VERSION ""

NS_ :

BS_:

BU_: CH DIPF DIPR ETH FC HVI HVS PARTY SDCV VEH VIRT

BO_ 1480 EPBL_alertLog: 8 VEH
 SG_ EPBL_a175_nonterminalReason m175 : 56|5@1+ (1,0) [0|21] ""  gtw
 SG_ EPBL_a248_nonterminalReason m248 : 56|5@1+ (1,0) [0|21] ""  gtw
 SG_ EPBL_a176_nonterminalReason m176 : 56|5@1+ (1,0) [0|21] ""  gtw
 SG_ EPBL_a041_CPULoadNVMMTask m41 : 56|8@1+ (1,0) [0|255] ""  gtw
 SG_ EPBL_a177_nonterminalReason m177 : 56|5@1+ (1,0) [0|21] ""  gtw
 SG_ EPBL_a022_TaskInitError4 m22 : 56|8@1+ (1,0) [0|255] ""  gtw
 SG_ EPBL_a190_nonterminalReason m190 : 56|5@1+ (1,0) [0|21] ""  gtw
 SG_ EPBL_a179_nonterminalReason m179 : 56|5@1+ (1,0) [0|21] ""  gtw
 SG_ EPBL_a174_nonterminalReason m174 : 56|5@1+ (1,0) [0|21] ""  gtw
 SG_ EPBL_a191_nonterminalReason m191 : 56|5@1+ (1,0) [0|21] ""  gtw
 SG_ EPBL_a042_UsageNVMMTask m42 : 56|8@1+ (1,0) [0|255] ""  gtw
 SG_ EPBL_a247_nonterminalReason m247 : 56|5@1+ (1,0) [0|21] ""  gtw
 SG_ EPBL_a138_monitorState m138 : 51|3@1+ (1,0) [0|5] ""  gtw
 SG_ EPBL_a179_esmOpTrigger m179 : 48|5@1+ (1,0) [0|30] ""  gtw
 SG_ EPBL_a000_alertDataW2 m0 : 48|16@1+ (1,0) [0|65535] ""  X
 SG_ EPBL_a022_TaskInitError3 m22 : 48|8@1+ (1,0) [0|255] ""  gtw
 SG_ EPBL_a190_esmOpTrigger m190 : 48|5@1+ (1,0) [0|30] ""  gtw
 SG_ EPBL_a042_UsageUDSTask m42 : 48|8@1+ (1,0) [0|255] ""  gtw
 SG_ EPBL_a248_esmOpTrigger m248 : 48|5@1+ (1,0) [0|30] ""  gtw
 SG_ EPBL_a175_esmOpTrigger m175 : 48|5@1+ (1,0) [0|30] ""  gtw
 SG_ EPBL_a247_esmOpTrigger m247 : 48|5@1+ (1,0) [0|30] ""  gtw
 SG_ EPBL_a191_esmOpTrigger m191 : 48|5@1+ (1,0) [0|30] ""  gtw
 SG_ EPBL_a003_Data m3 : 48|16@1+ (1,0) [0|65535] ""  gtw
 SG_ EPBL_a216_byte3 m216 : 48|8@1+ (1,0) [0|255] ""  gtw
 SG_ EPBL_a176_esmOpTrigger m176 : 48|5@1+ (1,0) [0|30] ""  gtw
 SG_ EPBL_a041_CPULoad1000msTask m41 : 48|8@1+ (1,0) [0|255] ""  gtw
 SG_ EPBL_a138_localState m138 : 48|3@1+ (1,0) [0|5] ""  gtw
 SG_ EPBL_a177_esmOpTrigger m177 : 48|5@1+ (1,0) [0|30] ""  gtw
 SG_ EPBL_a174_esmOpTrigger m174 : 48|5@1+ (1,0) [0|30] ""  gtw
 SG_ EPBL_a183_invalidateReason m183 : 45|2@1+ (1,0) [0|3] ""  gtw
 SG_ EPBL_a063_faulted m63 : 43|1@1+ (1,0) [0|1] ""  gtw
 SG_ EPBL_a063_stuckActive m63 : 42|1@1+ (1,0) [0|1] ""  gtw
 SG_ EPBL_a063_indeterminate m63 : 41|1@1+ (1,0) [0|1] ""  gtw
 SG_ EPBL_a176_csmFaultReason m176 : 40|5@1+ (1,0) [0|21] ""  gtw
 SG_ EPBL_a045_CallTrace1 m45 : 40|24@1+ (1,0) [0|16777215] ""  gtw
 SG_ EPBL_a134_12vFilt m134 : 40|12@1+ (0.005443676098,0) [0|22.29185] "V"  gtw
 SG_ EPBL_a246_esmOpTrigger m246 : 40|5@1+ (1,0) [0|30] ""  gtw
 SG_ EPBL_a170_12vFilt m170 : 40|12@1+ (0.005443676098,0) [0|22.29185] "V"  gtw
 SG_ EPBL_a063_disconnected m63 : 40|1@1+ (1,0) [0|1] ""  gtw
 SG_ EPBL_a042_Usage1000msTask m42 : 40|8@1+ (1,0) [0|255] ""  gtw
 SG_ EPBL_a188_nextState m188 : 40|5@1+ (1,0) [0|19] ""  gtw
 SG_ EPBL_a128_12vFilt m128 : 40|12@1+ (0.005443676098,0) [0|22.29185] "V"  gtw
 SG_ EPBL_a191_csmFaultReason m191 : 40|5@1+ (1,0) [0|21] ""  gtw
 SG_ EPBL_a183_nextState m183 : 40|5@1+ (1,0) [0|19] ""  gtw
 SG_ EPBL_a247_csmFaultReason m247 : 40|5@1+ (1,0) [0|21] ""  gtw
 SG_ EPBL_a137_12vFilt m137 : 40|12@1+ (0.005443676098,0) [0|22.29185] "V"  gtw
 SG_ EPBL_a175_csmFaultReason m175 : 40|5@1+ (1,0) [0|21] ""  gtw
 SG_ EPBL_a189_nextState m189 : 40|5@1+ (1,0) [0|19] ""  gtw
 SG_ EPBL_a046_CallTrace1 m46 : 40|24@1+ (1,0) [0|16777215] ""  gtw
 SG_ EPBL_a216_byte2 m216 : 40|8@1+ (1,0) [0|255] ""  gtw
 SG_ EPBL_a184_nextState m184 : 40|5@1+ (1,0) [0|19] ""  gtw
 SG_ EPBL_a248_csmFaultReason m248 : 40|5@1+ (1,0) [0|21] ""  gtw
 SG_ EPBL_a059_current m59 : 40|12@1+ (0.05,0) [0|204.75] "A"  gtw
 SG_ EPBL_a043_CallTrace1 m43 : 40|24@1+ (1,0) [0|16777215] ""  gtw
 SG_ EPBL_a136_12vFilt m136 : 40|12@1+ (0.005443676098,0) [0|22.29185] "V"  gtw
 SG_ EPBL_a249_esmOpTrigger m249 : 40|5@1+ (1,0) [0|30] ""  gtw
 SG_ EPBL_a190_csmFaultReason m190 : 40|5@1+ (1,0) [0|21] ""  gtw
 SG_ EPBL_a179_csmFaultReason m179 : 40|5@1+ (1,0) [0|21] ""  gtw
 SG_ EPBL_a125_12vFilt m125 : 40|12@1+ (0.005443676098,0) [0|22.29185] "V"  gtw
 SG_ EPBL_a217_byte7 m217 : 40|8@1+ (1,0) [0|255] ""  gtw
 SG_ EPBL_a174_csmFaultReason m174 : 40|5@1+ (1,0) [0|21] ""  gtw
 SG_ EPBL_a180_nextState m180 : 40|5@1+ (1,0) [0|19] ""  gtw
 SG_ EPBL_a044_CallTrace1 m44 : 40|24@1+ (1,0) [0|16777215] ""  gtw
 SG_ EPBL_a177_csmFaultReason m177 : 40|5@1+ (1,0) [0|21] ""  gtw
 SG_ EPBL_a126_12vFilt m126 : 40|12@1+ (0.005443676098,0) [0|22.29185] "V"  gtw
 SG_ EPBL_a041_CPULoad100msTask m41 : 40|8@1+ (1,0) [0|255] ""  gtw
 SG_ EPBL_a186_nextState m186 : 40|5@1+ (1,0) [0|19] ""  gtw
 SG_ EPBL_a022_TaskInitError2 m22 : 40|8@1+ (1,0) [0|255] ""  gtw
 SG_ EPBL_a171_12vFilt m171 : 40|12@1+ (0.005443676098,0) [0|22.29185] "V"  gtw
 SG_ EPBL_a135_12vFilt m135 : 40|12@1+ (0.005443676098,0) [0|22.29185] "V"  gtw
 SG_ EPBL_a187_nextState m187 : 40|5@1+ (1,0) [0|19] ""  gtw
 SG_ EPBL_a127_12vFilt m127 : 40|12@1+ (0.005443676098,0) [0|22.29185] "V"  gtw
 SG_ EPBL_a247_monitorFaultStatus m247 : 37|2@1+ (1,0) [0|3] ""  gtw
 SG_ EPBL_a191_monitorFaultStatus m191 : 37|2@1+ (1,0) [0|3] ""  gtw
 SG_ EPBL_a175_monitorFaultStatus m175 : 37|2@1+ (1,0) [0|3] ""  gtw
 SG_ EPBL_a176_monitorFaultStatus m176 : 37|2@1+ (1,0) [0|3] ""  gtw
 SG_ EPBL_a179_monitorFaultStatus m179 : 37|2@1+ (1,0) [0|3] ""  gtw
 SG_ EPBL_a246_faultStatus m246 : 37|2@1+ (1,0) [0|3] ""  gtw
 SG_ EPBL_a177_monitorFaultStatus m177 : 37|2@1+ (1,0) [0|3] ""  gtw
 SG_ EPBL_a248_monitorFaultStatus m248 : 37|2@1+ (1,0) [0|3] ""  gtw
 SG_ EPBL_a249_faultStatus m249 : 37|2@1+ (1,0) [0|3] ""  gtw
 SG_ EPBL_a190_monitorFaultStatus m190 : 37|2@1+ (1,0) [0|3] ""  gtw
 SG_ EPBL_a174_monitorFaultStatus m174 : 37|2@1+ (1,0) [0|3] ""  gtw
 SG_ EPBL_a183_previousState m183 : 32|5@1+ (1,0) [0|19] ""  gtw
 SG_ EPBL_a186_previousState m186 : 32|5@1+ (1,0) [0|19] ""  gtw
 SG_ EPBL_a063_ADCVoltage m63 : 32|8@1+ (0.025,0) [0|6.375] "V"  gtw
 SG_ EPBL_a179_monitorUnitStatus m179 : 32|5@1+ (1,0) [0|21] ""  gtw
 SG_ EPBL_a042_Usage100msTask m42 : 32|8@1+ (1,0) [0|255] ""  gtw
 SG_ EPBL_a191_monitorUnitStatus m191 : 32|5@1+ (1,0) [0|21] ""  gtw
 SG_ EPBL_a182_temperature m182 : 32|8@1- (0.5,-40) [-40|80] "deg C"  gtw
 SG_ EPBL_a247_monitorUnitStatus m247 : 32|5@1+ (1,0) [0|21] ""  gtw
 SG_ EPBL_a180_previousState m180 : 32|5@1+ (1,0) [0|19] ""  gtw
 SG_ EPBL_a173_csmState m173 : 32|4@1+ (1,0) [0|14] ""  gtw
 SG_ EPBL_a187_previousState m187 : 32|5@1+ (1,0) [0|19] ""  gtw
 SG_ EPBL_a246_esmStateRequest m246 : 32|5@1+ (1,0) [0|19] ""  gtw
 SG_ EPBL_a175_monitorUnitStatus m175 : 32|5@1+ (1,0) [0|21] ""  gtw
 SG_ EPBL_a022_TaskInitError1 m22 : 32|8@1+ (1,0) [0|255] ""  gtw
 SG_ EPBL_a190_monitorUnitStatus m190 : 32|5@1+ (1,0) [0|21] ""  gtw
 SG_ EPBL_a184_previousState m184 : 32|5@1+ (1,0) [0|19] ""  gtw
 SG_ EPBL_a174_monitorUnitStatus m174 : 32|5@1+ (1,0) [0|21] ""  gtw
 SG_ EPBL_a249_esmStateRequest m249 : 32|5@1+ (1,0) [0|19] ""  gtw
 SG_ EPBL_a188_previousState m188 : 32|5@1+ (1,0) [0|19] ""  gtw
 SG_ EPBL_a177_monitorUnitStatus m177 : 32|5@1+ (1,0) [0|21] ""  gtw
 SG_ EPBL_a041_CPULoad10msTask m41 : 32|8@1+ (1,0) [0|255] ""  gtw
 SG_ EPBL_a000_alertDataW1 m0 : 32|16@1+ (1,0) [0|65535] ""  X
 SG_ EPBL_a217_byte6 m217 : 32|8@1+ (1,0) [0|255] ""  gtw
 SG_ EPBL_a248_monitorUnitStatus m248 : 32|5@1+ (1,0) [0|21] ""  gtw
 SG_ EPBL_a176_monitorUnitStatus m176 : 32|5@1+ (1,0) [0|21] ""  gtw
 SG_ EPBL_a003_LineNumber m3 : 32|16@1+ (1,0) [0|65535] ""  gtw
 SG_ EPBL_a189_previousState m189 : 32|5@1+ (1,0) [0|19] ""  gtw
 SG_ EPBL_a216_byte1 m216 : 32|8@1+ (1,0) [0|255] ""  gtw
 SG_ EPBL_a179_faultStatus m179 : 29|2@1+ (1,0) [0|3] ""  gtw
 SG_ EPBL_a191_faultStatus m191 : 29|2@1+ (1,0) [0|3] ""  gtw
 SG_ EPBL_a247_faultStatus m247 : 29|2@1+ (1,0) [0|3] ""  gtw
 SG_ EPBL_a175_faultStatus m175 : 29|2@1+ (1,0) [0|3] ""  gtw
 SG_ EPBL_a190_faultStatus m190 : 29|2@1+ (1,0) [0|3] ""  gtw
 SG_ EPBL_a174_faultStatus m174 : 29|2@1+ (1,0) [0|3] ""  gtw
 SG_ EPBL_a177_faultStatus m177 : 29|2@1+ (1,0) [0|3] ""  gtw
 SG_ EPBL_a248_faultStatus m248 : 29|2@1+ (1,0) [0|3] ""  gtw
 SG_ EPBL_a176_faultStatus m176 : 29|2@1+ (1,0) [0|3] ""  gtw
 SG_ EPBL_a136_nvFilt m136 : 28|12@1+ (0.005443676098,0) [0|22.29185] "V"  gtw
 SG_ EPBL_a128_nvFilt m128 : 28|12@1+ (0.005443676098,0) [0|22.29185] "V"  gtw
 SG_ EPBL_a125_nvFilt m125 : 28|12@1+ (0.005443676098,0) [0|22.29185] "V"  gtw
 SG_ EPBL_a126_nvFilt m126 : 28|12@1+ (0.005443676098,0) [0|22.29185] "V"  gtw
 SG_ EPBL_a135_nvFilt m135 : 28|12@1+ (0.005443676098,0) [0|22.29185] "V"  gtw
 SG_ EPBL_a171_nvFilt m171 : 28|12@1+ (0.005443676098,0) [0|22.29185] "V"  gtw
 SG_ EPBL_a127_nvFilt m127 : 28|12@1+ (0.005443676098,0) [0|22.29185] "V"  gtw
 SG_ EPBL_a059_resistanceEstimate m59 : 28|12@1+ (0.00244,0) [0|9.9918] "Ohms"  gtw
 SG_ EPBL_a134_nvFilt m134 : 28|12@1+ (0.005443676098,0) [0|22.29185] "V"  gtw
 SG_ EPBL_a170_nvFilt m170 : 28|12@1+ (0.005443676098,0) [0|22.29185] "V"  gtw
 SG_ EPBL_a137_nvFilt m137 : 28|12@1+ (0.005443676098,0) [0|22.29185] "V"  gtw
 SG_ EPBL_a021_Task1000msMissed m21 : 27|1@1+ (1,0) [0|1] ""  gtw
 SG_ EPBL_a116_VEH_logging1Hz m116 : 27|1@1+ (1,0) [0|1] ""  gtw
 SG_ EPBL_a242_highCurrent m242 : 26|2@1+ (1,0) [0|3] ""  gtw
 SG_ EPBL_a116_VEH_switchStatus m116 : 26|1@1+ (1,0) [0|1] ""  gtw
 SG_ EPBL_a021_Task1000msStarved m21 : 26|1@1+ (1,0) [0|1] ""  gtw
 SG_ EPBL_a243_brakeDiscWipingActive m243 : 26|1@1+ (1,0) [0|1] ""  gtw
 SG_ EPBL_a241_highCurrent m241 : 26|2@1+ (1,0) [0|3] ""  gtw
 SG_ EPBL_a117_VEH_intrusionSensorSta m117 : 25|1@1+ (1,0) [0|1] ""  gtw
 SG_ EPBL_a021_Task1000msLate m21 : 25|1@1+ (1,0) [0|1] ""  gtw
 SG_ EPBL_a243_vehiclePowerState m243 : 25|1@1+ (1,0) [0|1] ""  gtw
 SG_ EPBL_a116_VEH_restraintStatus m116 : 25|1@1+ (1,0) [0|1] ""  gtw
 SG_ EPBL_a217_byte5 m217 : 24|8@1+ (1,0) [0|255] ""  gtw
 SG_ EPBL_a243_wiperSpeed m243 : 24|1@1+ (1,0) [0|1] ""  gtw
 SG_ EPBL_a189_esmOpTrigger m189 : 24|5@1+ (1,0) [0|30] ""  gtw
 SG_ EPBL_a177_esmStateRequest m177 : 24|5@1+ (1,0) [0|19] ""  gtw
 SG_ EPBL_a242_vehiclePowerState m242 : 24|2@1+ (1,0) [0|3] ""  gtw
 SG_ EPBL_a042_Usage10msTask m42 : 24|8@1+ (1,0) [0|255] ""  gtw
 SG_ EPBL_a184_esmOpTrigger m184 : 24|5@1+ (1,0) [0|30] ""  gtw
 SG_ EPBL_a179_esmStateRequest m179 : 24|5@1+ (1,0) [0|19] ""  gtw
 SG_ EPBL_a187_esmOpTrigger m187 : 24|5@1+ (1,0) [0|30] ""  gtw
 SG_ EPBL_a022_TaskInitError0 m22 : 24|8@1+ (1,0) [0|255] ""  gtw
 SG_ EPBL_a063_switchType m63 : 24|8@1+ (1,0) [0|255] ""  gtw
 SG_ EPBL_a174_esmStateRequest m174 : 24|5@1+ (1,0) [0|19] ""  gtw
 SG_ EPBL_a241_vehiclePowerState m241 : 24|2@1+ (1,0) [0|3] ""  gtw
 SG_ EPBL_a113_VEH_powertrainControl m113 : 24|1@1+ (1,0) [0|1] ""  gtw
 SG_ EPBL_a246_nextState m246 : 24|5@1+ (1,0) [0|19] ""  gtw
 SG_ EPBL_a173_esmStateRequest m173 : 24|5@1+ (1,0) [0|19] ""  gtw
 SG_ EPBL_a120_VEH_speed m120 : 24|1@1+ (1,0) [0|1] ""  gtw
 SG_ EPBL_a118_VEH_systemStatus m118 : 24|1@1+ (1,0) [0|1] ""  gtw
 SG_ EPBL_a117_VEH_switchStatus m117 : 24|1@1+ (1,0) [0|1] ""  gtw
 SG_ EPBL_a116_VEH_seatHeatStatus m116 : 24|1@1+ (1,0) [0|1] ""  gtw
 SG_ EPBL_a190_esmStateRequest m190 : 24|5@1+ (1,0) [0|19] ""  gtw
 SG_ EPBL_a188_esmOpTrigger m188 : 24|5@1+ (1,0) [0|30] ""  gtw
 SG_ EPBL_a182_grade m182 : 24|7@1- (1,0) [-64|63] "%"  gtw
 SG_ EPBL_a175_esmStateRequest m175 : 24|5@1+ (1,0) [0|19] ""  gtw
 SG_ EPBL_a186_esmOpTrigger m186 : 24|5@1+ (1,0) [0|30] ""  gtw
 SG_ EPBL_a248_esmStateRequest m248 : 24|5@1+ (1,0) [0|19] ""  gtw
 SG_ EPBL_a247_esmStateRequest m247 : 24|5@1+ (1,0) [0|19] ""  gtw
 SG_ EPBL_a021_Task100msMissed m21 : 24|1@1+ (1,0) [0|1] ""  gtw
 SG_ EPBL_a191_esmStateRequest m191 : 24|5@1+ (1,0) [0|19] ""  gtw
 SG_ EPBL_a249_nextState m249 : 24|5@1+ (1,0) [0|19] ""  gtw
 SG_ EPBL_a216_byte0 m216 : 24|8@1+ (1,0) [0|255] ""  gtw
 SG_ EPBL_a300_subUsageId m300 : 24|5@1+ (1,0) [0|19] ""  gtw
 SG_ EPBL_a041_CPULoad1msTask m41 : 24|8@1+ (1,0) [0|255] ""  gtw
 SG_ EPBL_a141_toState m141 : 24|5@1+ (1,0) [0|19] ""  gtw
 SG_ EPBL_a176_esmStateRequest m176 : 24|5@1+ (1,0) [0|19] ""  gtw
 SG_ EPBL_a180_esmOpTrigger m180 : 24|5@1+ (1,0) [0|30] ""  gtw
 SG_ EPBL_a183_esmOpTrigger m183 : 24|5@1+ (1,0) [0|30] ""  gtw
 SG_ EPBL_a116_VEH_doorStatus m116 : 23|1@1+ (1,0) [0|1] ""  gtw
 SG_ EPBL_a243_thermistorTMin m243 : 23|1@1+ (1,0) [0|1] ""  gtw
 SG_ EPBL_a118_VEH_12VBattStatus m118 : 23|1@1+ (1,0) [0|1] ""  gtw
 SG_ EPBL_a117_VEH_doorStatus m117 : 23|1@1+ (1,0) [0|1] ""  gtw
 SG_ EPBL_a021_Task100msStarved m21 : 23|1@1+ (1,0) [0|1] ""  gtw
 SG_ EPBL_a113_VEH_chassisControl m113 : 23|1@1+ (1,0) [0|1] ""  gtw
 SG_ EPBL_a120_PARTY_speed m120 : 23|1@1+ (1,0) [0|1] ""  gtw
 SG_ EPBL_a120_VEH_status m120 : 22|1@1+ (1,0) [0|1] ""  gtw
 SG_ EPBL_a117_VEH_seatStatus m117 : 22|1@1+ (1,0) [0|1] ""  gtw
 SG_ EPBL_a243_tempAmbient m243 : 22|1@1+ (1,0) [0|1] ""  gtw
 SG_ EPBL_a116_VEH_thsStatus m116 : 22|1@1+ (1,0) [0|1] ""  gtw
 SG_ EPBL_a113_VEH_ventCntlReq m113 : 22|1@1+ (1,0) [0|1] ""  gtw
 SG_ EPBL_a021_Task100msLate m21 : 22|1@1+ (1,0) [0|1] ""  gtw
 SG_ EPBL_a118_VEH_vehicleStatus m118 : 22|1@1+ (1,0) [0|1] ""  gtw
 SG_ EPBL_a021_Task10msMissed m21 : 21|1@1+ (1,0) [0|1] ""  gtw
 SG_ EPBL_a113_VEH_solarData m113 : 21|1@1+ (1,0) [0|1] ""  gtw
 SG_ EPBL_a015_NVMMWriteFailed m15 : 21|1@1+ (1,0) [0|1] ""  gtw
 SG_ EPBL_a116_VEH_seatStatus m116 : 21|1@1+ (1,0) [0|1] ""  gtw
 SG_ EPBL_a118_VEH_LVPowerState m118 : 21|1@1+ (1,0) [0|1] ""  gtw
 SG_ EPBL_a012_ExternalReset m12 : 21|1@1+ (1,0) [0|1] ""  gtw
 SG_ EPBL_a117_VEH_lightStatus m117 : 21|1@1+ (1,0) [0|1] ""  gtw
 SG_ EPBL_a243_vehicleSpeed m243 : 21|1@1+ (1,0) [0|1] ""  gtw
 SG_ EPBL_a120_PARTY_locStatus m120 : 21|1@1+ (1,0) [0|1] ""  gtw
 SG_ EPBL_a107_VEH_bmbMinMax m107 : 20|1@1+ (1,0) [0|1] ""  gtw
 SG_ EPBL_a021_Task10msStarved m21 : 20|1@1+ (1,0) [0|1] ""  gtw
 SG_ EPBL_a120_VEH_torque m120 : 20|1@1+ (1,0) [0|1] ""  gtw
 SG_ EPBL_a012_DebugReset m12 : 20|1@1+ (1,0) [0|1] ""  gtw
 SG_ EPBL_a015_NVMMMemOverflow m15 : 20|1@1+ (1,0) [0|1] ""  gtw
 SG_ EPBL_a118_VEH_okToUseHighPwr m118 : 20|1@1+ (1,0) [0|1] ""  gtw
 SG_ EPBL_a113_VEH_vehicleControl2 m113 : 20|1@1+ (1,0) [0|1] ""  gtw
 SG_ EPBL_a117_VEH_restraintStatus m117 : 20|1@1+ (1,0) [0|1] ""  gtw
 SG_ EPBL_a116_VEH_lightStatus m116 : 20|1@1+ (1,0) [0|1] ""  gtw
 SG_ EPBL_a243_DIStorqueActual m243 : 20|1@1+ (1,0) [0|1] ""  gtw
 SG_ EPBL_a242_hvState m242 : 20|3@1+ (1,0) [0|6] ""  gtw
 SG_ EPBL_a216_monitor_MIA m216 : 19|1@1+ (1,0) [0|1] ""  gtw
 SG_ EPBL_a104_PARTY_control m104 : 19|1@1+ (1,0) [0|1] ""  gtw
 SG_ EPBL_a117_VEH_LVPowerState m117 : 19|1@1+ (1,0) [0|1] ""  gtw
 SG_ EPBL_a120_PARTY_torque m120 : 19|1@1+ (1,0) [0|1] ""  gtw
 SG_ EPBL_a109_PARTY_collision m109 : 19|1@1+ (1,0) [0|1] ""  gtw
 SG_ EPBL_a118_VEH_status m118 : 19|1@1+ (1,0) [0|1] ""  gtw
 SG_ EPBL_a108_PARTY_torque m108 : 19|1@1+ (1,0) [0|1] ""  gtw
 SG_ EPBL_a113_VEH_vehicleControl m113 : 19|1@1+ (1,0) [0|1] ""  gtw
 SG_ EPBL_a243_DItorqueActual m243 : 19|1@1+ (1,0) [0|1] ""  gtw
 SG_ EPBL_a242_contCurrentState m242 : 19|1@1+ (1,0) [0|1] ""  gtw
 SG_ EPBL_a116_VEH_LVPowerState m116 : 19|1@1+ (1,0) [0|1] ""  gtw
 SG_ EPBL_a012_CheckstopReset m12 : 19|1@1+ (1,0) [0|1] ""  gtw
 SG_ EPBL_a114_PARTY_party3 m114 : 19|1@1+ (1,0) [0|1] ""  gtw
 SG_ EPBL_a178_monitorCaliperState m178 : 19|3@1+ (1,0) [0|5] ""  gtw
 SG_ EPBL_a021_Task10msLate m21 : 19|1@1+ (1,0) [0|1] ""  gtw
 SG_ EPBL_a241_epbSysStatus m241 : 19|4@1+ (1,0) [0|8] ""  gtw
 SG_ EPBL_a107_VEH_thermalStatus m107 : 19|1@1+ (1,0) [0|1] ""  gtw
 SG_ EPBL_a015_NVMMRecordUpgraded m15 : 19|1@1+ (1,0) [0|1] ""  gtw
 SG_ EPBL_a120_PARTY_systemStatus m120 : 18|1@1+ (1,0) [0|1] ""  gtw
 SG_ EPBL_a106_VEH_thermalStatus m106 : 18|1@1+ (1,0) [0|1] ""  gtw
 SG_ EPBL_a012_SoftwareReset m12 : 18|1@1+ (1,0) [0|1] ""  gtw
 SG_ EPBL_a109_PARTY_nearDeploy m109 : 18|1@1+ (1,0) [0|1] ""  gtw
 SG_ EPBL_a189_monitorCDPStatus m189 : 18|2@1+ (1,0) [0|2] ""  gtw
 SG_ EPBL_a186_monitorCDPStatus m186 : 18|2@1+ (1,0) [0|2] ""  gtw
 SG_ EPBL_a216_CRC_error m216 : 18|1@1+ (1,0) [0|1] ""  gtw
 SG_ EPBL_a102_VEH_sensorStatus m102 : 18|1@1+ (1,0) [0|1] ""  gtw
 SG_ EPBL_a108_VEH_torque m108 : 18|1@1+ (1,0) [0|1] ""  gtw
 SG_ EPBL_a183_monitorCDPStatus m183 : 18|2@1+ (1,0) [0|2] ""  gtw
 SG_ EPBL_a104_VEH_thermalStatus m104 : 18|1@1+ (1,0) [0|1] ""  gtw
 SG_ EPBL_a180_monitorCDPStatus m180 : 18|2@1+ (1,0) [0|2] ""  gtw
 SG_ EPBL_a107_VEH_status m107 : 18|1@1+ (1,0) [0|1] ""  gtw
 SG_ EPBL_a113_VEH_chargeRequest m113 : 18|1@1+ (1,0) [0|1] ""  gtw
 SG_ EPBL_a119_VEH_rightStalk m119 : 18|1@1+ (1,0) [0|1] ""  gtw
 SG_ EPBL_a021_Task1msMissed m21 : 18|1@1+ (1,0) [0|1] ""  gtw
 SG_ EPBL_a187_monitorCDPStatus m187 : 18|2@1+ (1,0) [0|2] ""  gtw
 SG_ EPBL_a110_VEH_time m110 : 18|1@1+ (1,0) [0|1] ""  gtw
 SG_ EPBL_a243_drivetrainType m243 : 18|1@1+ (1,0) [0|1] ""  gtw
 SG_ EPBL_a118_VEH_sensors m118 : 18|1@1+ (1,0) [0|1] ""  gtw
 SG_ EPBL_a184_monitorCDPStatus m184 : 18|2@1+ (1,0) [0|2] ""  gtw
 SG_ EPBL_a103_VEH_status m103 : 18|1@1+ (1,0) [0|1] ""  gtw
 SG_ EPBL_a015_NVMMVersionMismatch m15 : 18|1@1+ (1,0) [0|1] ""  gtw
 SG_ EPBL_a116_VEH_hvacRequest m116 : 18|1@1+ (1,0) [0|1] ""  gtw
 SG_ EPBL_a114_VEH_wheelSpeeds m114 : 18|1@1+ (1,0) [0|1] ""  gtw
 SG_ EPBL_a242_contDesiredState m242 : 18|1@1+ (1,0) [0|1] ""  gtw
 SG_ EPBL_a188_monitorCDPStatus m188 : 18|2@1+ (1,0) [0|2] ""  gtw
 SG_ EPBL_a241_diKeepAlive m241 : 18|1@1+ (1,0) [0|1] ""  gtw
 SG_ EPBL_a117_VEH_hvacBlowerFdb m117 : 18|1@1+ (1,0) [0|1] ""  gtw
 SG_ EPBL_a109_PARTY_inertial2 m109 : 17|1@1+ (1,0) [0|1] ""  gtw
 SG_ EPBL_a201_epbHWBrakeType m201 : 17|2@1+ (1,0) [0|2] ""  gtw
 SG_ EPBL_a111_VEH_status m111 : 17|1@1+ (1,0) [0|1] ""  gtw
 SG_ EPBL_a098_VEH_temperature m98 : 17|1@1+ (1,0) [0|1] ""  gtw
 SG_ EPBL_a108_VEH_thermalControl m108 : 17|1@1+ (1,0) [0|1] ""  gtw
 SG_ EPBL_a114_PARTY_wheelSpeeds m114 : 17|1@1+ (1,0) [0|1] ""  gtw
 SG_ EPBL_a118_VEH_lighting m118 : 17|1@1+ (1,0) [0|1] ""  gtw
 SG_ EPBL_a112_VEH_status m112 : 17|1@1+ (1,0) [0|1] ""  gtw
 SG_ EPBL_a113_VEH_hvacRequest m113 : 17|1@1+ (1,0) [0|1] ""  gtw
 SG_ EPBL_a107_VEH_vehNm m107 : 17|1@1+ (1,0) [0|1] ""  gtw
 SG_ EPBL_a010_UnderVoltageTimeout m10 : 17|1@1+ (1,0) [0|1] ""  gtw
 SG_ EPBL_a243_brakeMasterCylPressQF m243 : 17|1@1+ (1,0) [0|1] ""  gtw
 SG_ EPBL_a104_VEH_bodyControls m104 : 17|1@1+ (1,0) [0|1] ""  gtw
 SG_ EPBL_a097_VEH_state m97 : 17|1@1+ (1,0) [0|1] ""  gtw
 SG_ EPBL_a110_VEH_carConfig m110 : 17|1@1+ (1,0) [0|1] ""  gtw
 SG_ EPBL_a120_VEH_systemStatus m120 : 17|1@1+ (1,0) [0|1] ""  gtw
 SG_ EPBL_a117_VEH_vehNm m117 : 17|1@1+ (1,0) [0|1] ""  gtw
 SG_ EPBL_a012_FlashError m12 : 17|1@1+ (1,0) [0|1] ""  gtw
 SG_ EPBL_a241_currentState m241 : 17|1@1+ (1,0) [0|1] ""  gtw
 SG_ EPBL_a115_VEH_authentication m115 : 17|1@1+ (1,0) [0|1] ""  gtw
 SG_ EPBL_a002_PowerOnReset m2 : 17|1@1+ (1,0) [0|1] ""  gtw
 SG_ EPBL_a013_ClearQueueFull m13 : 17|1@1+ (1,0) [0|1] ""  gtw
 SG_ EPBL_a015_NVMMCRCMismatch m15 : 17|1@1+ (1,0) [0|1] ""  gtw
 SG_ EPBL_a021_Task1msStarved m21 : 17|1@1+ (1,0) [0|1] ""  gtw
 SG_ EPBL_a116_VEH_vehNm m116 : 17|1@1+ (1,0) [0|1] ""  gtw
 SG_ EPBL_a060_resetUnlocked m60 : 17|1@1+ (1,0) [0|1] ""  gtw
 SG_ EPBL_a102_VEH_feedbackStatus m102 : 17|1@1+ (1,0) [0|1] ""  gtw
 SG_ EPBL_a106_VEH_thermalControl m106 : 17|1@1+ (1,0) [0|1] ""  gtw
 SG_ EPBL_a100_PARTY m100 : 17|1@1+ (1,0) [0|1] ""  gtw
 SG_ EPBL_a242_hvcCurrentState m242 : 17|1@1+ (1,0) [0|1] ""  gtw
 SG_ EPBL_a119_VEH_leftStalk m119 : 17|1@1+ (1,0) [0|1] ""  gtw
 SG_ EPBL_a105_VEH_chNm m105 : 17|1@1+ (1,0) [0|1] ""  gtw
 SG_ EPBL_a216_spiFault m216 : 17|1@1+ (1,0) [0|1] ""  gtw
 SG_ EPBL_a103_VEH_vehNm m103 : 17|1@1+ (1,0) [0|1] ""  gtw
 SG_ EPBL_a101_VEH_state m101 : 16|1@1+ (1,0) [0|1] ""  gtw
 SG_ EPBL_a179_esmState m179 : 16|5@1+ (1,0) [0|19] ""  gtw
 SG_ EPBL_a110_VEH_carState m110 : 16|1@1+ (1,0) [0|1] ""  gtw
 SG_ EPBL_a012_ClockError m12 : 16|1@1+ (1,0) [0|1] ""  gtw
 SG_ EPBL_a105_VEH_states m105 : 16|1@1+ (1,0) [0|1] ""  gtw
 SG_ EPBL_a107_VEH_hvsNm m107 : 16|1@1+ (1,0) [0|1] ""  gtw
 SG_ EPBL_a126_pvFilt m126 : 16|12@1+ (0.005443676098,0) [0|22.29185] "V"  gtw
 SG_ EPBL_a003_AssertID m3 : 16|16@1+ (1,0) [0|65535] ""  gtw
 SG_ EPBL_a188_espCDPStatus m188 : 16|2@1+ (1,0) [0|2] ""  gtw
 SG_ EPBL_a190_esmState m190 : 16|5@1+ (1,0) [0|19] ""  gtw
 SG_ EPBL_a108_VEH_temperature m108 : 16|1@1+ (1,0) [0|1] ""  gtw
 SG_ EPBL_a046_CallTrace0 m46 : 16|24@1+ (1,0) [0|16777215] ""  gtw
 SG_ EPBL_a115_VEH_vehNm m115 : 16|1@1+ (1,0) [0|1] ""  gtw
 SG_ EPBL_a119_VEH_steerAngle m119 : 16|1@1+ (1,0) [0|1] ""  gtw
 SG_ EPBL_a116_PARTY_epbmStatus m116 : 16|1@1+ (1,0) [0|1] ""  gtw
 SG_ EPBL_a098_VEH_thermalControl m98 : 16|1@1+ (1,0) [0|1] ""  gtw
 SG_ EPBL_a114_PARTY_status m114 : 16|1@1+ (1,0) [0|1] ""  gtw
 SG_ EPBL_a173_esmState m173 : 16|5@1+ (1,0) [0|19] ""  gtw
 SG_ EPBL_a104_VEH_chNm m104 : 16|1@1+ (1,0) [0|1] ""  gtw
 SG_ EPBL_a249_previousState m249 : 16|5@1+ (1,0) [0|19] ""  gtw
 SG_ EPBL_a042_Usage1msTask m42 : 16|8@1+ (1,0) [0|255] ""  gtw
 SG_ EPBL_a186_espCDPStatus m186 : 16|2@1+ (1,0) [0|2] ""  gtw
 SG_ EPBL_a045_CallTrace0 m45 : 16|24@1+ (1,0) [0|16777215] ""  gtw
 SG_ EPBL_a030_logId m30 : 16|4@1+ (1,0) [0|15] ""  gtw
 SG_ EPBL_a100_VEH m100 : 16|1@1+ (1,0) [0|1] ""  gtw
 SG_ EPBL_a015_NVMMRecordNotFound m15 : 16|1@1+ (1,0) [0|1] ""  gtw
 SG_ EPBL_a217_byte4 m217 : 16|8@1+ (1,0) [0|255] ""  gtw
 SG_ EPBL_a248_esmState m248 : 16|5@1+ (1,0) [0|19] ""  gtw
 SG_ EPBL_a128_pvFilt m128 : 16|12@1+ (0.005443676098,0) [0|22.29185] "V"  gtw
 SG_ EPBL_a120_PARTY_chassisCntl m120 : 16|1@1+ (1,0) [0|1] ""  gtw
 SG_ EPBL_a134_pvFilt m134 : 16|12@1+ (0.005443676098,0) [0|22.29185] "V"  gtw
 SG_ EPBL_a183_espCDPStatus m183 : 16|2@1+ (1,0) [0|2] ""  gtw
 SG_ EPBL_a170_pvFilt m170 : 16|12@1+ (0.005443676098,0) [0|22.29185] "V"  gtw
 SG_ EPBL_a175_esmState m175 : 16|5@1+ (1,0) [0|19] ""  gtw
 SG_ EPBL_a103_VEH_hvsNm m103 : 16|1@1+ (1,0) [0|1] ""  gtw
 SG_ EPBL_a138_stateTime m138 : 16|32@1+ (1,0) [0|4294967295] ""  gtw
 SG_ EPBL_a241_desiredState m241 : 16|1@1+ (1,0) [0|1] ""  gtw
 SG_ EPBL_a112_VEH_internalStatus m112 : 16|1@1+ (1,0) [0|1] ""  gtw
 SG_ EPBL_a247_esmState m247 : 16|5@1+ (1,0) [0|19] ""  gtw
 SG_ EPBL_a113_VEH_ethNm m113 : 16|1@1+ (1,0) [0|1] ""  gtw
 SG_ EPBL_a127_pvFilt m127 : 16|12@1+ (0.005443676098,0) [0|22.29185] "V"  gtw
 SG_ EPBL_a191_esmState m191 : 16|5@1+ (1,0) [0|19] ""  gtw
 SG_ EPBL_a010_UnderVoltageDetected m10 : 16|1@1+ (1,0) [0|1] ""  gtw
 SG_ EPBL_a189_espCDPStatus m189 : 16|2@1+ (1,0) [0|2] ""  gtw
 SG_ EPBL_a021_Task1msLate m21 : 16|1@1+ (1,0) [0|1] ""  gtw
 SG_ EPBL_a242_hvcDesiredState m242 : 16|1@1+ (1,0) [0|1] ""  gtw
 SG_ EPBL_a123_filteredCurrentCal m123 : 16|12@1+ (0.01,0) [0|40.95] "A"  gtw
 SG_ EPBL_a102_VEH_faults m102 : 16|1@1+ (1,0) [0|1] ""  gtw
 SG_ EPBL_a111_VEH_internalStatus m111 : 16|1@1+ (1,0) [0|1] ""  gtw
 SG_ EPBL_a187_espCDPStatus m187 : 16|2@1+ (1,0) [0|2] ""  gtw
 SG_ EPBL_a099_VEH_oocStatus m99 : 16|1@1+ (1,0) [0|1] ""  gtw
 SG_ EPBL_a060_lockoutDisabled m60 : 16|1@1+ (1,0) [0|1] ""  gtw
 SG_ EPBL_a001_InternalWatchdog m1 : 16|1@1+ (1,0) [0|1] ""  gtw
 SG_ EPBL_a044_CallTrace0 m44 : 16|24@1+ (1,0) [0|16777215] ""  gtw
 SG_ EPBL_a064_busBitField m64 : 16|8@1+ (1,0) [0|255] ""  gtw
 SG_ EPBL_a180_espCDPStatus m180 : 16|2@1+ (1,0) [0|2] ""  gtw
 SG_ EPBL_a137_pvFilt m137 : 16|12@1+ (0.005443676098,0) [0|22.29185] "V"  gtw
 SG_ EPBL_a176_esmState m176 : 16|5@1+ (1,0) [0|19] ""  gtw
 SG_ EPBL_a043_CallTrace0 m43 : 16|24@1+ (1,0) [0|16777215] ""  gtw
 SG_ EPBL_a178_localCaliperState m178 : 16|3@1+ (1,0) [0|5] ""  gtw
 SG_ EPBL_a013_LogQueueFull m13 : 16|1@1+ (1,0) [0|1] ""  gtw
 SG_ EPBL_a022_TaskInitErrorCount m22 : 16|8@1+ (1,0) [0|255] ""  gtw
 SG_ EPBL_a063_switchChannel m63 : 16|8@1+ (1,0) [0|255] ""  gtw
 SG_ EPBL_a216_noData m216 : 16|1@1+ (1,0) [0|1] ""  gtw
 SG_ EPBL_a118_VEH_vehNm m118 : 16|1@1+ (1,0) [0|1] ""  gtw
 SG_ EPBL_a182_epbSysStatus m182 : 16|4@1+ (1,0) [0|8] ""  gtw
 SG_ EPBL_a000_alertDataW0 m0 : 16|16@1+ (1,0) [0|65535] ""  X
 SG_ EPBL_a251_currentVariance m251 : 16|12@1+ (0.01,0) [0|40.95] "A"  gtw
 SG_ EPBL_a041_CPULoadTotal m41 : 16|8@1+ (1,0) [0|255] ""  gtw
 SG_ EPBL_a122_filteredCurrentCal m122 : 16|12@1+ (0.01,0) [0|40.95] "A"  gtw
 SG_ EPBL_a125_pvFilt m125 : 16|12@1+ (0.005443676098,0) [0|22.29185] "V"  gtw
 SG_ EPBL_a124_calOutOfBoundsData m124 : 16|1@1+ (1,0) [0|1] ""  gtw
 SG_ EPBL_a106_VEH_dcdcStatus m106 : 16|1@1+ (1,0) [0|1] ""  gtw
 SG_ EPBL_a059_voltageDrop m59 : 16|12@1+ (0.005443676098,0) [0|22.29185] "V"  gtw
 SG_ EPBL_a243_brakeMasterCylPress m243 : 16|1@1+ (1,0) [0|1] ""  gtw
 SG_ EPBL_a201_gtwHWBrakeType m201 : 16|1@1+ (1,0) [0|1] ""  gtw
 SG_ EPBL_a184_espCDPStatus m184 : 16|2@1+ (1,0) [0|2] ""  gtw
 SG_ EPBL_a097_VEH_HVStatus m97 : 16|1@1+ (1,0) [0|1] ""  gtw
 SG_ EPBL_a117_PARTY_epbmStatus m117 : 16|1@1+ (1,0) [0|1] ""  gtw
 SG_ EPBL_a181_grade m181 : 16|7@1+ (1,0) [0|127] "%"  gtw
 SG_ EPBL_a121_caliperState m121 : 16|4@1+ (1,0) [0|14] ""  gtw
 SG_ EPBL_a177_esmState m177 : 16|5@1+ (1,0) [0|19] ""  gtw
 SG_ EPBL_a136_pvFilt m136 : 16|12@1+ (0.005443676098,0) [0|22.29185] "V"  gtw
 SG_ EPBL_a141_fromState m141 : 16|5@1+ (1,0) [0|19] ""  gtw
 SG_ EPBL_a109_PARTY_status m109 : 16|1@1+ (1,0) [0|1] ""  gtw
 SG_ EPBL_a185_summonFaultReason m185 : 16|5@1+ (1,0) [0|28] ""  gtw
 SG_ EPBL_a174_esmState m174 : 16|5@1+ (1,0) [0|19] ""  gtw
 SG_ EPBL_a135_pvFilt m135 : 16|12@1+ (0.005443676098,0) [0|22.29185] "V"  gtw
 SG_ EPBL_a171_pvFilt m171 : 16|12@1+ (0.005443676098,0) [0|22.29185] "V"  gtw
 SG_ EPBL_a300_harnessId m300 : 16|5@1+ (1,0) [0|19] ""  gtw
 SG_ EPBL_a246_previousState m246 : 16|5@1+ (1,0) [0|19] ""  gtw
 SG_ EPBL_a002_CPUUndervoltage m2 : 16|1@1+ (1,0) [0|1] ""  gtw
 SG_ EPBL_alertType : 15|1@1+ (1,0) [0|1] ""  gtw
 SG_ EPBL_alertID M : 0|9@1+ (1,0) [0|300] ""  gtw

BO_ 1320 GTW_time: 4 VEH
 SG_ GTW_timeSecs : 7|32@0+ (1,0) [0|4294967295] "s"  di

BO_ 854 DI_alertMatrix1: 8 VEH
 SG_ DI_a064_torqueIntervention : 63|1@1+ (1,0) [0|1] ""  gtw
 SG_ DI_a063_systemGracefulPowerOff : 62|1@1+ (1,0) [0|1] ""  gtw
 SG_ DI_a062_systemLimpMode : 61|1@1+ (1,0) [0|1] ""  gtw
 SG_ DI_a061_heatsinkSensor : 60|1@1+ (1,0) [0|1] ""  gtw
 SG_ DI_a060_heatsinkUT : 59|1@1+ (1,0) [0|1] ""  gtw
 SG_ DI_a059_heatsinkOT : 58|1@1+ (1,0) [0|1] ""  gtw
 SG_ DI_a058_ambientSensor : 57|1@1+ (1,0) [0|1] ""  gtw
 SG_ DI_a057_ambientUT : 56|1@1+ (1,0) [0|1] ""  gtw
 SG_ DI_a056_ambientOT : 55|1@1+ (1,0) [0|1] ""  gtw
 SG_ DI_a055_trqCrossCheck : 54|1@1+ (1,0) [0|1] ""  gtw
 SG_ DI_a054_driveInverterOT : 53|1@1+ (1,0) [0|1] ""  gtw
 SG_ DI_a051_batteryOvercurrent : 50|1@1+ (1,0) [0|1] ""  gtw
 SG_ DI_a050_noStatorSensor : 49|1@1+ (1,0) [0|1] ""  gtw
 SG_ DI_a047_statorSensor1 : 46|1@1+ (1,0) [0|1] ""  gtw
 SG_ DI_a046_statorOT : 45|1@1+ (1,0) [0|1] ""  gtw
 SG_ DI_a045_outletSensor : 44|1@1+ (1,0) [0|1] ""  gtw
 SG_ DI_a044_outletUT : 43|1@1+ (1,0) [0|1] ""  gtw
 SG_ DI_a043_outletOT : 42|1@1+ (1,0) [0|1] ""  gtw
 SG_ DI_a042_inletSensor : 41|1@1+ (1,0) [0|1] ""  gtw
 SG_ DI_a041_driverBrakeApplyCheck : 40|1@1+ (1,0) [0|1] ""  gtw
 SG_ DI_a040_disMIA : 39|1@1+ (1,0) [0|1] ""  gtw
 SG_ DI_a039_noRegen : 38|1@1+ (1,0) [0|1] ""  gtw
 SG_ DI_a038_busVsensor : 37|1@1+ (1,0) [0|1] ""  gtw
 SG_ DI_a037_busUV : 36|1@1+ (1,0) [0|1] ""  gtw
 SG_ DI_a036_busOV : 35|1@1+ (1,0) [0|1] ""  gtw
 SG_ DI_a035_phaseCurrentBalance : 34|1@1+ (1,0) [0|1] ""  gtw
 SG_ DI_a034_phaseBcurrentSensor : 33|1@1+ (1,0) [0|1] ""  gtw
 SG_ DI_a033_phaseAcurrentSensor : 32|1@1+ (1,0) [0|1] ""  gtw
 SG_ DI_a032_phaseBcurrentOffset : 31|1@1+ (1,0) [0|1] ""  gtw
 SG_ DI_a031_phaseAcurrentOffset : 30|1@1+ (1,0) [0|1] ""  gtw
 SG_ DI_a030_phaseCrms : 29|1@1+ (1,0) [0|1] ""  gtw
 SG_ DI_a029_phaseBrms : 28|1@1+ (1,0) [0|1] ""  gtw
 SG_ DI_a028_phaseArms : 27|1@1+ (1,0) [0|1] ""  gtw
 SG_ DI_a027_phaseCpeak : 26|1@1+ (1,0) [0|1] ""  gtw
 SG_ DI_a026_phaseBpeak : 25|1@1+ (1,0) [0|1] ""  gtw
 SG_ DI_a025_phaseApeak : 24|1@1+ (1,0) [0|1] ""  gtw
 SG_ DI_a024_selfTest : 23|1@1+ (1,0) [0|1] ""  gtw
 SG_ DI_a023_carNotParked : 22|1@1+ (1,0) [0|1] ""  gtw
 SG_ DI_a022_hw5vSupplyUV : 21|1@1+ (1,0) [0|1] ""  gtw
 SG_ DI_a021_hwBusOV : 20|1@1+ (1,0) [0|1] ""  gtw
 SG_ DI_a020_hwMotorEncoder : 19|1@1+ (1,0) [0|1] ""  gtw
 SG_ DI_a019_hwAccelPedalPower : 18|1@1+ (1,0) [0|1] ""  gtw
 SG_ DI_a018_hw12vSupplyUV : 17|1@1+ (1,0) [0|1] ""  gtw
 SG_ DI_a017_hwPedalMonitor : 16|1@1+ (1,0) [0|1] ""  gtw
 SG_ DI_a016_safeStateApplied : 15|1@1+ (1,0) [0|1] ""  gtw
 SG_ DI_a015_immobilizer : 14|1@1+ (1,0) [0|1] ""  gtw
 SG_ DI_a014_activeDamping : 13|1@1+ (1,0) [0|1] ""  gtw
 SG_ DI_a012_accel5VSupply : 11|1@1+ (1,0) [0|1] ""  gtw
 SG_ DI_a011_swPowerStageNotReady : 10|1@1+ (1,0) [0|1] ""  gtw
 SG_ DI_a009_hwEncoderB : 8|1@1+ (1,0) [0|1] ""  gtw
 SG_ DI_a008_hwEncoderA : 7|1@1+ (1,0) [0|1] ""  gtw
 SG_ DI_a007_hwHvilNotPresent : 6|1@1+ (1,0) [0|1] ""  gtw
 SG_ DI_a006_hwPhaseCpeak : 5|1@1+ (1,0) [0|1] ""  gtw
 SG_ DI_a005_hwPhaseBpeak : 4|1@1+ (1,0) [0|1] ""  gtw
 SG_ DI_a004_hwPhaseApeak : 3|1@1+ (1,0) [0|1] ""  gtw
 SG_ DI_a003_hwPhaseCgateDrive : 2|1@1+ (1,0) [0|1] ""  gtw
 SG_ DI_a002_hwPhaseBgateDrive : 1|1@1+ (1,0) [0|1] ""  gtw
 SG_ DI_a001_hwPhaseAgateDrive : 0|1@1+ (1,0) [0|1] ""  gtw

BO_ 882 BMS_log1: 8 VEH
 SG_ BMS_1kHzTask_cpuUsage m0 : 50|14@1+ (0.01,0) [0|163.83] "%"  gtw
 SG_ BMS_cpuUsage_hviTx m1 : 50|14@1+ (0.01,0) [0|163.83] "%"  gtw
 SG_ BMS_posCtrDropCorrectedFilt m5 : 48|16@1- (0.000152597199762,0) [-5|5] "V"  gtw
 SG_ BMS_negCtrDropCorrectedFilt m7 : 48|16@1- (0.000152597199762,0) [-5|5] "V"  gtw
 SG_ BMS_negCtrDropCorrected m6 : 48|16@1- (0.000152597199762,0) [-5|5] "V"  gtw
 SG_ BMS_posCtrDropCorrected m4 : 48|16@1- (0.000152597199762,0) [-5|5] "V"  gtw
 SG_ BMS_100HzTask_cpuUsage m0 : 36|14@1+ (0.01,0) [0|163.83] "%"  gtw
 SG_ BMS_cpuUsage_hvsTx m1 : 36|14@1+ (0.01,0) [0|163.83] "%"  gtw
 SG_ BMS_posCtrDeviationConfidence m4 : 32|16@1+ (1.5259254505e-05,0) [0|1] "-"  gtw
 SG_ BMS_negCtrDeviationConfidence m6 : 32|16@1+ (1.5259254505e-05,0) [0|1] "-"  gtw
 SG_ BMS_posCtrDeviationFiltConf m5 : 32|16@1+ (1.5259254505e-05,0) [0|1] "-"  gtw
 SG_ BMS_negCtrDeviationFiltConf m7 : 32|16@1+ (1.5259254505e-05,0) [0|1] "-"  gtw
 SG_ BMS_cpuUsage_canRx m2 : 24|14@1+ (0.01,0) [0|163.83] "%"  gtw
 SG_ BMS_10HzTask_cpuUsage m0 : 22|14@1+ (0.01,0) [0|163.83] "%"  gtw
 SG_ BMS_cpuUsage_vehTx m1 : 22|14@1+ (0.01,0) [0|163.83] "%"  gtw
 SG_ BMS_posCtrDeviationFilt m5 : 16|16@1- (0.000152597199762,0) [-5|5] "V"  gtw
 SG_ BMS_negCtrDeviationFilt m7 : 16|16@1- (0.000152597199762,0) [-5|5] "V"  gtw
 SG_ BMS_posCtrDeviation m4 : 16|16@1- (0.000152597199762,0) [-5|5] "V"  gtw
 SG_ BMS_negCtrDeviation m6 : 16|16@1- (0.000152597199762,0) [-5|5] "V"  gtw
 SG_ BMS_pcsIsolatorEnabled m3 : 15|1@1+ (1,0) [0|1] ""  gtw
 SG_ BMS_fcCtrCleaningActiveNow m3 : 14|1@1+ (1,0) [0|1] ""  gtw
 SG_ BMS_vshFailure m3 : 13|1@1+ (1,0) [0|1] ""  gtw
 SG_ BMS_vshTestAllowed m3 : 12|1@1+ (1,0) [0|1] ""  gtw
 SG_ BMS_vshTestNeeded m3 : 11|1@1+ (1,0) [0|1] ""  gtw
 SG_ BMS_ctrHealthStatsToggle m5 : 8|1@1+ (1,0) [0|1] ""  gtw
 SG_ BMS_balanceState m3 : 8|3@1+ (1,0) [0|6] ""  gtw
 SG_ BMS_appIdleTask_cpuUsage m2 : 8|14@1+ (0.01,0) [0|163.83] "%"  gtw
 SG_ BMS_1HzTask_cpuUsage m0 : 8|14@1+ (0.01,0) [0|163.83] "%"  gtw
 SG_ BMS_cpuLoad m1 : 8|14@1+ (0.01,0) [0|163.83] "%"  gtw
 SG_ BMS_log1MuxId M : 0|8@1+ (1,0) [0|7] ""  X

BO_ 1595 CC_udsResponse: 8 VEH
 SG_ CC_udsResponseData : 7|64@0+ (1,0) [0|18446744073709551615] ""  dbg

BO_ 1880 DI_dyno: 8 VEH
 SG_ DI_voltageForFlux m1 : 48|16@1+ (0.007629510949,0) [0|500.000000042715] "V"  dbg
 SG_ DI_IsMag m0 : 48|16@1- (0.1,0.0) [-3276.8|3276.7] "A"  dbg
 SG_ DI_torqueEstimate m2 : 48|13@1- (0.25,0.0) [-750|750] "Nm"  X
 SG_ DI_postPedalMaxTorque m32 : 44|12@1+ (0.25,0) [0|750] "Nm"  X
 SG_ DI_fluxFdbStdDeviation m33 : 42|16@1+ (0.0001,0) [0|6.5535] "Wb"  X
 SG_ DI_motorRPM m2 : 32|16@1- (1,0) [-17000|17000] "RPM"  gtw
 SG_ DI_postPedalMinTorque m32 : 32|12@1+ (0.25,-750) [-750|0] "Nm"  X
 SG_ DI_Isy m0 : 32|16@1+ (1.52590218966965e-05,0) [0|1.00000000000001] "A"  dbg
 SG_ DI_Vsy m1 : 32|16@1- (4e-05,0.0) [-1.31072|1.31068] "mindex"  dbg
 SG_ DI_iqFdbStdDeviation m33 : 30|12@1+ (0.5,0) [0|2047] "A"  X
 SG_ DI_stateDyno m2 : 29|3@1+ (1,0) [0|4] ""  X
 SG_ DI_pedalMaxTorque m32 : 20|12@1+ (0.25,0) [0|750] "Nm"  X
 SG_ DI_idFdbStdDeviation m33 : 18|12@1+ (0.5,0) [0|2047] "A"  X
 SG_ DI_Vsx m1 : 16|16@1- (4e-05,0.0) [-1.31072|1.31068] "mindex"  dbg
 SG_ DI_torqueMotor m2 : 16|13@1- (0.25,0.0) [-750|750] "Nm"  X
 SG_ DI_Isx m0 : 16|16@1+ (1.52590218966965e-05,0) [0|1.00000000000001] "A"  dbg
 SG_ DI_mechToElcFactor m64 : 8|4@1- (1,0) [-8|7] ""  X
 SG_ DI_pedalMinTorque m32 : 8|12@1+ (0.25,-750) [-750|0] "Nm"  X
 SG_ DI_slipEstimate m33 : 8|10@1- (0.02,0.0) [-10|10] "Hz"  X
 SG_ DI_dynoSelector M : 0|8@1+ (1,0) [0|64] ""  X

BO_ 1533 UMC_alertLog: 8 VEH
 SG_ UMC_a006_faultType m6 : 32|16@1+ (1,0) [0|1] ""  gtw
 SG_ UMC_a001_groundImpedance m1 : 32|32@1+ (1,0) [0|4294967295] "Ohm"  gtw
 SG_ UMC_a012_pilotLow m12 : 28|12@1- (0.01,0) [-20|20] "V"  gtw
 SG_ UMC_a012_pilotHigh m12 : 16|12@1- (0.01,0) [-20|20] "V"  gtw
 SG_ UMC_a016_pcbaTemp m16 : 16|16@1+ (1,0) [0|65535] "degC"  gtw
 SG_ UMC_a006_outputVoltage m6 : 16|16@1+ (1,0) [0|65535] "Vrms"  gtw
 SG_ UMC_a010_inputTerminalsTemp m10 : 16|16@1+ (1,0) [0|65535] "degC"  gtw
 SG_ UMC_a005_lineVoltage m5 : 16|16@1+ (1,0) [0|65535] "Vrms"  gtw
 SG_ UMC_a003_faultType m3 : 16|16@1+ (1,0) [0|1] ""  gtw
 SG_ UMC_a018_vehConnTemp m18 : 16|16@1+ (1,0) [0|65535] "degC"  gtw
 SG_ UMC_a017_wallPlugTemp m17 : 16|16@1+ (1,0) [0|65535] "degC"  gtw
 SG_ UMC_a004_lineVoltage m4 : 16|16@1+ (1,0) [0|65535] "Vrms"  gtw
 SG_ UMC_a007_pcbaTemp m7 : 16|16@1+ (1,0) [0|65535] "degC"  gtw
 SG_ UMC_a008_wallPlugTemp m8 : 16|16@1+ (1,0) [0|65535] "degC"  gtw
 SG_ UMC_a009_vehConnTemp m9 : 16|16@1+ (1,0) [0|65535] "degC"  gtw
 SG_ UMC_a019_inputTerminalsTemp m19 : 16|16@1+ (1,0) [0|65535] "degC"  gtw
 SG_ UMC_alertType : 15|1@1+ (1,0) [0|1] ""  gtw
 SG_ UMC_alertID M : 0|15@1+ (1,0) [0|23] ""  gtw

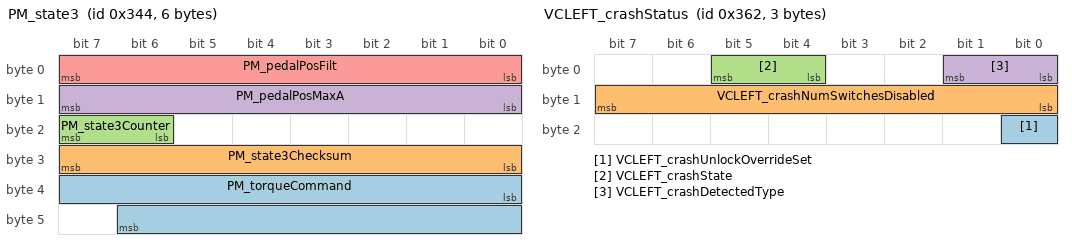
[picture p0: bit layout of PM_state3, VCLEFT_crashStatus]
BO_ 836 PM_state3: 6 VEH
 SG_ PM_torqueCommand : 32|15@1- (0.1,0.0) [-1100|1100] "Nm"  dbg
 SG_ PM_state3Checksum : 24|8@1+ (1,0) [0|255] ""  dbg
 SG_ PM_state3Counter : 22|2@1+ (1,0) [0|3] ""  dbg
 SG_ PM_pedalPosMaxA : 8|8@1+ (0.4,0) [0|100] "%"  gtw
 SG_ PM_pedalPosFilt : 0|8@1+ (0.4,0) [0|102] "%"  dbg

BO_ 753 VCFRONT_eFuseDebugStatus: 8 VEH
 SG_ VCFRONT_headlampRightTemperature m12 : 56|8@1- (1,-40) [-40|150] "degC"  gtw
 SG_ VCFRONT_pump2AndAirCompVoltage m14 : 51|12@1+ (0.1,0) [0|409.5] "V"  gtw
 SG_ VCFRONT_headlampLeftTemperature m12 : 48|8@1- (1,-40) [-40|150] "degC"  gtw
 SG_ VCFRONT_iBoosterCurrent m3 : 47|16@1+ (0.1,0) [0|6553.5] "A"  gtw
 SG_ VCFRONT_EPAS3PCurrent m4 : 47|16@1+ (0.1,0) [0|6553.5] "A"  gtw
 SG_ VCFRONT_rightControllerCurrent m0 : 47|16@1+ (0.1,0) [0|6553.5] "A"  X
 SG_ VCFRONT_leftControllerCurrent m1 : 47|16@1+ (0.1,0) [0|6553.5] "A"  X
 SG_ VCFRONT_EPAS3SCurrent m5 : 47|16@1+ (0.1,0) [0|6553.5] "A"  gtw
 SG_ VCFRONT_PCSCurrent m2 : 47|16@1- (0.1,0) [-3276.8|3276.7] "A"  bms
 SG_ VCFRONT_ESPMotorCurrent m6 : 47|16@1+ (0.1,0) [0|6553.5] "A"  gtw
 SG_ VCFRONT_vbatFusedHighCurrent m13 : 46|16@1+ (0.1,0) [0|6553.5] "A"  gtw
 SG_ VCFRONT_ESPValveCurrent m7 : 44|16@1+ (0.1,0) [0|6553.5] "A"  gtw
 SG_ VCFRONT_railB_5v m15 : 44|12@1+ (0.005443676098,0) [0|22.29185] "V"  gtw
 SG_ VCFRONT_autopilot2Current m9 : 43|16@1+ (0.1,0) [0|6553.5] "A"  gtw
 SG_ VCFRONT_autopilot1Current m8 : 43|16@1+ (0.1,0) [0|6553.5] "A"  gtw
 SG_ VCFRONT_headlampRightVoltage m12 : 40|8@1+ (0.1,0) [0|25.4] "V"  gtw
 SG_ VCFRONT_vbatProt m16 : 40|12@1+ (0.005443676098,0) [0|22.29185] "V"  gtw
 SG_ VCFRONT_pump2AndAirCompCurrent m14 : 35|16@1+ (0.1,0) [0|6553.5] "A"  gtw
 SG_ VCFRONT_pump2AndAirCompState m14 : 34|1@1+ (1,0) [0|1] ""  gtw
 SG_ VCFRONT_uiCurrent m11 : 32|16@1+ (0.1,0) [0|6553.5] "A"  gtw
 SG_ VCFRONT_railA_5v m15 : 32|12@1+ (0.005443676098,0) [0|22.29185] "V"  gtw
 SG_ VCFRONT_PCSVoltage m2 : 31|16@1+ (0.1,0) [0|6553.5] "V"  gtw
 SG_ VCFRONT_leftControllerVoltage m1 : 31|16@1+ (0.1,0) [0|6553.5] "V"  gtw
 SG_ VCFRONT_rightControllerVoltage m0 : 31|16@1+ (0.1,0) [0|6553.5] "V"  gtw
 SG_ VCFRONT_EPAS3PVoltage m4 : 31|16@1+ (0.1,0) [0|6553.5] "V"  gtw
 SG_ VCFRONT_ESPMotorVoltage m6 : 31|16@1+ (0.1,0) [0|6553.5] "V"  gtw
 SG_ VCFRONT_EPAS3SVoltage m5 : 31|16@1+ (0.1,0) [0|6553.5] "V"  gtw
 SG_ VCFRONT_iBoosterVoltage m3 : 31|16@1+ (0.1,0) [0|6553.5] "V"  gtw
 SG_ VCFRONT_headlampRightCurrent m12 : 30|10@1+ (0.1,0) [0|102.3] "A"  gtw
 SG_ VCFRONT_vbatFusedHighVoltage m13 : 30|16@1+ (0.1,0) [0|6553.5] "V"  gtw
 SG_ VCFRONT_headlampRightFault m12 : 29|1@1+ (1,0) [0|1] ""  X
 SG_ VCFRONT_headlampRightState m12 : 28|1@1+ (1,0) [0|1] ""  X
 SG_ VCFRONT_ESPValveVoltage m7 : 28|16@1+ (0.1,0) [0|6553.5] "V"  gtw
 SG_ VCFRONT_autopilot1Voltage m8 : 27|16@1+ (0.1,0) [0|6553.5] "V"  gtw
 SG_ VCFRONT_autopilot2Voltage m9 : 27|16@1+ (0.1,0) [0|6553.5] "V"  gtw
 SG_ VCFRONT_sleepBypassCurrent m10 : 26|16@1+ (0.1,0) [0|6553.5] "A"  gtw
 SG_ VCFRONT_uiFault m11 : 25|1@1+ (1,0) [0|1] ""  gtw
 SG_ VCFRONT_uiState m11 : 24|1@1+ (1,0) [0|1] ""  gtw
 SG_ VCFRONT_ChargePumpVoltage m16 : 24|16@1+ (0.005443676098,0) [0|356.75131] "V"  gtw
 SG_ VCFRONT_dischargedIBSAmpHours m17 : 24|16@1- (1,0) [-32768|32767] "Ah"  gtw
 SG_ VCFRONT_pump1AndFanVoltage m14 : 22|12@1+ (0.1,0) [0|409.5] "V"  gtw
 SG_ VCFRONT_railB_12v m15 : 20|12@1+ (0.005443676098,0) [0|22.29185] "V"  gtw
 SG_ VCFRONT_headlampLeftVoltage m12 : 20|8@1+ (0.1,0) [0|25.4] "V"  gtw
 SG_ VCFRONT_EPAS3STemp m5 : 15|11@1+ (0.125,-40) [-40|150] "degC"  gtw
 SG_ VCFRONT_ESPMotorTemp m6 : 15|11@1+ (0.125,-40) [-40|150] "degC"  gtw
 SG_ VCFRONT_rightControllerTemp m0 : 15|11@1+ (0.125,-40) [-40|150] "degC"  gtw
 SG_ VCFRONT_EPAS3PTemp m4 : 15|11@1+ (0.125,-40) [-40|150] "degC"  gtw
 SG_ VCFRONT_leftControllerTemp m1 : 15|11@1+ (0.125,-40) [-40|150] "degC"  gtw
 SG_ VCFRONT_PCSTemp m2 : 15|11@1+ (0.125,-40) [-40|150] "degC"  gtw
 SG_ VCFRONT_iBoosterTemp m3 : 15|11@1+ (0.125,-40) [-40|150] "degC"  gtw
 SG_ VCFRONT_vbatFusedHighTemp m13 : 14|11@1+ (0.125,-40) [-40|150] "degC"  X
 SG_ VCFRONT_ESPValveTemp m7 : 12|11@1+ (0.125,-40) [-40|150] "degC"  X
 SG_ VCFRONT_vcleftSelfTestResult m1 : 11|4@1+ (1,0) [0|11] ""  X
 SG_ VCFRONT_iBoosterSelfTestResult m3 : 11|4@1+ (1,0) [0|11] ""  X
 SG_ VCFRONT_pcsSelfTestResult m2 : 11|4@1+ (1,0) [0|11] ""  X
 SG_ VCFRONT_vcrightSelfTestResult m0 : 11|4@1+ (1,0) [0|11] ""  X
 SG_ VCFRONT_autopilot1Temp m8 : 11|11@1+ (0.125,-40) [-40|150] "degC"  X
 SG_ VCFRONT_EPAS3PSelfTestResult m4 : 11|4@1+ (1,0) [0|11] ""  X
 SG_ VCFRONT_ESPMotorSelfTestResult m6 : 11|4@1+ (1,0) [0|11] ""  X
 SG_ VCFRONT_EPAS3SSelfTestResult m5 : 11|4@1+ (1,0) [0|11] ""  X
 SG_ VCFRONT_autopilot2Temp m9 : 11|11@1+ (0.125,-40) [-40|150] "degC"  X
 SG_ VCFRONT_PCSFault m2 : 10|1@1+ (1,0) [0|1] ""  gtw
 SG_ VCFRONT_leftControllerFault m1 : 10|1@1+ (1,0) [0|1] ""  X
 SG_ VCFRONT_EPAS3PFault m4 : 10|1@1+ (1,0) [0|1] ""  X
 SG_ VCFRONT_rightControllerFault m0 : 10|1@1+ (1,0) [0|1] ""  X
 SG_ VCFRONT_ESPMotorFault m6 : 10|1@1+ (1,0) [0|1] ""  X
 SG_ VCFRONT_headlampLeftCurrent m12 : 10|10@1+ (0.1,0) [0|102.3] "A"  gtw
 SG_ VCFRONT_autopilot1Fault m8 : 10|1@1+ (1,0) [0|1] ""  gtw
 SG_ VCFRONT_EPAS3SFault m5 : 10|1@1+ (1,0) [0|1] ""  X
 SG_ VCFRONT_vbatFusedSelfTestResult m13 : 10|4@1+ (1,0) [0|11] ""  X
 SG_ VCFRONT_autopilot2Fault m9 : 10|1@1+ (1,0) [0|1] ""  gtw
 SG_ VCFRONT_iBoosterFault m3 : 10|1@1+ (1,0) [0|1] ""  X
 SG_ VCFRONT_ESPValveFault m7 : 10|1@1+ (1,0) [0|1] ""  X
 SG_ VCFRONT_sleepBypassVoltage m10 : 10|16@1+ (0.1,0) [0|6553.5] "V"  gtw
 SG_ VCFRONT_headlampLeftFault m12 : 9|1@1+ (1,0) [0|1] ""  X
 SG_ VCFRONT_vbatFusedHighFault m13 : 9|1@1+ (1,0) [0|1] ""  X
 SG_ VCFRONT_sleepBypassFault m10 : 9|1@1+ (1,0) [0|1] ""  X
 SG_ VCFRONT_sleepBypassState m10 : 8|1@1+ (1,0) [0|1] ""  gtw
 SG_ VCFRONT_railA_12v m15 : 8|12@1+ (0.005443676098,0) [0|22.29185] "V"  gtw
 SG_ VCFRONT_leftControllerState m1 : 8|2@1+ (1,0) [0|2] ""  gtw
 SG_ VCFRONT_chargedIBSAmpHours m17 : 8|16@1- (1,0) [-32768|32767] "Ah"  gtw
 SG_ VCFRONT_vbatFusedHighState m13 : 8|1@1+ (1,0) [0|1] ""  gtw
 SG_ VCFRONT_ESPValveState m7 : 8|2@1+ (1,0) [0|2] ""  gtw
 SG_ VCFRONT_autopilot2State m9 : 8|2@1+ (1,0) [0|2] ""  gtw
 SG_ VCFRONT_iBoosterState m3 : 8|2@1+ (1,0) [0|2] ""  gtw
 SG_ VCFRONT_autopilot1State m8 : 8|2@1+ (1,0) [0|2] ""  gtw
 SG_ VCFRONT_eFuseLockoutVoltage m16 : 8|12@1+ (0.005443676098,0) [0|22.29185] "V"  gtw
 SG_ VCFRONT_ESPMotorState m6 : 8|2@1+ (1,0) [0|2] ""  gtw
 SG_ VCFRONT_EPAS3SState m5 : 8|2@1+ (1,0) [0|2] ""  gtw
 SG_ VCFRONT_uiAudioCurrent m11 : 8|16@1+ (0.1,0) [0|6553.5] "A"  gtw
 SG_ VCFRONT_EPAS3PState m4 : 8|2@1+ (1,0) [0|2] ""  gtw
 SG_ VCFRONT_rightControllerState m0 : 8|2@1+ (1,0) [0|2] ""  gtw
 SG_ VCFRONT_headlampLeftState m12 : 8|1@1+ (1,0) [0|1] ""  X
 SG_ VCFRONT_PCSState m2 : 8|2@1+ (1,0) [0|2] ""  gtw
 SG_ VCFRONT_pump1AndFanCurrent m14 : 6|16@1+ (0.1,0) [0|6553.5] "A"  gtw
 SG_ VCFRONT_uiAudioFault m11 : 6|1@1+ (1,0) [0|1] ""  X
 SG_ VCFRONT_uiAudioState m11 : 5|1@1+ (1,0) [0|1] ""  gtw
 SG_ VCFRONT_pump1AndFanState m14 : 5|1@1+ (1,0) [0|1] ""  gtw
 SG_ VCFRONT_eFuseDebugStatusIndex M : 0|5@1+ (1,0) [0|18] ""  X

BO_ 866 VCLEFT_crashStatus: 3 VEH
 SG_ VCLEFT_crashUnlockOverrideSet : 16|1@1+ (1,0) [0|1] ""  gtw
 SG_ VCLEFT_crashNumSwitchesDisabled : 8|8@1+ (1,0) [0|255] ""  gtw
 SG_ VCLEFT_crashState : 4|2@1+ (1,0) [0|2] ""  gtw
 SG_ VCLEFT_crashDetectedType : 0|2@1+ (1,0) [0|2] ""  gtw

BO_ 800 BMS_alertMatrix: 8 VEH
 SG_ BMS_a060_SW_Leakage_Test_Failure m0 : 63|1@1+ (1,0) [0|1] ""  dbg
 SG_ BMS_a180_SW_ECU_reset_blocked m2 : 63|1@1+ (1,0) [0|1] ""  dbg
 SG_ BMS_a179_SW_Hvp_12V_Fault m2 : 62|1@1+ (1,0) [0|1] ""  dbg
 SG_ BMS_a059_SW_Pack_Voltage_Sensing m0 : 62|1@1+ (1,0) [0|1] ""  dbg
 SG_ BMS_a178_SW_Uncontrolled_Regen_P m2 : 61|1@1+ (1,0) [0|1] ""  dbg
 SG_ BMS_a176_SW_GracefulPowerOff m2 : 59|1@1+ (1,0) [0|1] ""  dbg
 SG_ BMS_a055_SW_HvChain_Model_Fault m0 : 58|1@1+ (1,0) [0|1] ""  dbg
 SG_ BMS_a054_SW_Ver_Supply_Fault m0 : 57|1@1+ (1,0) [0|1] ""  dbg
 SG_ BMS_a174_SW_Charge_Failure m2 : 57|1@1+ (1,0) [0|1] ""  dbg
 SG_ BMS_a053_SW_ThermalModel_Sanity m0 : 56|1@1+ (1,0) [0|1] ""  dbg
 SG_ BMS_a052_SW_PCS_MIA m0 : 55|1@1+ (1,0) [0|1] ""  dbg
 SG_ BMS_a171_SW_Stack_Voltage_Sense m2 : 54|1@1+ (1,0) [0|1] ""  dbg
 SG_ BMS_a051_SW_HVC_Vref_Bad m0 : 54|1@1+ (1,0) [0|1] ""  dbg
 SG_ BMS_a050_SW_Brick_Voltage_MIA m0 : 53|1@1+ (1,0) [0|1] ""  dbg
 SG_ BMS_a170_SW_Limp_Mode m2 : 53|1@1+ (1,0) [0|1] ""  dbg
 SG_ BMS_a169_SW_FC_Pack_Weld m2 : 52|1@1+ (1,0) [0|1] ""  dbg
 SG_ BMS_a048_SW_Log_Upload_Request m0 : 51|1@1+ (1,0) [0|1] ""  dbg
 SG_ BMS_a168_SW_FC_Full_Weld m2 : 51|1@1+ (1,0) [0|1] ""  dbg
 SG_ BMS_a107_SW_Stack_Voltage_MIA m1 : 50|1@1+ (1,0) [0|1] ""  dbg
 SG_ BMS_a167_SW_FC_Partial_Weld m2 : 50|1@1+ (1,0) [0|1] ""  dbg
 SG_ BMS_a047_SW_Task_Stack_Overflow m0 : 50|1@1+ (1,0) [0|1] ""  dbg
 SG_ BMS_a106_SW_All_Module_Tsense m1 : 49|1@1+ (1,0) [0|1] ""  dbg
 SG_ BMS_a046_SW_Task_Stack_Usage m0 : 49|1@1+ (1,0) [0|1] ""  dbg
 SG_ BMS_a166_SW_Pack_Full_Weld m2 : 49|1@1+ (1,0) [0|1] ""  dbg
 SG_ BMS_a105_SW_One_Module_Tsense m1 : 48|1@1+ (1,0) [0|1] ""  dbg
 SG_ BMS_a045_SW_Exception m0 : 48|1@1+ (1,0) [0|1] ""  dbg
 SG_ BMS_a165_SW_Pack_Partial_Weld m2 : 48|1@1+ (1,0) [0|1] ""  dbg
 SG_ BMS_a044_SW_Assertion m0 : 47|1@1+ (1,0) [0|1] ""  dbg
 SG_ BMS_a164_SW_Uncontrolled_Regen m2 : 47|1@1+ (1,0) [0|1] ""  dbg
 SG_ BMS_a163_SW_Contactor_Mismatch m2 : 46|1@1+ (1,0) [0|1] ""  dbg
 SG_ BMS_a043_SW_Watch_Dog_Reset m0 : 46|1@1+ (1,0) [0|1] ""  dbg
 SG_ BMS_a042_SW_MPU_Error m0 : 45|1@1+ (1,0) [0|1] ""  dbg
 SG_ BMS_a162_SW_No_Power_For_Support m2 : 45|1@1+ (1,0) [0|1] ""  dbg
 SG_ BMS_a041_SW_Power_On_Reset m0 : 44|1@1+ (1,0) [0|1] ""  dbg
 SG_ BMS_a161_SW_DI_Open_Request m2 : 44|1@1+ (1,0) [0|1] ""  dbg
 SG_ BMS_a159_SW_HVP_ECU_Error m2 : 42|1@1+ (1,0) [0|1] ""  dbg
 SG_ BMS_a039_SW_DC_Link_Over_Voltage m0 : 42|1@1+ (1,0) [0|1] ""  dbg
 SG_ BMS_a099_SW_BMB_Communication m1 : 42|1@1+ (1,0) [0|1] ""  dbg
 SG_ BMS_a158_SW_HVP_HVI_Comms m2 : 41|1@1+ (1,0) [0|1] ""  dbg
 SG_ BMS_a157_SW_HVP_HVS_Comms m2 : 40|1@1+ (1,0) [0|1] ""  dbg
 SG_ BMS_a037_SW_Flood_Port_Open m0 : 40|1@1+ (1,0) [0|1] ""  dbg
 SG_ BMS_a156_SW_BMB_Vref_bad m2 : 39|1@1+ (1,0) [0|1] ""  dbg
 SG_ BMS_a036_SW_HvpHvilFault m0 : 39|1@1+ (1,0) [0|1] ""  dbg
 SG_ BMS_a035_SW_Isolation m0 : 38|1@1+ (1,0) [0|1] ""  dbg
 SG_ BMS_a034_SW_Passive_Isolation m0 : 37|1@1+ (1,0) [0|1] ""  dbg
 SG_ BMS_a094_SW_Drive_Inverter_MIA m1 : 37|1@1+ (1,0) [0|1] ""  dbg
 SG_ BMS_a092_SW_ChargePort_Mia_On_Hv m1 : 35|1@1+ (1,0) [0|1] ""  dbg
 SG_ BMS_a151_SW_external_isolation m2 : 34|1@1+ (1,0) [0|1] ""  dbg
 SG_ BMS_a091_SW_ChargePort_MIA m1 : 34|1@1+ (1,0) [0|1] ""  dbg
 SG_ BMS_a090_SW_Gateway_MIA m1 : 33|1@1+ (1,0) [0|1] ""  dbg
 SG_ BMS_a089_SW_VcFront_MIA m1 : 32|1@1+ (1,0) [0|1] ""  dbg
 SG_ BMS_a149_SW_Missing_Config_Block m2 : 32|1@1+ (1,0) [0|1] ""  dbg
 SG_ BMS_a088_SW_VcFront_MIA_InDrive m1 : 31|1@1+ (1,0) [0|1] ""  dbg
 SG_ BMS_a087_SW_Feim_Test_Blocked m1 : 30|1@1+ (1,0) [0|1] ""  dbg
 SG_ BMS_a146_SW_Brick_Overdischarged m2 : 29|1@1+ (1,0) [0|1] ""  dbg
 SG_ BMS_a026_SW_HFCurrent_Anomaly m0 : 29|1@1+ (1,0) [0|1] ""  dbg
 SG_ BMS_a145_SW_SOC_Change m2 : 28|1@1+ (1,0) [0|1] ""  dbg
 SG_ BMS_a025_SW_PwrBalance_Anomaly m0 : 28|1@1+ (1,0) [0|1] ""  dbg
 SG_ BMS_a084_SW_Sleep_Wake_Aborted m1 : 27|1@1+ (1,0) [0|1] ""  dbg
 SG_ BMS_a024_SW_Islanded_Brick m0 : 27|1@1+ (1,0) [0|1] ""  dbg
 SG_ BMS_a144_Hvp_Config_Mismatch m2 : 27|1@1+ (1,0) [0|1] ""  dbg
 SG_ BMS_a083_SW_Ctr_Close_Failure m1 : 26|1@1+ (1,0) [0|1] ""  dbg
 SG_ BMS_a023_SW_Stack_OV m0 : 26|1@1+ (1,0) [0|1] ""  dbg
 SG_ BMS_a022_SW_Over_Current m0 : 25|1@1+ (1,0) [0|1] ""  dbg
 SG_ BMS_a082_SW_Ctr_Force_Open m1 : 25|1@1+ (1,0) [0|1] ""  dbg
 SG_ BMS_a141_SW_BMB_Status_Warning m2 : 24|1@1+ (1,0) [0|1] ""  dbg
 SG_ BMS_a081_SW_Ctr_Close_Blocked m1 : 24|1@1+ (1,0) [0|1] ""  dbg
 SG_ BMS_a021_SW_Dr_Limits_Regulation m0 : 24|1@1+ (1,0) [0|1] ""  dbg
 SG_ BMS_a019_SW_Module_OT m0 : 22|1@1+ (1,0) [0|1] ""  dbg
 SG_ BMS_a139_SW_DC_Link_V_Irrational m2 : 22|1@1+ (1,0) [0|1] ""  dbg
 SG_ BMS_a018_SW_Brick_UV m0 : 21|1@1+ (1,0) [0|1] ""  dbg
 SG_ BMS_a138_SW_Brick_OV_Warning m2 : 21|1@1+ (1,0) [0|1] ""  dbg
 SG_ BMS_a077_SW_Charger_Regulation m1 : 20|1@1+ (1,0) [0|1] ""  dbg
 SG_ BMS_a137_SW_Brick_UV_Warning m2 : 20|1@1+ (1,0) [0|1] ""  dbg
 SG_ BMS_a017_SW_Brick_OV m0 : 20|1@1+ (1,0) [0|1] ""  dbg
 SG_ BMS_a136_SW_Module_OT_Warning m2 : 19|1@1+ (1,0) [0|1] ""  dbg
 SG_ BMS_a076_SW_Dch_While_Charging m1 : 19|1@1+ (1,0) [0|1] ""  dbg
 SG_ BMS_a075_SW_Chg_Disable_Failure m1 : 18|1@1+ (1,0) [0|1] ""  dbg
 SG_ BMS_a134_SW_Delayed_Ctr_Off m2 : 17|1@1+ (1,0) [0|1] ""  dbg
 SG_ BMS_a132_HW_BMB_OTP_Uncorrctbl m2 : 15|1@1+ (1,0) [0|1] ""  dbg
 SG_ BMS_a071_SW_SM_TransCon_Not_Met m1 : 14|1@1+ (1,0) [0|1] ""  dbg
 SG_ BMS_a131_Bleed_FET_Failure m2 : 14|1@1+ (1,0) [0|1] ""  dbg
 SG_ BMS_a130_IO_CAN_Error m2 : 13|1@1+ (1,0) [0|1] ""  dbg
 SG_ BMS_a129_SW_VSH_Failure m2 : 12|1@1+ (1,0) [0|1] ""  dbg
 SG_ BMS_a069_SW_Low_Power m1 : 12|1@1+ (1,0) [0|1] ""  dbg
 SG_ BMS_a128_SW_shunt_MIA m2 : 11|1@1+ (1,0) [0|1] ""  dbg
 SG_ BMS_a127_SW_shunt_SNA m2 : 10|1@1+ (1,0) [0|1] ""  dbg
 SG_ BMS_a064_SW_SOC_Imbalance m1 : 7|1@1+ (1,0) [0|1] ""  dbg
 SG_ BMS_a123_SW_Internal_Isolation m2 : 6|1@1+ (1,0) [0|1] ""  dbg
 SG_ BMS_a063_SW_ChargePort_Fault m1 : 6|1@1+ (1,0) [0|1] ""  dbg
 SG_ BMS_a122_SW_BMS_Therm_Irrational m2 : 5|1@1+ (1,0) [0|1] ""  dbg
 SG_ BMS_a062_SW_BrickV_Imbalance m1 : 5|1@1+ (1,0) [0|1] ""  dbg
 SG_ BMS_a001_Pack_Config_Mismatch m0 : 4|1@1+ (1,0) [0|1] ""  dbg
 SG_ BMS_a121_SW_NVRAM_Config_Error m2 : 4|1@1+ (1,0) [0|1] ""  dbg
 SG_ BMS_a061_robinBrickOverVoltage m1 : 4|1@1+ (1,0) [0|1] ""  dbg
 SG_ BMS_matrixIndex M : 0|4@1+ (1,0) [0|15] ""  gtw

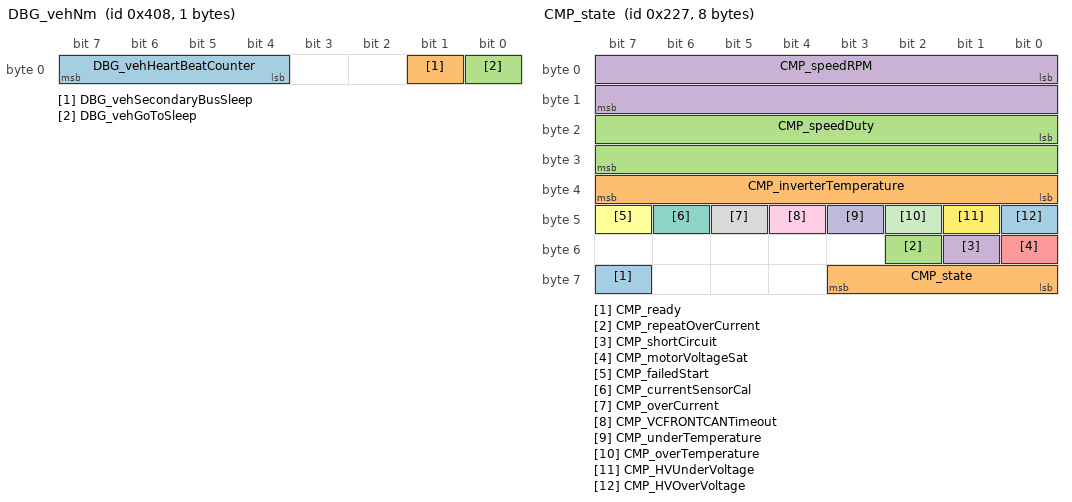
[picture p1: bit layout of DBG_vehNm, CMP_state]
BO_ 1032 DBG_vehNm: 1 VEH
 SG_ DBG_vehHeartBeatCounter : 4|4@1+ (1,0) [0|15] ""  X
 SG_ DBG_vehSecondaryBusSleep : 1|1@1+ (1,0) [0|1] ""  X
 SG_ DBG_vehGoToSleep : 0|1@1+ (1,0) [0|1] ""  X

BO_ 1577 PCS_udsResponse: 8 VEH
 SG_ PCS_udsResponseData : 7|64@0+ (1,0) [0|18446744073709551615] ""  gtw

BO_ 772 PM_alertMatrix1: 8 VEH
 SG_ PM_a064_torqueIntervention : 63|1@1+ (1,0) [0|1] ""  gtw
 SG_ PM_a063_debugAlert : 62|1@1+ (1,0) [0|1] ""  gtw
 SG_ PM_a061_DIPMVersionMismatch : 60|1@1+ (1,0) [0|1] ""  gtw
 SG_ PM_a059_ptcMIA : 58|1@1+ (1,0) [0|1] ""  gtw
 SG_ PM_a058_cmpMIA : 57|1@1+ (1,0) [0|1] ""  gtw
 SG_ PM_a057_canDataBusB : 56|1@1+ (1,0) [0|1] ""  gtw
 SG_ PM_a056_canHardwareBusB : 55|1@1+ (1,0) [0|1] ""  gtw
 SG_ PM_a055_resolver : 54|1@1+ (1,0) [0|1] ""  gtw
 SG_ PM_a054_uiMIA : 53|1@1+ (1,0) [0|1] ""  gtw
 SG_ PM_a053_vcfrontMIA : 52|1@1+ (1,0) [0|1] ""  gtw
 SG_ PM_a052_stbCtrlDrvrDecelCflct : 51|1@1+ (1,0) [0|1] ""  gtw
 SG_ PM_a051_unintDecelStbCtrl : 50|1@1+ (1,0) [0|1] ""  gtw
 SG_ PM_a050_excessiveStbCtrlTrq : 49|1@1+ (1,0) [0|1] ""  gtw
 SG_ PM_a049_stbCtrlInWrongDir : 48|1@1+ (1,0) [0|1] ""  gtw
 SG_ PM_a048_stabilityControlInhibit : 47|1@1+ (1,0) [0|1] ""  gtw
 SG_ PM_a047_inconsAutoparkState : 46|1@1+ (1,0) [0|1] ""  gtw
 SG_ PM_a046_inconsVehicleHoldState : 45|1@1+ (1,0) [0|1] ""  gtw
 SG_ PM_a045_motorMovementDetected : 44|1@1+ (1,0) [0|1] ""  gtw
 SG_ PM_a044_ebrIntervention : 43|1@1+ (1,0) [0|1] ""  gtw
 SG_ PM_a043_inconsistentConfig : 42|1@1+ (1,0) [0|1] ""  gtw
 SG_ PM_a042_gtwMIA : 41|1@1+ (1,0) [0|1] ""  gtw
 SG_ PM_a041_dasMIA : 40|1@1+ (1,0) [0|1] ""  gtw
 SG_ PM_a040_pmMIA : 39|1@1+ (1,0) [0|1] ""  gtw
 SG_ PM_a039_disMIA : 38|1@1+ (1,0) [0|1] ""  gtw
 SG_ PM_a038_inconsistentTorqueSign : 37|1@1+ (1,0) [0|1] ""  gtw
 SG_ PM_a034_trqCrossCheck : 33|1@1+ (1,0) [0|1] ""  gtw
 SG_ PM_a033_selfTest : 32|1@1+ (1,0) [0|1] ""  gtw
 SG_ PM_a032_registerConfigError : 31|1@1+ (1,0) [0|1] ""  gtw
 SG_ PM_a031_highStackUsage : 30|1@1+ (1,0) [0|1] ""  gtw
 SG_ PM_a030_inconsistentAebState : 29|1@1+ (1,0) [0|1] ""  gtw
 SG_ PM_a028_torqueCmdError : 27|1@1+ (1,0) [0|1] ""  gtw
 SG_ PM_a027_torqueOutOfMap : 26|1@1+ (1,0) [0|1] ""  gtw
 SG_ PM_a026_diHeartBeatMIA : 25|1@1+ (1,0) [0|1] ""  gtw
 SG_ PM_a024_brakeIrrational : 23|1@1+ (1,0) [0|1] ""  gtw
 SG_ PM_a023_crsCmdOffStateOn : 22|1@1+ (1,0) [0|1] ""  gtw
 SG_ PM_a019_statorTempIrrational : 18|1@1+ (1,0) [0|1] ""  gtw
 SG_ PM_a018_encoderIrrational : 17|1@1+ (1,0) [0|1] ""  gtw
 SG_ PM_a017_brakeMIA : 16|1@1+ (1,0) [0|1] ""  gtw
 SG_ PM_a016_cruiseMIA : 15|1@1+ (1,0) [0|1] ""  gtw
 SG_ PM_a015_shifterMIA : 14|1@1+ (1,0) [0|1] ""  gtw
 SG_ PM_a014_accelPedalError : 13|1@1+ (1,0) [0|1] ""  gtw
 SG_ PM_a013_canHardwareBusA : 12|1@1+ (1,0) [0|1] ""  gtw
 SG_ PM_a012_canDataBusA : 11|1@1+ (1,0) [0|1] ""  gtw
 SG_ PM_a011_phaseCurrentIrrational : 10|1@1+ (1,0) [0|1] ""  gtw
 SG_ PM_a010_diMIA : 9|1@1+ (1,0) [0|1] ""  gtw
 SG_ PM_a009_espMIA : 8|1@1+ (1,0) [0|1] ""  gtw
 SG_ PM_a008_memoryError : 7|1@1+ (1,0) [0|1] ""  gtw
 SG_ PM_a007_watchdogReset : 6|1@1+ (1,0) [0|1] ""  gtw
 SG_ PM_a006_inconsistentDIGear : 5|1@1+ (1,0) [0|1] ""  gtw
 SG_ PM_a005_torqueInNeutral : 4|1@1+ (1,0) [0|1] ""  gtw
 SG_ PM_a004_regenTorque : 3|1@1+ (1,0) [0|1] ""  gtw
 SG_ PM_a003_torqueReversal : 2|1@1+ (1,0) [0|1] ""  gtw
 SG_ PM_a002_accumulatedTorque : 1|1@1+ (1,0) [0|1] ""  gtw
 SG_ PM_a001_absoluteTorque : 0|1@1+ (1,0) [0|1] ""  gtw

BO_ 744 EPBR_status: 8 VEH
 SG_ EPBR_statusChecksum : 56|8@1+ (1,0) [0|255] ""  X
 SG_ EPBR_statusCounter : 52|4@1+ (1,0) [0|15] ""  X
 SG_ EPBR_blockDrive : 51|1@1+ (1,0) [0|1] ""  vcfront
 SG_ EPBR_bothDisconnected : 50|1@1+ (1,0) [0|1] ""  X
 SG_ EPBR_winchModeAvailable : 49|1@1+ (1,0) [0|1] ""  X
 SG_ EPBR_hornRequest : 48|1@1+ (1,0) [0|1] ""  vcfront
 SG_ EPBR_okToPark : 47|1@1+ (1,0) [0|1] ""  di
 SG_ EPBR_espPowerRequest : 46|1@1+ (1,0) [0|1] ""  vcfront
 SG_ EPBR_winchModeTimer : 32|12@1+ (1,0) [0|4095] ""  X
 SG_ EPBR_brakeDiscWipeRequest : 30|2@1+ (1,0) [0|3] ""  X
 SG_ EPBR_cdpRequest : 27|1@1+ (1,0) [0|1] ""  X
 SG_ EPBR_updateMode : 24|1@1+ (1,0) [0|1] ""  X
 SG_ EPBR_winchModeActive : 23|1@1+ (1,0) [0|1] ""  X
 SG_ EPBR_requestUserConfirmation : 21|1@1+ (1,0) [0|1] ""  X
 SG_ EPBR_uiParkAvailable : 20|1@1+ (1,0) [0|1] ""  X
 SG_ EPBR_brakeHWConfigMismatch : 19|1@1+ (1,0) [0|1] ""  X
 SG_ EPBR_brakeLight : 18|1@1+ (1,0) [0|1] ""  vcleft
 SG_ EPBR_summonEnabled : 17|1@1+ (1,0) [0|1] ""  X
 SG_ EPBR_telltale : 8|3@1+ (1,0) [0|7] ""  X
 SG_ EPBR_systemStatus : 0|4@1+ (1,0) [0|8] ""  di

BO_ 837 PTC_info: 8 VEH
 SG_ PTC_infoComponentId m10 : 48|16@1+ (1,0) [0|65535] ""  gtw
 SG_ PTC_infoSubUsageId m11 : 48|16@1+ (1,0) [0|65535] ""  gtw
 SG_ PTC_infoUsageId m11 : 32|16@1+ (1,0) [0|65535] ""  gtw
 SG_ PTC_infoHardwareId m10 : 32|16@1+ (1,0) [0|65535] ""  gtw
 SG_ PTC_infoAppCrc m13 : 32|32@1+ (1,0) [0|4294967295] ""  gtw
 SG_ PTC_infoBootCrc m20 : 32|32@1+ (1,0) [0|4294967295] ""  gtw
 SG_ PTC_infoBootSvnUrlHash m14 : 32|32@1+ (1,0) [0|4294967295] ""  X
 SG_ PTC_infoAssemblyId m11 : 24|8@1+ (1,0) [0|255] ""  gtw
 SG_ PTC_infoPcbaId m11 : 16|8@1+ (1,0) [0|255] ""  gtw
 SG_ PTC_infoBuildConfigId m10 : 16|16@1+ (1,0) [0|65535] ""  gtw
 SG_ PTC_infoPlatformType m13 : 8|8@1+ (1,0) [0|255] ""  gtw
 SG_ PTC_infoBootSvnRev m14 : 8|24@1+ (1,0) [0|16777215] ""  X
 SG_ PTC_infoBootUdsProtoVersion m20 : 8|8@1+ (1,0) [0|255] ""  gtw
 SG_ PTC_infoBootGitHash m18 : 8|56@1+ (1,0) [0|72057594037927935] ""  X
 SG_ PTC_infoBuildType m10 : 8|3@1+ (1,0) [0|4] ""  gtw
 SG_ PTC_infoAppGitHash m17 : 8|56@1+ (1,0) [0|72057594037927935] ""  X
 SG_ PTC_infoIndex M : 0|8@1+ (1,0) [0|255] ""  gtw

BO_ 949 DIS_alertMatrix2: 8 VEH
 SG_ DIS_a127_gracefulPowerOff : 62|1@1+ (1,0) [0|1] ""  gtw
 SG_ DIS_a126_limpMode : 61|1@1+ (1,0) [0|1] ""  gtw
 SG_ DIS_a123_lossMotorControl : 58|1@1+ (1,0) [0|1] ""  gtw
 SG_ DIS_a122_highStackUsage : 57|1@1+ (1,0) [0|1] ""  gtw
 SG_ DIS_a121_motorControlRegulation : 56|1@1+ (1,0) [0|1] ""  gtw
 SG_ DIS_a117_diMIA : 52|1@1+ (1,0) [0|1] ""  gtw
 SG_ DIS_a116_powerConvIrrational : 51|1@1+ (1,0) [0|1] ""  gtw
 SG_ DIS_a115_heatsinkTempImbalance : 50|1@1+ (1,0) [0|1] ""  gtw
 SG_ DIS_a114_noMotorSpeed : 49|1@1+ (1,0) [0|1] ""  gtw
 SG_ DIS_a113_noFuncHeatsinkSensor : 48|1@1+ (1,0) [0|1] ""  gtw
 SG_ DIS_a112_noPhaseCurrent : 47|1@1+ (1,0) [0|1] ""  gtw
 SG_ DIS_a110_brakeMIA : 45|1@1+ (1,0) [0|1] ""  gtw
 SG_ DIS_a108_stateTrans : 43|1@1+ (1,0) [0|1] ""  gtw
 SG_ DIS_a106_absMIA : 41|1@1+ (1,0) [0|1] ""  gtw
 SG_ DIS_a103_lowFlow : 38|1@1+ (1,0) [0|1] ""  gtw
 SG_ DIS_a100_assertion : 35|1@1+ (1,0) [0|1] ""  gtw
 SG_ DIS_a099_threadOverrun : 34|1@1+ (1,0) [0|1] ""  gtw
 SG_ DIS_a098_intTimeTooLong : 33|1@1+ (1,0) [0|1] ""  gtw
 SG_ DIS_a097_eepromError : 32|1@1+ (1,0) [0|1] ""  gtw
 SG_ DIS_a096_memoryError : 31|1@1+ (1,0) [0|1] ""  gtw
 SG_ DIS_a095_canOverrunBusA : 30|1@1+ (1,0) [0|1] ""  gtw
 SG_ DIS_a094_canDataBusA : 29|1@1+ (1,0) [0|1] ""  gtw
 SG_ DIS_a093_canHardwareBusA : 28|1@1+ (1,0) [0|1] ""  gtw
 SG_ DIS_a092_bmsMIA : 27|1@1+ (1,0) [0|1] ""  gtw
 SG_ DIS_a091_espMIA : 26|1@1+ (1,0) [0|1] ""  gtw
 SG_ DIS_a090_pmMIA : 25|1@1+ (1,0) [0|1] ""  gtw
 SG_ DIS_a088_uiMIA : 23|1@1+ (1,0) [0|1] ""  gtw
 SG_ DIS_a087_gtwMIA : 22|1@1+ (1,0) [0|1] ""  gtw
 SG_ DIS_a086_hvilNotPresent : 21|1@1+ (1,0) [0|1] ""  gtw
 SG_ DIS_a079_adcRefHigh : 14|1@1+ (1,0) [0|1] ""  gtw
 SG_ DIS_a078_adcRefLow : 13|1@1+ (1,0) [0|1] ""  gtw
 SG_ DIS_a077_12vSupplyUV : 12|1@1+ (1,0) [0|1] ""  gtw
 SG_ DIS_a076_12vSupplyOV : 11|1@1+ (1,0) [0|1] ""  gtw
 SG_ DIS_a075_motorSpeedMismatch : 10|1@1+ (1,0) [0|1] ""  gtw
 SG_ DIS_a074_motorEncoder : 9|1@1+ (1,0) [0|1] ""  gtw
 SG_ DIS_a073_motorSpeed : 8|1@1+ (1,0) [0|1] ""  gtw
 SG_ DIS_a072_gateDriveFaultCounter : 7|1@1+ (1,0) [0|1] ""  gtw
 SG_ DIS_a071_busDisconnected : 6|1@1+ (1,0) [0|1] ""  gtw
 SG_ DIS_a070_12vSupplySensor : 5|1@1+ (1,0) [0|1] ""  gtw
 SG_ DIS_a067_canOverrunBusB : 2|1@1+ (1,0) [0|1] ""  gtw
 SG_ DIS_a066_canDataBusB : 1|1@1+ (1,0) [0|1] ""  gtw
 SG_ DIS_a065_canHardwareBusB : 0|1@1+ (1,0) [0|1] ""  gtw

BO_ 551 CMP_state: 8 VEH
 SG_ CMP_ready : 63|1@1+ (1,0) [0|1] ""  gtw
 SG_ CMP_state : 56|4@1+ (1,0) [0|15] ""  gtw
 SG_ CMP_repeatOverCurrent : 50|1@1+ (1,0) [0|1] ""  gtw
 SG_ CMP_shortCircuit : 49|1@1+ (1,0) [0|1] ""  gtw
 SG_ CMP_motorVoltageSat : 48|1@1+ (1,0) [0|1] ""  gtw
 SG_ CMP_failedStart : 47|1@1+ (1,0) [0|1] ""  gtw
 SG_ CMP_currentSensorCal : 46|1@1+ (1,0) [0|1] ""  gtw
 SG_ CMP_overCurrent : 45|1@1+ (1,0) [0|1] ""  gtw
 SG_ CMP_VCFRONTCANTimeout : 44|1@1+ (1,0) [0|1] ""  gtw
 SG_ CMP_underTemperature : 43|1@1+ (1,0) [0|1] ""  gtw
 SG_ CMP_overTemperature : 42|1@1+ (1,0) [0|1] ""  gtw
 SG_ CMP_HVUnderVoltage : 41|1@1+ (1,0) [0|1] ""  gtw
 SG_ CMP_HVOverVoltage : 40|1@1+ (1,0) [0|1] ""  gtw
 SG_ CMP_inverterTemperature : 32|8@1+ (1,-40) [-40|200] "degC"  gtw
 SG_ CMP_speedDuty : 16|16@1+ (0.1,0) [0|100] "%"  X
 SG_ CMP_speedRPM : 0|16@1+ (1,0) [0|65534] "RPM"  gtw

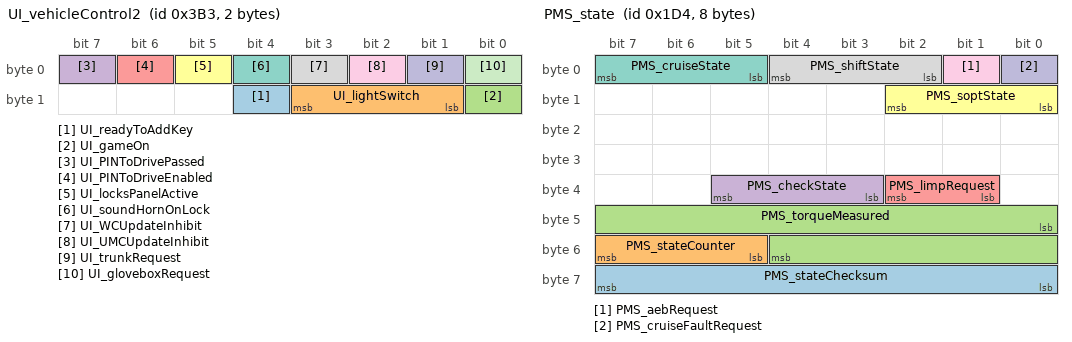
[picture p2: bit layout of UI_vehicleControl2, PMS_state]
BO_ 947 UI_vehicleControl2: 2 VEH
 SG_ UI_readyToAddKey : 12|1@1+ (1,0) [0|1] ""  vcsec
 SG_ UI_lightSwitch : 9|3@1+ (1,0) [0|4] ""  vcfront
 SG_ UI_gameOn : 8|1@1+ (1,0) [0|1] ""  vcfront
 SG_ UI_PINToDrivePassed : 7|1@1+ (1,0) [0|1] ""  vcfront
 SG_ UI_PINToDriveEnabled : 6|1@1+ (1,0) [0|1] ""  vcfront
 SG_ UI_locksPanelActive : 5|1@1+ (1,0) [0|1] ""  vcsec
 SG_ UI_soundHornOnLock : 4|1@1+ (1,0) [0|1] ""  vcfront
 SG_ UI_WCUpdateInhibit : 3|1@1+ (1,0) [0|1] ""  X
 SG_ UI_UMCUpdateInhibit : 2|1@1+ (1,0) [0|1] ""  X
 SG_ UI_trunkRequest : 1|1@1+ (1,0) [0|1] ""  vcright
 SG_ UI_gloveboxRequest : 0|1@1+ (1,0) [0|1] ""  vcright

BO_ 468 PMS_state: 8 VEH
 SG_ PMS_stateChecksum : 56|8@1+ (1,0) [0|255] ""  dbg
 SG_ PMS_stateCounter : 53|3@1+ (1,0) [0|7] ""  dbg
 SG_ PMS_torqueMeasured : 40|13@1- (0.25,0) [-1024|1023.75] "Nm"  dis
 SG_ PMS_checkState : 35|3@1+ (1,0) [0|4] ""  dbg
 SG_ PMS_limpRequest : 33|2@1+ (1,0) [0|2] ""  dis
 SG_ PMS_soptState : 8|3@1+ (1,0) [0|7] ""  dis
 SG_ PMS_cruiseState : 5|3@1+ (1,0) [0|7] ""  dbg
 SG_ PMS_shiftState : 2|3@1+ (1,0) [0|7] ""  dbg
 SG_ PMS_aebRequest : 1|1@1+ (1,0) [0|1] ""  dbg
 SG_ PMS_cruiseFaultRequest : 0|1@1+ (1,0) [0|1] ""  dbg

BO_ 1540 UDS_pmRequest: 8 VEH
 SG_ UDS_pmRequestData : 7|64@0+ (1,0) [0|18446744073709551615] ""  pm

BO_ 906 VCSEC_NFCCurrentCardUID: 8 VEH
 SG_ VCSEC_BPillarNFCCardUID m0 : 8|56@1+ (1,0) [0|72057594037927935] ""  gtw
 SG_ VCSEC_CenterNFCCardUID m3 : 8|56@1+ (1,0) [0|72057594037927935] ""  gtw
 SG_ VCSEC_NFCReaderIndexUID M : 0|2@1+ (1,0) [0|3] ""  X

BO_ 1942 DIS_xcpResponse: 8 VEH
 SG_ DIS_xcpResponse : 0|64@1+ (1,0) [0|18446744073709551615] ""  X

BO_ 1970 DBG_bmsServiceReq: 1 VEH
 SG_ DBG_bmsDebugEnableAll : 0|1@1+ (1,0) [0|1] ""  bms

BO_ 1805 DBG_pcsControl: 8 VEH
 SG_ DBG_pcs_PHB_pfcOvrEnable m23 : 63|1@1+ (1,0) [0|1] ""  X
 SG_ DBG_pcs_PHA_pfcOvrEnable m13 : 63|1@1+ (1,0) [0|1] ""  X
 SG_ DBG_pcs_PHC_pfcOvrEnable m33 : 63|1@1+ (1,0) [0|1] ""  X
 SG_ DBG_pcs_PHA_pfcEnable m13 : 62|1@1+ (1,0) [0|1] ""  X
 SG_ DBG_pcs_PHC_pfcEnable m33 : 62|1@1+ (1,0) [0|1] ""  X
 SG_ DBG_pcs_PHB_pfcEnable m23 : 62|1@1+ (1,0) [0|1] ""  X
 SG_ DBG_DCDC_fullShortEnable m103 : 56|1@1+ (1,0) [0|1] ""  X
 SG_ DBG_DCDC_Drv_FED_ns m102 : 54|10@1+ (1,0) [10|1024] "ns"  X
 SG_ DBG_pcs_PHC_scr_B_LO m33 : 51|1@1+ (1,0) [0|1] ""  X
 SG_ DBG_pcs_PHB_scr_B_LO m23 : 51|1@1+ (1,0) [0|1] ""  X
 SG_ DBG_pcs_PHA_scr_B_LO m13 : 51|1@1+ (1,0) [0|1] ""  X
 SG_ DBG_pcs_PHA_scr_B_HI m13 : 50|1@1+ (1,0) [0|1] ""  X
 SG_ DBG_pcs_PHB_llcOvrEnable m24 : 50|1@1+ (1,0) [0|1] ""  X
 SG_ DBG_pcs_PHC_scr_B_HI m33 : 50|1@1+ (1,0) [0|1] ""  X
 SG_ DBG_pcs_PHA_llcOvrEnable m14 : 50|1@1+ (1,0) [0|1] ""  X
 SG_ DBG_pcs_PHB_scr_B_HI m23 : 50|1@1+ (1,0) [0|1] ""  X
 SG_ DBG_pcs_PHC_llcOvrEnable m34 : 50|1@1+ (1,0) [0|1] ""  X
 SG_ DBG_pcs_PHB_llcEnable m24 : 49|1@1+ (1,0) [0|1] ""  X
 SG_ DBG_pcs_PHA_llcEnable m14 : 49|1@1+ (1,0) [0|1] ""  X
 SG_ DBG_pcs_PHA_scr_A_LO m13 : 49|1@1+ (1,0) [0|1] ""  X
 SG_ DBG_pcs_PHB_scr_A_LO m23 : 49|1@1+ (1,0) [0|1] ""  X
 SG_ DBG_pcs_PHC_scr_A_LO m33 : 49|1@1+ (1,0) [0|1] ""  X
 SG_ DBG_pcs_PHC_llcEnable m34 : 49|1@1+ (1,0) [0|1] ""  X
 SG_ DBG_pcs_PHB_scr_A_HI m23 : 48|1@1+ (1,0) [0|1] ""  X
 SG_ DBG_pcs_PHA_llcLimitMaxTime m14 : 48|1@1+ (1,0) [0|1] ""  X
 SG_ DBG_pcs_PHC_scr_A_HI m33 : 48|1@1+ (1,0) [0|1] ""  X
 SG_ DBG_pcs_PHB_llcLimitMaxTime m24 : 48|1@1+ (1,0) [0|1] ""  X
 SG_ DBG_pcs_PHA_scr_A_HI m13 : 48|1@1+ (1,0) [0|1] ""  X
 SG_ DBG_pcs_PHC_llcLimitMaxTime m34 : 48|1@1+ (1,0) [0|1] ""  X
 SG_ DBG_pcs_PH_gain_A m6 : 44|10@1+ (0.001,0) [0|0] "-"  X
 SG_ DBG_DCDC_Short_Time_ns m103 : 44|12@1+ (3.90625,0) [0|16000] "ns"  X
 SG_ DBG_DCDC_Drv_RED_ns m102 : 44|10@1+ (1,0) [10|1023] "ns"  X
 SG_ DBG_pcs_PHA_pfcDeadTime m13 : 40|8@1+ (10,0) [0|0] "ns"  X
 SG_ DBG_pcs_PHA_llcMaxTime m14 : 40|8@1+ (1,0) [0|255] "mS"  X
 SG_ DBG_DCDC_tCommTargetOverride m108 : 40|1@1+ (1,0) [0|1] ""  X
 SG_ DBG_pcs_PHC_pfcDeadTime m33 : 40|8@1+ (10,0) [0|0] "ns"  X
 SG_ DBG_pcs_PHB_llcMaxTime m24 : 40|8@1+ (1,0) [0|255] "mS"  X
 SG_ DBG_pcs_PHB_pfcDeadTime m23 : 40|8@1+ (10,0) [0|0] "ns"  X
 SG_ DBG_DCDC_fastCANDebugEn m100 : 40|2@1+ (1,0) [0|3] ""  X
 SG_ DBG_pcs_PHC_llcMaxTime m34 : 40|8@1+ (1,0) [0|255] "mS"  X
 SG_ DBG_DCDC_debugFloat2 m106 : 36|28@1+ (3.725290312e-09,0) [0|1] "-"  X
 SG_ DBG_DCDC_numCyclesToRun m100 : 32|8@1- (1,0) [-1|127] "-"  X
 SG_ DBG_DCDC_Rise_Comp_Thresh_Amps m101 : 32|16@1- (0.0003814697226,0) [-25|0] "A"  X
 SG_ DBG_DCDC_Short_DelayTime_ns m103 : 32|12@1+ (1,0) [0|4095] "ns"  X
 SG_ DBG_DCDC_Zero_Time_ns m102 : 32|12@1+ (3.90625,0) [0|16000] "ns"  X
 SG_ DBG_DCDC_vLoopKi m105 : 28|20@1+ (9.5367431640625e-07,0) [0|1] "A"  X
 SG_ DBG_pcs_PHC_llcForceBridgeBOff m38 : 26|1@1+ (1,0) [0|1] ""  X
 SG_ DBG_pcs_PHA_llcForceBridgeBOff m36 : 26|1@1+ (1,0) [0|1] ""  X
 SG_ DBG_pcs_PHB_llcForceBridgeBOff m37 : 26|1@1+ (1,0) [0|1] ""  X
 SG_ DBG_pcs_phCOvrPhMan m32 : 25|1@1+ (1,0) [0|1] ""  X
 SG_ DBG_pcs_phBOvrPhMan m22 : 25|1@1+ (1,0) [0|1] ""  X
 SG_ DBG_pcs_PHC_llcForceBridgeAOff m38 : 25|1@1+ (1,0) [0|1] ""  X
 SG_ DBG_pcs_phAOvrPhMan m12 : 25|1@1+ (1,0) [0|1] ""  X
 SG_ DBG_pcs_PHB_llcForceBridgeAOff m37 : 25|1@1+ (1,0) [0|1] ""  X
 SG_ DBG_pcs_PHA_llcForceBridgeAOff m36 : 25|1@1+ (1,0) [0|1] ""  X
 SG_ DBG_pcs_PHA_llcPhase m14 : 24|16@1+ (0.002,0) [0|0] "%"  X
 SG_ DBG_DCDC_dumpVloopDataLog m100 : 24|8@1+ (1,0) [0|255] ""  X
 SG_ DBG_pcs_PHB_llcPhase m24 : 24|16@1+ (0.002,0) [0|0] "%"  X
 SG_ DBG_pcs_PH_debugFloat2 m7 : 24|16@1+ (1e-05,0) [0|0.65535] "1"  X
 SG_ DBG_pcs_PHC_llcSysOvrEnable m38 : 24|1@1+ (1,0) [0|1] ""  X
 SG_ DBG_DCDC_tCommTarget_ns m108 : 24|16@1+ (0.15625,0) [0|10240] "ns"  X
 SG_ DBG_pcs_PHC_closedLoopEnable m32 : 24|1@1+ (1,0) [0|1] ""  X
 SG_ DBG_pcs_DCDC_slowDischargeSlewRa m114 : 24|16@1+ (0.1,0) [0|10000] "V/s"  X
 SG_ DBG_pcs_DCDC_prechargeVTarget m111 : 24|16@1- (0.1,0) [-550|550] "V"  X
 SG_ DBG_pcs_PHB_llcSysOvrEnable m37 : 24|1@1+ (1,0) [0|1] ""  X
 SG_ DBG_pcs_PHC_llcPhase m34 : 24|16@1+ (0.002,0) [0|0] "%"  X
 SG_ DBG_pcs_DCDC_pchgResOvrValue m113 : 24|12@1+ (0.1,0) [0|409.5] "kOhm"  X
 SG_ DBG_pcs_PHA_pfcDuty m13 : 24|16@1+ (0.002,0) [0|0] "%"  X
 SG_ DBG_pcs_PHB_closedLoopEnable m22 : 24|1@1+ (1,0) [0|1] ""  X
 SG_ DBG_pcs_PHA_closedLoopEnable m12 : 24|1@1+ (1,0) [0|1] ""  X
 SG_ DBG_pcs_PHB_pfcDuty m23 : 24|16@1+ (0.002,0) [0|0] "%"  X
 SG_ DBG_pcs_PH_gain_B m6 : 24|20@1+ (1e-06,0) [0|0] "-"  X
 SG_ DBG_pcs_PHA_llcSysOvrEnable m36 : 24|1@1+ (1,0) [0|1] ""  X
 SG_ DBG_pcs_PHC_pfcDuty m33 : 24|16@1+ (0.002,0) [0|0] "%"  X
 SG_ DBG_pcs_mfgEolPwmEnTest m111 : 21|1@1+ (1,0) [0|1] ""  X
 SG_ DBG_DCDC_Short_FED_ns m103 : 20|12@1+ (1,0) [10|4095] "ns"  X
 SG_ DBG_pcs_PH_useControlParams m6 : 20|1@1+ (1,0) [0|1] ""  X
 SG_ DBG_DCDC_Drv_DelayTime_ns m102 : 20|12@1+ (1,0) [0|4095] "ns"  X
 SG_ DBG_pcs_chgDebugAuthentication m5 : 17|6@1+ (1,0) [0|60] ""  X
 SG_ DBG_DCDC_subStateFaultTrigger m112 : 16|1@1+ (1,0) [0|1] ""  X
 SG_ DBG_pcs_chgGridConfigOvrEnable m5 : 16|1@1+ (1,0) [0|1] ""  X
 SG_ DBG_DCDC_dumpCLADataLog m100 : 16|8@1+ (1,0) [0|255] ""  X
 SG_ DBG_pcs_PHC_outputCurrentLimit m32 : 16|8@1+ (0.1,0) [0|0] "A"  X
 SG_ DBG_pcs_PH_daccSelect m6 : 16|4@1+ (1,0) [0|10] ""  X
 SG_ DBG_DCDC_uTarget m109 : 16|32@1+ (2.328306437e-10,0) [0|1] "-"  X
 SG_ DBG_pcs_dcdcLvGtDrvOvrEnable m41 : 16|1@1+ (1,0) [0|1] ""  X
 SG_ DBG_pcs_PHC_scrPosOn m8 : 16|1@1+ (1,0) [0|1] ""  X
 SG_ DBG_pcs_PHB_outputCurrentLimit m22 : 16|8@1+ (0.1,0) [0|0] "A"  X
 SG_ DBG_DCDC_Fall_Comp_Thresh_Amps m101 : 16|16@1+ (0.0003814697226,0) [0|25] "A"  X
 SG_ DBG_pcs_PHA_outputCurrentLimit m12 : 16|8@1+ (0.1,0) [0|0] "A"  X
 SG_ DBG_DCDC_subStateFaultRepeat m112 : 15|1@1+ (1,0) [0|1] ""  X
 SG_ DBG_pcs_dcdcLvGtDrvEnable m41 : 15|1@1+ (1,0) [0|1] ""  X
 SG_ DBG_pcs_PHC_scrNegOn m8 : 15|1@1+ (1,0) [0|1] ""  X
 SG_ DBG_pcs_PHB_scrPosOn m8 : 14|1@1+ (1,0) [0|1] ""  X
 SG_ DBG_pcs_scrRefEpwmEnable m41 : 14|1@1+ (1,0) [0|1] ""  X
 SG_ DBG_pcs_PHB_scrNegOn m8 : 13|1@1+ (1,0) [0|1] ""  X
 SG_ DBG_DCDC_subStateFaultType m112 : 13|2@1+ (1,0) [0|3] ""  X
 SG_ DBG_pcs_scrRefEpwmOvrEnable m41 : 13|1@1+ (1,0) [0|1] ""  X
 SG_ DBG_pcs_PH_dacaSelect m6 : 12|4@1+ (1,0) [0|10] ""  X
 SG_ DBG_pcs_PHB_tempSysOvrValue m37 : 12|12@1- (0.1,0) [-204.8|204.7] "C"  X
 SG_ DBG_pcs_5VL1Enable m41 : 12|1@1+ (1,0) [0|1] ""  X
 SG_ DBG_pcs_analogMuxInhibitInv m150 : 12|1@1+ (1,0) [0|1] ""  X
 SG_ DBG_pcs_PHC_tempSysOvrValue m38 : 12|12@1- (0.1,0) [-204.8|204.7] "C"  X
 SG_ DBG_pcs_PHA_scrPosOn m8 : 12|1@1+ (1,0) [0|1] ""  X
 SG_ DBG_pcs_PHA_tempSysOvrValue m36 : 12|12@1- (0.1,0) [-204.8|204.7] "C"  X
 SG_ DBG_pcs_chgGridConfigToOvr m5 : 12|4@1+ (1,0) [0|8] ""  X
 SG_ DBG_pcs_PHB_tempSysOvrEnable m37 : 11|1@1+ (1,0) [0|1] ""  X
 SG_ DBG_pcs_DCDC_12VSupportVTarget m111 : 11|10@1+ (0.01,9) [9|16] "V"  X
 SG_ DBG_pcs_chgDlogDumpRequest m5 : 11|1@1+ (1,0) [0|1] ""  X
 SG_ DBG_pcs_PHA_scrNegOn m8 : 11|1@1+ (1,0) [0|1] ""  X
 SG_ DBG_pcs_PHA_tempSysOvrEnable m36 : 11|1@1+ (1,0) [0|1] ""  X
 SG_ DBG_pcs_analogMuxSelC m150 : 11|1@1+ (1,0) [0|1] ""  X
 SG_ DBG_pcs_phCLogicPwrEnable m41 : 11|1@1+ (1,0) [0|1] ""  X
 SG_ DBG_pcs_PHC_tempSysOvrEnable m38 : 11|1@1+ (1,0) [0|1] ""  X
 SG_ DBG_pcs_analogMuxSelB m150 : 10|1@1+ (1,0) [0|1] ""  X
 SG_ DBG_pcs_PHC_clearFaults m5 : 10|1@1+ (1,0) [0|1] ""  X
 SG_ DBG_pcs_PH_daccPhaseSelect m6 : 10|2@1+ (1,0) [0|3] ""  X
 SG_ DBG_pcs_phBLogicPwrEnable m41 : 10|1@1+ (1,0) [0|1] ""  X
 SG_ DBG_pcs_PHC_pfcForceLowOff m38 : 10|1@1+ (1,0) [0|1] ""  X
 SG_ DBG_pcs_PHB_pfcForceLowOff m37 : 10|1@1+ (1,0) [0|1] ""  X
 SG_ DBG_pcs_PHA_pfcForceLowOff m36 : 10|1@1+ (1,0) [0|1] ""  X
 SG_ DBG_pcs_PHC_dcCirculationEnable m8 : 10|1@1+ (1,0) [0|1] ""  X
 SG_ DBG_pcs_DCDC_pchgCapOvrValue m113 : 9|12@1+ (0.1,0) [0|409.5] "uF"  X
 SG_ DBG_pcs_phALogicPwrEnable m41 : 9|1@1+ (1,0) [0|1] ""  X
 SG_ DBG_pcs_PHB_clearFaults m5 : 9|1@1+ (1,0) [0|1] ""  X
 SG_ DBG_pcs_PHA_pfcForceHighOff m36 : 9|1@1+ (1,0) [0|1] ""  X
 SG_ DBG_pcs_DCDC_tempSysOvrValue m110 : 9|12@1- (0.1,0) [-204.8|204.7] "C"  X
 SG_ DBG_pcs_envOverrideValue m39 : 9|3@1+ (1,0) [0|5] ""  X
 SG_ DBG_pcs_analogMuxSelA m150 : 9|1@1+ (1,0) [0|1] ""  X
 SG_ DBG_pcs_DCDC_dcdcMode m111 : 9|2@1+ (1,0) [0|3] ""  X
 SG_ DBG_pcs_PHB_pfcForceHighOff m37 : 9|1@1+ (1,0) [0|1] ""  X
 SG_ DBG_pcs_PHB_dcCirculationEnable m8 : 9|1@1+ (1,0) [0|1] ""  X
 SG_ DBG_pcs_PH_intBusV m9 : 9|9@1+ (1,0) [0|511] "V"  X
 SG_ DBG_pcs_PHC_pfcForceHighOff m38 : 9|1@1+ (1,0) [0|1] ""  X
 SG_ DBG_DCDC_debugFloat1 m106 : 8|28@1+ (3.725290312e-09,0) [0|1] "-"  X
 SG_ DBG_pcs_PHB_pfcFreq m23 : 8|16@1+ (0.005,0) [0|0] "kHz"  X
 SG_ DBG_DCDC_subStateFaultTarget m112 : 8|5@1+ (1,0) [0|17] ""  X
 SG_ DBG_DCDC_uTargetOverride m109 : 8|1@1+ (1,0) [0|1] ""  X
 SG_ DBG_pcs_PH_debugFloat1 m7 : 8|16@1+ (1e-05,0) [0|0.65535] "1"  X
 SG_ DBG_pcs_DCDC_slowDischargeTarget m114 : 8|16@1+ (0.1,0) [0|500] "V"  X
 SG_ DBG_pcs_PH_dacaPhaseSelect m6 : 8|2@1+ (1,0) [0|3] ""  X
 SG_ DBG_pcs_PHB_inputCurrentLimit m22 : 8|8@1+ (0.1,0) [0|0] "A"  X
 SG_ DBG_pcs_PHC_pfcSysOvrEnable m38 : 8|1@1+ (1,0) [0|1] ""  X
 SG_ DBG_pcs_DCDC_systemCmdOvrEnable m111 : 8|1@1+ (1,0) [0|1] ""  X
 SG_ DBG_pcs_PHC_pfcFreq m33 : 8|16@1+ (0.005,0) [0|0] "kHz"  X
 SG_ DBG_DCDC_Short_RED_ns m103 : 8|12@1+ (1,0) [10|4095] "ns"  X
 SG_ DBG_pcs_PH_intBusVOvrEnable m9 : 8|1@1+ (1,0) [0|1] ""  X
 SG_ DBG_pcs_PHA_inputCurrentLimit m12 : 8|8@1+ (0.1,0) [0|0] "A"  X
 SG_ DBG_pcs_PHB_pfcSysOvrEnable m37 : 8|1@1+ (1,0) [0|1] ""  X
 SG_ DBG_pcs_PHB_llcFreq m24 : 8|16@1+ (0.005,0) [0|0] "kHz"  X
 SG_ DBG_pcs_envOverrideEnable m39 : 8|1@1+ (1,0) [0|1] ""  X
 SG_ DBG_pcs_DCDC_tempSysOvrEnable m110 : 8|1@1+ (1,0) [0|1] ""  X
 SG_ DBG_pcs_analogMuxOvrEnable m150 : 8|1@1+ (1,0) [0|1] ""  X
 SG_ DBG_DCDC_debugEnable m100 : 8|1@1+ (1,0) [0|1] ""  X
 SG_ DBG_DCDC_Drv_Time_ns m102 : 8|12@1+ (3.90625,0) [0|16000] "ns"  X
 SG_ DBG_pcs_PHA_pfcSysOvrEnable m36 : 8|1@1+ (1,0) [0|1] ""  X
 SG_ DBG_pcs_PHA_dcCirculationEnable m8 : 8|1@1+ (1,0) [0|1] ""  X
 SG_ DBG_DCDC_vTankTarget m108 : 8|16@1+ (0.015625,0) [0|1024] "V"  X
 SG_ DBG_pcs_PHC_llcFreq m34 : 8|16@1+ (0.005,0) [0|0] "kHz"  X
 SG_ DBG_DCDC_vLoopKp m105 : 8|20@1+ (9.5367431640625e-07,0) [0|1] "A"  X
 SG_ DBG_pcs_PHA_pfcFreq m13 : 8|16@1+ (0.005,0) [0|0] "kHz"  X
 SG_ DBG_DCDC_debugCompThreshEn m101 : 8|1@1+ (1,0) [0|1] ""  X
 SG_ DBG_DCDC_debugUint32 m107 : 8|32@1+ (1,0) [0|4294967295] "-"  X
 SG_ DBG_pcs_PHA_clearFaults m5 : 8|1@1+ (1,0) [0|1] ""  X
 SG_ DBG_pcs_PHC_inputCurrentLimit m32 : 8|8@1+ (0.1,0) [0|0] "A"  X
 SG_ DBG_pcs_chgLogicPwrOvrEnable m41 : 8|1@1+ (1,0) [0|1] ""  X
 SG_ DBG_DCDC_Snubber_Pulse_ns m104 : 8|12@1+ (3.90625,0) [0|16000] "ns"  X
 SG_ DBG_pcs_PHA_llcFreq m14 : 8|16@1+ (0.005,0) [0|0] "kHz"  X
 SG_ DBG_pcs_DCDC_pchgImpOvrEnable m113 : 8|1@1+ (1,0) [0|1] ""  X
 SG_ DBG_pcsControlSel M : 0|8@1+ (1,0) [5|150] ""  X

BO_ 1010 BMS_kwhCountersMultiplexed: 8 VEH
 SG_ BMS_kwhDischargeTotalModule4 m10 : 8|28@1+ (0.001,0) [0|268435.456] "KWh"  gtw
 SG_ BMS_kwhDischargeTotalModule3 m8 : 8|28@1+ (0.001,0) [0|268435.456] "KWh"  gtw
 SG_ BMS_kwhDischargeTotalModule2 m6 : 8|28@1+ (0.001,0) [0|268435.456] "KWh"  gtw
 SG_ BMS_kwhDischargeTotalModule1 m4 : 8|28@1+ (0.001,0) [0|268435.456] "KWh"  gtw
 SG_ BMS_dcChargerKwhTotal m1 : 8|32@1+ (0.001,0) [0|268435.456] "KWh"  gtw
 SG_ BMS_kwhDriveDischargeTotal m3 : 8|32@1+ (0.001,0) [0|268435.456] "KWh"  gtw
 SG_ BMS_acChargerKwhTotal m0 : 8|32@1+ (0.001,0) [0|268435.456] "KWh"  gtw
 SG_ BMS_kwhRegenChargeTotal m2 : 8|32@1+ (0.001,0) [0|268435.456] "KWh"  gtw
 SG_ BMS_kwhCounter_Id M : 0|4@1+ (1,0) [0|14] ""  X

BO_ 990 FC_alertMatrix6: 8 VEH
 SG_ FC_a321_FCAlertPlaceholder : 0|1@1+ (1,0) [0|1] ""  gtw

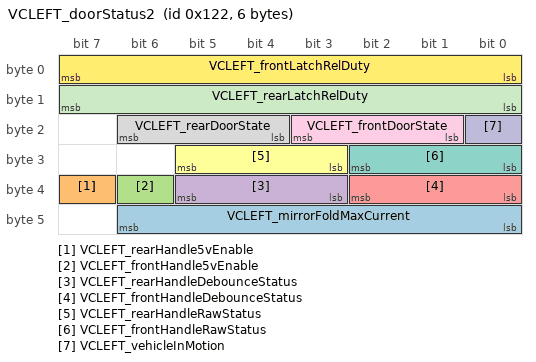
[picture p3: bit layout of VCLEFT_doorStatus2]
BO_ 290 VCLEFT_doorStatus2: 6 VEH
 SG_ VCLEFT_mirrorFoldMaxCurrent : 40|7@1- (0.046,0.0) [-3|3] "A"  X
 SG_ VCLEFT_rearHandle5vEnable : 39|1@1+ (1,0) [0|1] ""  gtw
 SG_ VCLEFT_frontHandle5vEnable : 38|1@1+ (1,0) [0|1] ""  gtw
 SG_ VCLEFT_rearHandleDebounceStatus : 35|3@1+ (1,0) [0|5] ""  gtw
 SG_ VCLEFT_frontHandleDebounceStatus : 32|3@1+ (1,0) [0|5] ""  gtw
 SG_ VCLEFT_rearHandleRawStatus : 27|3@1+ (1,0) [0|5] ""  gtw
 SG_ VCLEFT_frontHandleRawStatus : 24|3@1+ (1,0) [0|5] ""  gtw
 SG_ VCLEFT_rearDoorState : 20|3@1+ (1,0) [0|4] ""  gtw
 SG_ VCLEFT_frontDoorState : 17|3@1+ (1,0) [0|4] ""  gtw
 SG_ VCLEFT_vehicleInMotion : 16|1@1+ (1,0) [0|1] ""  gtw
 SG_ VCLEFT_rearLatchRelDuty : 8|8@1+ (1,0) [0|255] "%"  gtw
 SG_ VCLEFT_frontLatchRelDuty : 0|8@1+ (1,0) [0|255] "%"  gtw

BA_DEF_ SG_  "SystemSignalLongSymbol" STRING ;
BA_DEF_DEF_  "SystemSignalLongSymbol" "";
BA_ "SystemSignalLongSymbol" SG_ 1480 EPBL_a117_VEH_intrusionSensorSta "EPBL_a117_VEH_intrusionSensorStatus";
BA_ "SystemSignalLongSymbol" SG_ 800 BMS_a178_SW_Uncontrolled_Regen_P "BMS_a178_SW_Uncontrolled_Regen_PwrB";
BA_ "SystemSignalLongSymbol" SG_ 800 BMS_a092_SW_ChargePort_Mia_On_Hv "BMS_a092_SW_ChargePort_Mia_On_Hvs";
BA_ "SystemSignalLongSymbol" SG_ 1805 DBG_pcs_DCDC_slowDischargeSlewRa "DBG_pcs_DCDC_slowDischargeSlewRate";
BA_ "SystemSignalLongSymbol" SG_ 1805 DBG_pcs_DCDC_slowDischargeTarget "DBG_pcs_DCDC_slowDischargeTargetVoltage";
VAL_ 1480 EPBL_a175_nonterminalReason 5 "CSM_FAULT_APPLY_BLOCKED" 19 "CSM_FAULT_EPBM_MIA" 1 "CSM_FAULT_EPBM_DISABLED" 16 "CSM_FAULT_MOTOR_IDLE_FAULT" 8 "CSM_FAULT_TIMEOUT_APPLY_INRUSH" 3 "CSM_FAULT_STATE_MISMATCH" 13 "CSM_FAULT_TIMEOUT_EPBM_CUTOFF" 15 "CSM_FAULT_TIMEOUT_EPBM_START" 2 "CSM_FAULT_EPBM_FAULTED" 4 "CSM_FAULT_TIMEOUT_CALIBRATE" 12 "CSM_FAULT_TIMEOUT_RELEASE_COMPLETE" 17 "CSM_FAULT_MOTOR_ACTIVE_FAULT" 18 "CSM_FAULT_MOTOR_NOT_READY" 11 "CSM_FAULT_TIMEOUT_RELEASE_WAIT_FOR_ENDSTOP" 0 "CSM_FAULT_NONE" 9 "CSM_FAULT_TIMEOUT_WAIT_FOR_CLAMP" 14 "CSM_FAULT_TIMEOUT_NO_RAMP" 10 "CSM_FAULT_TIMEOUT_RELEASE_INRUSH" 21 "CSM_FAULT_REMOTE_MIA" 20 "CSM_FAULT_NVM_MISMATCH" 6 "CSM_FAULT_RELEASE_BLOCKED" 7 "CSM_FAULT_TIMEOUT_APPLY_COMPLETE" ;
VAL_ 1480 EPBL_a248_nonterminalReason 5 "CSM_FAULT_APPLY_BLOCKED" 19 "CSM_FAULT_EPBM_MIA" 1 "CSM_FAULT_EPBM_DISABLED" 16 "CSM_FAULT_MOTOR_IDLE_FAULT" 8 "CSM_FAULT_TIMEOUT_APPLY_INRUSH" 3 "CSM_FAULT_STATE_MISMATCH" 13 "CSM_FAULT_TIMEOUT_EPBM_CUTOFF" 15 "CSM_FAULT_TIMEOUT_EPBM_START" 2 "CSM_FAULT_EPBM_FAULTED" 4 "CSM_FAULT_TIMEOUT_CALIBRATE" 12 "CSM_FAULT_TIMEOUT_RELEASE_COMPLETE" 17 "CSM_FAULT_MOTOR_ACTIVE_FAULT" 18 "CSM_FAULT_MOTOR_NOT_READY" 11 "CSM_FAULT_TIMEOUT_RELEASE_WAIT_FOR_ENDSTOP" 0 "CSM_FAULT_NONE" 9 "CSM_FAULT_TIMEOUT_WAIT_FOR_CLAMP" 14 "CSM_FAULT_TIMEOUT_NO_RAMP" 10 "CSM_FAULT_TIMEOUT_RELEASE_INRUSH" 21 "CSM_FAULT_REMOTE_MIA" 20 "CSM_FAULT_NVM_MISMATCH" 6 "CSM_FAULT_RELEASE_BLOCKED" 7 "CSM_FAULT_TIMEOUT_APPLY_COMPLETE" ;
VAL_ 1480 EPBL_a176_nonterminalReason 5 "CSM_FAULT_APPLY_BLOCKED" 19 "CSM_FAULT_EPBM_MIA" 1 "CSM_FAULT_EPBM_DISABLED" 16 "CSM_FAULT_MOTOR_IDLE_FAULT" 8 "CSM_FAULT_TIMEOUT_APPLY_INRUSH" 3 "CSM_FAULT_STATE_MISMATCH" 13 "CSM_FAULT_TIMEOUT_EPBM_CUTOFF" 15 "CSM_FAULT_TIMEOUT_EPBM_START" 2 "CSM_FAULT_EPBM_FAULTED" 4 "CSM_FAULT_TIMEOUT_CALIBRATE" 12 "CSM_FAULT_TIMEOUT_RELEASE_COMPLETE" 17 "CSM_FAULT_MOTOR_ACTIVE_FAULT" 18 "CSM_FAULT_MOTOR_NOT_READY" 11 "CSM_FAULT_TIMEOUT_RELEASE_WAIT_FOR_ENDSTOP" 0 "CSM_FAULT_NONE" 9 "CSM_FAULT_TIMEOUT_WAIT_FOR_CLAMP" 14 "CSM_FAULT_TIMEOUT_NO_RAMP" 10 "CSM_FAULT_TIMEOUT_RELEASE_INRUSH" 21 "CSM_FAULT_REMOTE_MIA" 20 "CSM_FAULT_NVM_MISMATCH" 6 "CSM_FAULT_RELEASE_BLOCKED" 7 "CSM_FAULT_TIMEOUT_APPLY_COMPLETE" ;
VAL_ 1480 EPBL_a177_nonterminalReason 5 "CSM_FAULT_APPLY_BLOCKED" 19 "CSM_FAULT_EPBM_MIA" 1 "CSM_FAULT_EPBM_DISABLED" 16 "CSM_FAULT_MOTOR_IDLE_FAULT" 8 "CSM_FAULT_TIMEOUT_APPLY_INRUSH" 3 "CSM_FAULT_STATE_MISMATCH" 13 "CSM_FAULT_TIMEOUT_EPBM_CUTOFF" 15 "CSM_FAULT_TIMEOUT_EPBM_START" 2 "CSM_FAULT_EPBM_FAULTED" 4 "CSM_FAULT_TIMEOUT_CALIBRATE" 12 "CSM_FAULT_TIMEOUT_RELEASE_COMPLETE" 17 "CSM_FAULT_MOTOR_ACTIVE_FAULT" 18 "CSM_FAULT_MOTOR_NOT_READY" 11 "CSM_FAULT_TIMEOUT_RELEASE_WAIT_FOR_ENDSTOP" 0 "CSM_FAULT_NONE" 9 "CSM_FAULT_TIMEOUT_WAIT_FOR_CLAMP" 14 "CSM_FAULT_TIMEOUT_NO_RAMP" 10 "CSM_FAULT_TIMEOUT_RELEASE_INRUSH" 21 "CSM_FAULT_REMOTE_MIA" 20 "CSM_FAULT_NVM_MISMATCH" 6 "CSM_FAULT_RELEASE_BLOCKED" 7 "CSM_FAULT_TIMEOUT_APPLY_COMPLETE" ;
VAL_ 1480 EPBL_a190_nonterminalReason 5 "CSM_FAULT_APPLY_BLOCKED" 19 "CSM_FAULT_EPBM_MIA" 1 "CSM_FAULT_EPBM_DISABLED" 16 "CSM_FAULT_MOTOR_IDLE_FAULT" 8 "CSM_FAULT_TIMEOUT_APPLY_INRUSH" 3 "CSM_FAULT_STATE_MISMATCH" 13 "CSM_FAULT_TIMEOUT_EPBM_CUTOFF" 15 "CSM_FAULT_TIMEOUT_EPBM_START" 2 "CSM_FAULT_EPBM_FAULTED" 4 "CSM_FAULT_TIMEOUT_CALIBRATE" 12 "CSM_FAULT_TIMEOUT_RELEASE_COMPLETE" 17 "CSM_FAULT_MOTOR_ACTIVE_FAULT" 18 "CSM_FAULT_MOTOR_NOT_READY" 11 "CSM_FAULT_TIMEOUT_RELEASE_WAIT_FOR_ENDSTOP" 0 "CSM_FAULT_NONE" 9 "CSM_FAULT_TIMEOUT_WAIT_FOR_CLAMP" 14 "CSM_FAULT_TIMEOUT_NO_RAMP" 10 "CSM_FAULT_TIMEOUT_RELEASE_INRUSH" 21 "CSM_FAULT_REMOTE_MIA" 20 "CSM_FAULT_NVM_MISMATCH" 6 "CSM_FAULT_RELEASE_BLOCKED" 7 "CSM_FAULT_TIMEOUT_APPLY_COMPLETE" ;
VAL_ 1480 EPBL_a179_nonterminalReason 5 "CSM_FAULT_APPLY_BLOCKED" 19 "CSM_FAULT_EPBM_MIA" 1 "CSM_FAULT_EPBM_DISABLED" 16 "CSM_FAULT_MOTOR_IDLE_FAULT" 8 "CSM_FAULT_TIMEOUT_APPLY_INRUSH" 3 "CSM_FAULT_STATE_MISMATCH" 13 "CSM_FAULT_TIMEOUT_EPBM_CUTOFF" 15 "CSM_FAULT_TIMEOUT_EPBM_START" 2 "CSM_FAULT_EPBM_FAULTED" 4 "CSM_FAULT_TIMEOUT_CALIBRATE" 12 "CSM_FAULT_TIMEOUT_RELEASE_COMPLETE" 17 "CSM_FAULT_MOTOR_ACTIVE_FAULT" 18 "CSM_FAULT_MOTOR_NOT_READY" 11 "CSM_FAULT_TIMEOUT_RELEASE_WAIT_FOR_ENDSTOP" 0 "CSM_FAULT_NONE" 9 "CSM_FAULT_TIMEOUT_WAIT_FOR_CLAMP" 14 "CSM_FAULT_TIMEOUT_NO_RAMP" 10 "CSM_FAULT_TIMEOUT_RELEASE_INRUSH" 21 "CSM_FAULT_REMOTE_MIA" 20 "CSM_FAULT_NVM_MISMATCH" 6 "CSM_FAULT_RELEASE_BLOCKED" 7 "CSM_FAULT_TIMEOUT_APPLY_COMPLETE" ;
VAL_ 1480 EPBL_a174_nonterminalReason 5 "CSM_FAULT_APPLY_BLOCKED" 19 "CSM_FAULT_EPBM_MIA" 1 "CSM_FAULT_EPBM_DISABLED" 16 "CSM_FAULT_MOTOR_IDLE_FAULT" 8 "CSM_FAULT_TIMEOUT_APPLY_INRUSH" 3 "CSM_FAULT_STATE_MISMATCH" 13 "CSM_FAULT_TIMEOUT_EPBM_CUTOFF" 15 "CSM_FAULT_TIMEOUT_EPBM_START" 2 "CSM_FAULT_EPBM_FAULTED" 4 "CSM_FAULT_TIMEOUT_CALIBRATE" 12 "CSM_FAULT_TIMEOUT_RELEASE_COMPLETE" 17 "CSM_FAULT_MOTOR_ACTIVE_FAULT" 18 "CSM_FAULT_MOTOR_NOT_READY" 11 "CSM_FAULT_TIMEOUT_RELEASE_WAIT_FOR_ENDSTOP" 0 "CSM_FAULT_NONE" 9 "CSM_FAULT_TIMEOUT_WAIT_FOR_CLAMP" 14 "CSM_FAULT_TIMEOUT_NO_RAMP" 10 "CSM_FAULT_TIMEOUT_RELEASE_INRUSH" 21 "CSM_FAULT_REMOTE_MIA" 20 "CSM_FAULT_NVM_MISMATCH" 6 "CSM_FAULT_RELEASE_BLOCKED" 7 "CSM_FAULT_TIMEOUT_APPLY_COMPLETE" ;
VAL_ 1480 EPBL_a191_nonterminalReason 5 "CSM_FAULT_APPLY_BLOCKED" 19 "CSM_FAULT_EPBM_MIA" 1 "CSM_FAULT_EPBM_DISABLED" 16 "CSM_FAULT_MOTOR_IDLE_FAULT" 8 "CSM_FAULT_TIMEOUT_APPLY_INRUSH" 3 "CSM_FAULT_STATE_MISMATCH" 13 "CSM_FAULT_TIMEOUT_EPBM_CUTOFF" 15 "CSM_FAULT_TIMEOUT_EPBM_START" 2 "CSM_FAULT_EPBM_FAULTED" 4 "CSM_FAULT_TIMEOUT_CALIBRATE" 12 "CSM_FAULT_TIMEOUT_RELEASE_COMPLETE" 17 "CSM_FAULT_MOTOR_ACTIVE_FAULT" 18 "CSM_FAULT_MOTOR_NOT_READY" 11 "CSM_FAULT_TIMEOUT_RELEASE_WAIT_FOR_ENDSTOP" 0 "CSM_FAULT_NONE" 9 "CSM_FAULT_TIMEOUT_WAIT_FOR_CLAMP" 14 "CSM_FAULT_TIMEOUT_NO_RAMP" 10 "CSM_FAULT_TIMEOUT_RELEASE_INRUSH" 21 "CSM_FAULT_REMOTE_MIA" 20 "CSM_FAULT_NVM_MISMATCH" 6 "CSM_FAULT_RELEASE_BLOCKED" 7 "CSM_FAULT_TIMEOUT_APPLY_COMPLETE" ;
VAL_ 1480 EPBL_a247_nonterminalReason 5 "CSM_FAULT_APPLY_BLOCKED" 19 "CSM_FAULT_EPBM_MIA" 1 "CSM_FAULT_EPBM_DISABLED" 16 "CSM_FAULT_MOTOR_IDLE_FAULT" 8 "CSM_FAULT_TIMEOUT_APPLY_INRUSH" 3 "CSM_FAULT_STATE_MISMATCH" 13 "CSM_FAULT_TIMEOUT_EPBM_CUTOFF" 15 "CSM_FAULT_TIMEOUT_EPBM_START" 2 "CSM_FAULT_EPBM_FAULTED" 4 "CSM_FAULT_TIMEOUT_CALIBRATE" 12 "CSM_FAULT_TIMEOUT_RELEASE_COMPLETE" 17 "CSM_FAULT_MOTOR_ACTIVE_FAULT" 18 "CSM_FAULT_MOTOR_NOT_READY" 11 "CSM_FAULT_TIMEOUT_RELEASE_WAIT_FOR_ENDSTOP" 0 "CSM_FAULT_NONE" 9 "CSM_FAULT_TIMEOUT_WAIT_FOR_CLAMP" 14 "CSM_FAULT_TIMEOUT_NO_RAMP" 10 "CSM_FAULT_TIMEOUT_RELEASE_INRUSH" 21 "CSM_FAULT_REMOTE_MIA" 20 "CSM_FAULT_NVM_MISMATCH" 6 "CSM_FAULT_RELEASE_BLOCKED" 7 "CSM_FAULT_TIMEOUT_APPLY_COMPLETE" ;
VAL_ 1480 EPBL_a138_monitorState 5 "EPB_SAVED_CALIPERSTATE_SERVICE" 1 "EPB_SAVED_CALIPERSTATE_UNKNOWN" 4 "EPB_SAVED_CALIPERSTATE_OPEN" 2 "EPB_SAVED_CALIPERSTATE_REAPPLY" 0 "EPB_SAVED_CALIPERSTATE_UNSAVED" 3 "EPB_SAVED_CALIPERSTATE_PARK" ;
VAL_ 1480 EPBL_a179_esmOpTrigger 20 "EPB_TRIGGER_TIMEOUT" 2 "EPB_TRIGGER_PBUTTON_PRESSED_FAST" 19 "EPB_TRIGGER_SPEED_FAST" 3 "EPB_TRIGGER_PBUTTON_PRESSED_UNKNOWN" 27 "EPB_TRIGGER_EPBM_DISQUALIFIED" 10 "EPB_TRIGGER_WINCHMODE_UNAVAILABLE" 28 "EPB_TRIGGER_ACCELERATION" 12 "EPB_TRIGGER_DIAG_CLOSE" 24 "EPB_TRIGGER_FAULT" 25 "EPB_TRIGGER_SUMMON_FAULT" 30 "EPB_TRIGGER_DRIVER_IS_LEAVING" 18 "EPB_TRIGGER_SPEED_OKAYTOPARK" 1 "EPB_TRIGGER_PBUTTON_PRESSED_OKTOPARK" 4 "EPB_TRIGGER_PBUTTON_RELEASED" 14 "EPB_TRIGGER_DIAG_EXIT" 21 "EPB_TRIGGER_SAVESTATE_ON_BOOT" 6 "EPB_TRIGGER_DI_UNPARK" 23 "EPB_TRIGGER_SUMMON_COMPLETE" 22 "EPB_TRIGGER_REAPPLY" 26 "EPB_TRIGGER_DISQUALIFIED" 16 "EPB_TRIGGER_USER_CANCEL" 13 "EPB_TRIGGER_DIAG_OPEN" 11 "EPB_TRIGGER_SERVICE" 5 "EPB_TRIGGER_ACTIVE_PARK_REQUEST" 15 "EPB_TRIGGER_USER_CONFIRMED" 8 "EPB_TRIGGER_WINCHMODE_EXIT" 9 "EPB_TRIGGER_WINCHMODE_ENTER" 17 "EPB_TRIGGER_SPEED_STOPPED" 0 "EPB_TRIGGER_PBUTTON_PRESSED_STOPPED" 7 "EPB_TRIGGER_TOUCHSCREEN" 29 "EPB_TRIGGER_SYSTEM_APPLY" ;
VAL_ 1480 EPBL_a190_esmOpTrigger 20 "EPB_TRIGGER_TIMEOUT" 2 "EPB_TRIGGER_PBUTTON_PRESSED_FAST" 19 "EPB_TRIGGER_SPEED_FAST" 3 "EPB_TRIGGER_PBUTTON_PRESSED_UNKNOWN" 27 "EPB_TRIGGER_EPBM_DISQUALIFIED" 10 "EPB_TRIGGER_WINCHMODE_UNAVAILABLE" 28 "EPB_TRIGGER_ACCELERATION" 12 "EPB_TRIGGER_DIAG_CLOSE" 24 "EPB_TRIGGER_FAULT" 25 "EPB_TRIGGER_SUMMON_FAULT" 30 "EPB_TRIGGER_DRIVER_IS_LEAVING" 18 "EPB_TRIGGER_SPEED_OKAYTOPARK" 1 "EPB_TRIGGER_PBUTTON_PRESSED_OKTOPARK" 4 "EPB_TRIGGER_PBUTTON_RELEASED" 14 "EPB_TRIGGER_DIAG_EXIT" 21 "EPB_TRIGGER_SAVESTATE_ON_BOOT" 6 "EPB_TRIGGER_DI_UNPARK" 23 "EPB_TRIGGER_SUMMON_COMPLETE" 22 "EPB_TRIGGER_REAPPLY" 26 "EPB_TRIGGER_DISQUALIFIED" 16 "EPB_TRIGGER_USER_CANCEL" 13 "EPB_TRIGGER_DIAG_OPEN" 11 "EPB_TRIGGER_SERVICE" 5 "EPB_TRIGGER_ACTIVE_PARK_REQUEST" 15 "EPB_TRIGGER_USER_CONFIRMED" 8 "EPB_TRIGGER_WINCHMODE_EXIT" 9 "EPB_TRIGGER_WINCHMODE_ENTER" 17 "EPB_TRIGGER_SPEED_STOPPED" 0 "EPB_TRIGGER_PBUTTON_PRESSED_STOPPED" 7 "EPB_TRIGGER_TOUCHSCREEN" 29 "EPB_TRIGGER_SYSTEM_APPLY" ;
VAL_ 1480 EPBL_a248_esmOpTrigger 20 "EPB_TRIGGER_TIMEOUT" 2 "EPB_TRIGGER_PBUTTON_PRESSED_FAST" 19 "EPB_TRIGGER_SPEED_FAST" 3 "EPB_TRIGGER_PBUTTON_PRESSED_UNKNOWN" 27 "EPB_TRIGGER_EPBM_DISQUALIFIED" 10 "EPB_TRIGGER_WINCHMODE_UNAVAILABLE" 28 "EPB_TRIGGER_ACCELERATION" 12 "EPB_TRIGGER_DIAG_CLOSE" 24 "EPB_TRIGGER_FAULT" 25 "EPB_TRIGGER_SUMMON_FAULT" 30 "EPB_TRIGGER_DRIVER_IS_LEAVING" 18 "EPB_TRIGGER_SPEED_OKAYTOPARK" 1 "EPB_TRIGGER_PBUTTON_PRESSED_OKTOPARK" 4 "EPB_TRIGGER_PBUTTON_RELEASED" 14 "EPB_TRIGGER_DIAG_EXIT" 21 "EPB_TRIGGER_SAVESTATE_ON_BOOT" 6 "EPB_TRIGGER_DI_UNPARK" 23 "EPB_TRIGGER_SUMMON_COMPLETE" 22 "EPB_TRIGGER_REAPPLY" 26 "EPB_TRIGGER_DISQUALIFIED" 16 "EPB_TRIGGER_USER_CANCEL" 13 "EPB_TRIGGER_DIAG_OPEN" 11 "EPB_TRIGGER_SERVICE" 5 "EPB_TRIGGER_ACTIVE_PARK_REQUEST" 15 "EPB_TRIGGER_USER_CONFIRMED" 8 "EPB_TRIGGER_WINCHMODE_EXIT" 9 "EPB_TRIGGER_WINCHMODE_ENTER" 17 "EPB_TRIGGER_SPEED_STOPPED" 0 "EPB_TRIGGER_PBUTTON_PRESSED_STOPPED" 7 "EPB_TRIGGER_TOUCHSCREEN" 29 "EPB_TRIGGER_SYSTEM_APPLY" ;
VAL_ 1480 EPBL_a175_esmOpTrigger 20 "EPB_TRIGGER_TIMEOUT" 2 "EPB_TRIGGER_PBUTTON_PRESSED_FAST" 19 "EPB_TRIGGER_SPEED_FAST" 3 "EPB_TRIGGER_PBUTTON_PRESSED_UNKNOWN" 27 "EPB_TRIGGER_EPBM_DISQUALIFIED" 10 "EPB_TRIGGER_WINCHMODE_UNAVAILABLE" 28 "EPB_TRIGGER_ACCELERATION" 12 "EPB_TRIGGER_DIAG_CLOSE" 24 "EPB_TRIGGER_FAULT" 25 "EPB_TRIGGER_SUMMON_FAULT" 30 "EPB_TRIGGER_DRIVER_IS_LEAVING" 18 "EPB_TRIGGER_SPEED_OKAYTOPARK" 1 "EPB_TRIGGER_PBUTTON_PRESSED_OKTOPARK" 4 "EPB_TRIGGER_PBUTTON_RELEASED" 14 "EPB_TRIGGER_DIAG_EXIT" 21 "EPB_TRIGGER_SAVESTATE_ON_BOOT" 6 "EPB_TRIGGER_DI_UNPARK" 23 "EPB_TRIGGER_SUMMON_COMPLETE" 22 "EPB_TRIGGER_REAPPLY" 26 "EPB_TRIGGER_DISQUALIFIED" 16 "EPB_TRIGGER_USER_CANCEL" 13 "EPB_TRIGGER_DIAG_OPEN" 11 "EPB_TRIGGER_SERVICE" 5 "EPB_TRIGGER_ACTIVE_PARK_REQUEST" 15 "EPB_TRIGGER_USER_CONFIRMED" 8 "EPB_TRIGGER_WINCHMODE_EXIT" 9 "EPB_TRIGGER_WINCHMODE_ENTER" 17 "EPB_TRIGGER_SPEED_STOPPED" 0 "EPB_TRIGGER_PBUTTON_PRESSED_STOPPED" 7 "EPB_TRIGGER_TOUCHSCREEN" 29 "EPB_TRIGGER_SYSTEM_APPLY" ;
VAL_ 1480 EPBL_a247_esmOpTrigger 20 "EPB_TRIGGER_TIMEOUT" 2 "EPB_TRIGGER_PBUTTON_PRESSED_FAST" 19 "EPB_TRIGGER_SPEED_FAST" 3 "EPB_TRIGGER_PBUTTON_PRESSED_UNKNOWN" 27 "EPB_TRIGGER_EPBM_DISQUALIFIED" 10 "EPB_TRIGGER_WINCHMODE_UNAVAILABLE" 28 "EPB_TRIGGER_ACCELERATION" 12 "EPB_TRIGGER_DIAG_CLOSE" 24 "EPB_TRIGGER_FAULT" 25 "EPB_TRIGGER_SUMMON_FAULT" 30 "EPB_TRIGGER_DRIVER_IS_LEAVING" 18 "EPB_TRIGGER_SPEED_OKAYTOPARK" 1 "EPB_TRIGGER_PBUTTON_PRESSED_OKTOPARK" 4 "EPB_TRIGGER_PBUTTON_RELEASED" 14 "EPB_TRIGGER_DIAG_EXIT" 21 "EPB_TRIGGER_SAVESTATE_ON_BOOT" 6 "EPB_TRIGGER_DI_UNPARK" 23 "EPB_TRIGGER_SUMMON_COMPLETE" 22 "EPB_TRIGGER_REAPPLY" 26 "EPB_TRIGGER_DISQUALIFIED" 16 "EPB_TRIGGER_USER_CANCEL" 13 "EPB_TRIGGER_DIAG_OPEN" 11 "EPB_TRIGGER_SERVICE" 5 "EPB_TRIGGER_ACTIVE_PARK_REQUEST" 15 "EPB_TRIGGER_USER_CONFIRMED" 8 "EPB_TRIGGER_WINCHMODE_EXIT" 9 "EPB_TRIGGER_WINCHMODE_ENTER" 17 "EPB_TRIGGER_SPEED_STOPPED" 0 "EPB_TRIGGER_PBUTTON_PRESSED_STOPPED" 7 "EPB_TRIGGER_TOUCHSCREEN" 29 "EPB_TRIGGER_SYSTEM_APPLY" ;
VAL_ 1480 EPBL_a191_esmOpTrigger 20 "EPB_TRIGGER_TIMEOUT" 2 "EPB_TRIGGER_PBUTTON_PRESSED_FAST" 19 "EPB_TRIGGER_SPEED_FAST" 3 "EPB_TRIGGER_PBUTTON_PRESSED_UNKNOWN" 27 "EPB_TRIGGER_EPBM_DISQUALIFIED" 10 "EPB_TRIGGER_WINCHMODE_UNAVAILABLE" 28 "EPB_TRIGGER_ACCELERATION" 12 "EPB_TRIGGER_DIAG_CLOSE" 24 "EPB_TRIGGER_FAULT" 25 "EPB_TRIGGER_SUMMON_FAULT" 30 "EPB_TRIGGER_DRIVER_IS_LEAVING" 18 "EPB_TRIGGER_SPEED_OKAYTOPARK" 1 "EPB_TRIGGER_PBUTTON_PRESSED_OKTOPARK" 4 "EPB_TRIGGER_PBUTTON_RELEASED" 14 "EPB_TRIGGER_DIAG_EXIT" 21 "EPB_TRIGGER_SAVESTATE_ON_BOOT" 6 "EPB_TRIGGER_DI_UNPARK" 23 "EPB_TRIGGER_SUMMON_COMPLETE" 22 "EPB_TRIGGER_REAPPLY" 26 "EPB_TRIGGER_DISQUALIFIED" 16 "EPB_TRIGGER_USER_CANCEL" 13 "EPB_TRIGGER_DIAG_OPEN" 11 "EPB_TRIGGER_SERVICE" 5 "EPB_TRIGGER_ACTIVE_PARK_REQUEST" 15 "EPB_TRIGGER_USER_CONFIRMED" 8 "EPB_TRIGGER_WINCHMODE_EXIT" 9 "EPB_TRIGGER_WINCHMODE_ENTER" 17 "EPB_TRIGGER_SPEED_STOPPED" 0 "EPB_TRIGGER_PBUTTON_PRESSED_STOPPED" 7 "EPB_TRIGGER_TOUCHSCREEN" 29 "EPB_TRIGGER_SYSTEM_APPLY" ;
VAL_ 1480 EPBL_a176_esmOpTrigger 20 "EPB_TRIGGER_TIMEOUT" 2 "EPB_TRIGGER_PBUTTON_PRESSED_FAST" 19 "EPB_TRIGGER_SPEED_FAST" 3 "EPB_TRIGGER_PBUTTON_PRESSED_UNKNOWN" 27 "EPB_TRIGGER_EPBM_DISQUALIFIED" 10 "EPB_TRIGGER_WINCHMODE_UNAVAILABLE" 28 "EPB_TRIGGER_ACCELERATION" 12 "EPB_TRIGGER_DIAG_CLOSE" 24 "EPB_TRIGGER_FAULT" 25 "EPB_TRIGGER_SUMMON_FAULT" 30 "EPB_TRIGGER_DRIVER_IS_LEAVING" 18 "EPB_TRIGGER_SPEED_OKAYTOPARK" 1 "EPB_TRIGGER_PBUTTON_PRESSED_OKTOPARK" 4 "EPB_TRIGGER_PBUTTON_RELEASED" 14 "EPB_TRIGGER_DIAG_EXIT" 21 "EPB_TRIGGER_SAVESTATE_ON_BOOT" 6 "EPB_TRIGGER_DI_UNPARK" 23 "EPB_TRIGGER_SUMMON_COMPLETE" 22 "EPB_TRIGGER_REAPPLY" 26 "EPB_TRIGGER_DISQUALIFIED" 16 "EPB_TRIGGER_USER_CANCEL" 13 "EPB_TRIGGER_DIAG_OPEN" 11 "EPB_TRIGGER_SERVICE" 5 "EPB_TRIGGER_ACTIVE_PARK_REQUEST" 15 "EPB_TRIGGER_USER_CONFIRMED" 8 "EPB_TRIGGER_WINCHMODE_EXIT" 9 "EPB_TRIGGER_WINCHMODE_ENTER" 17 "EPB_TRIGGER_SPEED_STOPPED" 0 "EPB_TRIGGER_PBUTTON_PRESSED_STOPPED" 7 "EPB_TRIGGER_TOUCHSCREEN" 29 "EPB_TRIGGER_SYSTEM_APPLY" ;
VAL_ 1480 EPBL_a138_localState 5 "EPB_SAVED_CALIPERSTATE_SERVICE" 1 "EPB_SAVED_CALIPERSTATE_UNKNOWN" 4 "EPB_SAVED_CALIPERSTATE_OPEN" 2 "EPB_SAVED_CALIPERSTATE_REAPPLY" 0 "EPB_SAVED_CALIPERSTATE_UNSAVED" 3 "EPB_SAVED_CALIPERSTATE_PARK" ;
VAL_ 1480 EPBL_a177_esmOpTrigger 20 "EPB_TRIGGER_TIMEOUT" 2 "EPB_TRIGGER_PBUTTON_PRESSED_FAST" 19 "EPB_TRIGGER_SPEED_FAST" 3 "EPB_TRIGGER_PBUTTON_PRESSED_UNKNOWN" 27 "EPB_TRIGGER_EPBM_DISQUALIFIED" 10 "EPB_TRIGGER_WINCHMODE_UNAVAILABLE" 28 "EPB_TRIGGER_ACCELERATION" 12 "EPB_TRIGGER_DIAG_CLOSE" 24 "EPB_TRIGGER_FAULT" 25 "EPB_TRIGGER_SUMMON_FAULT" 30 "EPB_TRIGGER_DRIVER_IS_LEAVING" 18 "EPB_TRIGGER_SPEED_OKAYTOPARK" 1 "EPB_TRIGGER_PBUTTON_PRESSED_OKTOPARK" 4 "EPB_TRIGGER_PBUTTON_RELEASED" 14 "EPB_TRIGGER_DIAG_EXIT" 21 "EPB_TRIGGER_SAVESTATE_ON_BOOT" 6 "EPB_TRIGGER_DI_UNPARK" 23 "EPB_TRIGGER_SUMMON_COMPLETE" 22 "EPB_TRIGGER_REAPPLY" 26 "EPB_TRIGGER_DISQUALIFIED" 16 "EPB_TRIGGER_USER_CANCEL" 13 "EPB_TRIGGER_DIAG_OPEN" 11 "EPB_TRIGGER_SERVICE" 5 "EPB_TRIGGER_ACTIVE_PARK_REQUEST" 15 "EPB_TRIGGER_USER_CONFIRMED" 8 "EPB_TRIGGER_WINCHMODE_EXIT" 9 "EPB_TRIGGER_WINCHMODE_ENTER" 17 "EPB_TRIGGER_SPEED_STOPPED" 0 "EPB_TRIGGER_PBUTTON_PRESSED_STOPPED" 7 "EPB_TRIGGER_TOUCHSCREEN" 29 "EPB_TRIGGER_SYSTEM_APPLY" ;
VAL_ 1480 EPBL_a174_esmOpTrigger 20 "EPB_TRIGGER_TIMEOUT" 2 "EPB_TRIGGER_PBUTTON_PRESSED_FAST" 19 "EPB_TRIGGER_SPEED_FAST" 3 "EPB_TRIGGER_PBUTTON_PRESSED_UNKNOWN" 27 "EPB_TRIGGER_EPBM_DISQUALIFIED" 10 "EPB_TRIGGER_WINCHMODE_UNAVAILABLE" 28 "EPB_TRIGGER_ACCELERATION" 12 "EPB_TRIGGER_DIAG_CLOSE" 24 "EPB_TRIGGER_FAULT" 25 "EPB_TRIGGER_SUMMON_FAULT" 30 "EPB_TRIGGER_DRIVER_IS_LEAVING" 18 "EPB_TRIGGER_SPEED_OKAYTOPARK" 1 "EPB_TRIGGER_PBUTTON_PRESSED_OKTOPARK" 4 "EPB_TRIGGER_PBUTTON_RELEASED" 14 "EPB_TRIGGER_DIAG_EXIT" 21 "EPB_TRIGGER_SAVESTATE_ON_BOOT" 6 "EPB_TRIGGER_DI_UNPARK" 23 "EPB_TRIGGER_SUMMON_COMPLETE" 22 "EPB_TRIGGER_REAPPLY" 26 "EPB_TRIGGER_DISQUALIFIED" 16 "EPB_TRIGGER_USER_CANCEL" 13 "EPB_TRIGGER_DIAG_OPEN" 11 "EPB_TRIGGER_SERVICE" 5 "EPB_TRIGGER_ACTIVE_PARK_REQUEST" 15 "EPB_TRIGGER_USER_CONFIRMED" 8 "EPB_TRIGGER_WINCHMODE_EXIT" 9 "EPB_TRIGGER_WINCHMODE_ENTER" 17 "EPB_TRIGGER_SPEED_STOPPED" 0 "EPB_TRIGGER_PBUTTON_PRESSED_STOPPED" 7 "EPB_TRIGGER_TOUCHSCREEN" 29 "EPB_TRIGGER_SYSTEM_APPLY" ;
VAL_ 1480 EPBL_a183_invalidateReason 0 "EPB_CDP_ESP_MIA" 3 "EPB_CDP_EPBM_INVALID" 2 "EPB_CDP_EPBM_MIA" 1 "EPB_CDP_ESP_INVALID" ;
VAL_ 1480 EPBL_a176_csmFaultReason 5 "CSM_FAULT_APPLY_BLOCKED" 19 "CSM_FAULT_EPBM_MIA" 1 "CSM_FAULT_EPBM_DISABLED" 16 "CSM_FAULT_MOTOR_IDLE_FAULT" 8 "CSM_FAULT_TIMEOUT_APPLY_INRUSH" 3 "CSM_FAULT_STATE_MISMATCH" 13 "CSM_FAULT_TIMEOUT_EPBM_CUTOFF" 15 "CSM_FAULT_TIMEOUT_EPBM_START" 2 "CSM_FAULT_EPBM_FAULTED" 4 "CSM_FAULT_TIMEOUT_CALIBRATE" 12 "CSM_FAULT_TIMEOUT_RELEASE_COMPLETE" 17 "CSM_FAULT_MOTOR_ACTIVE_FAULT" 18 "CSM_FAULT_MOTOR_NOT_READY" 11 "CSM_FAULT_TIMEOUT_RELEASE_WAIT_FOR_ENDSTOP" 0 "CSM_FAULT_NONE" 9 "CSM_FAULT_TIMEOUT_WAIT_FOR_CLAMP" 14 "CSM_FAULT_TIMEOUT_NO_RAMP" 10 "CSM_FAULT_TIMEOUT_RELEASE_INRUSH" 21 "CSM_FAULT_REMOTE_MIA" 20 "CSM_FAULT_NVM_MISMATCH" 6 "CSM_FAULT_RELEASE_BLOCKED" 7 "CSM_FAULT_TIMEOUT_APPLY_COMPLETE" ;
VAL_ 1480 EPBL_a246_esmOpTrigger 20 "EPB_TRIGGER_TIMEOUT" 2 "EPB_TRIGGER_PBUTTON_PRESSED_FAST" 19 "EPB_TRIGGER_SPEED_FAST" 3 "EPB_TRIGGER_PBUTTON_PRESSED_UNKNOWN" 27 "EPB_TRIGGER_EPBM_DISQUALIFIED" 10 "EPB_TRIGGER_WINCHMODE_UNAVAILABLE" 28 "EPB_TRIGGER_ACCELERATION" 12 "EPB_TRIGGER_DIAG_CLOSE" 24 "EPB_TRIGGER_FAULT" 25 "EPB_TRIGGER_SUMMON_FAULT" 30 "EPB_TRIGGER_DRIVER_IS_LEAVING" 18 "EPB_TRIGGER_SPEED_OKAYTOPARK" 1 "EPB_TRIGGER_PBUTTON_PRESSED_OKTOPARK" 4 "EPB_TRIGGER_PBUTTON_RELEASED" 14 "EPB_TRIGGER_DIAG_EXIT" 21 "EPB_TRIGGER_SAVESTATE_ON_BOOT" 6 "EPB_TRIGGER_DI_UNPARK" 23 "EPB_TRIGGER_SUMMON_COMPLETE" 22 "EPB_TRIGGER_REAPPLY" 26 "EPB_TRIGGER_DISQUALIFIED" 16 "EPB_TRIGGER_USER_CANCEL" 13 "EPB_TRIGGER_DIAG_OPEN" 11 "EPB_TRIGGER_SERVICE" 5 "EPB_TRIGGER_ACTIVE_PARK_REQUEST" 15 "EPB_TRIGGER_USER_CONFIRMED" 8 "EPB_TRIGGER_WINCHMODE_EXIT" 9 "EPB_TRIGGER_WINCHMODE_ENTER" 17 "EPB_TRIGGER_SPEED_STOPPED" 0 "EPB_TRIGGER_PBUTTON_PRESSED_STOPPED" 7 "EPB_TRIGGER_TOUCHSCREEN" 29 "EPB_TRIGGER_SYSTEM_APPLY" ;
VAL_ 1480 EPBL_a188_nextState 11 "ESM_PARK_PENDING" 1 "ESM_PARK" 3 "ESM_OPEN" 5 "ESM_SUMMON" 0 "ESM_INIT" 6 "ESM_WINCHMODE" 13 "ESM_SUMMON_PARK" 18 "ESM_DYNAMIC_EXTERNAL_EXIT" 19 "ESM_UNKNOWN" 12 "ESM_WINCHMODE_PENDING" 8 "ESM_DIAGNOSTIC_PARK" 16 "ESM_LATCHED_DYNAMIC_EXTERNAL" 2 "ESM_REAPPLY" 9 "ESM_DIAGNOSTIC_OPEN" 14 "ESM_DYNAMIC_EXTERNAL" 10 "ESM_DYNAMIC_PARK" 17 "ESM_SERVICE_PENDING" 15 "ESM_DYNAMIC_PENDING" 7 "ESM_SERVICE" 4 "ESM_DYNAMIC" ;
VAL_ 1480 EPBL_a191_csmFaultReason 5 "CSM_FAULT_APPLY_BLOCKED" 19 "CSM_FAULT_EPBM_MIA" 1 "CSM_FAULT_EPBM_DISABLED" 16 "CSM_FAULT_MOTOR_IDLE_FAULT" 8 "CSM_FAULT_TIMEOUT_APPLY_INRUSH" 3 "CSM_FAULT_STATE_MISMATCH" 13 "CSM_FAULT_TIMEOUT_EPBM_CUTOFF" 15 "CSM_FAULT_TIMEOUT_EPBM_START" 2 "CSM_FAULT_EPBM_FAULTED" 4 "CSM_FAULT_TIMEOUT_CALIBRATE" 12 "CSM_FAULT_TIMEOUT_RELEASE_COMPLETE" 17 "CSM_FAULT_MOTOR_ACTIVE_FAULT" 18 "CSM_FAULT_MOTOR_NOT_READY" 11 "CSM_FAULT_TIMEOUT_RELEASE_WAIT_FOR_ENDSTOP" 0 "CSM_FAULT_NONE" 9 "CSM_FAULT_TIMEOUT_WAIT_FOR_CLAMP" 14 "CSM_FAULT_TIMEOUT_NO_RAMP" 10 "CSM_FAULT_TIMEOUT_RELEASE_INRUSH" 21 "CSM_FAULT_REMOTE_MIA" 20 "CSM_FAULT_NVM_MISMATCH" 6 "CSM_FAULT_RELEASE_BLOCKED" 7 "CSM_FAULT_TIMEOUT_APPLY_COMPLETE" ;
VAL_ 1480 EPBL_a183_nextState 11 "ESM_PARK_PENDING" 1 "ESM_PARK" 3 "ESM_OPEN" 5 "ESM_SUMMON" 0 "ESM_INIT" 6 "ESM_WINCHMODE" 13 "ESM_SUMMON_PARK" 18 "ESM_DYNAMIC_EXTERNAL_EXIT" 19 "ESM_UNKNOWN" 12 "ESM_WINCHMODE_PENDING" 8 "ESM_DIAGNOSTIC_PARK" 16 "ESM_LATCHED_DYNAMIC_EXTERNAL" 2 "ESM_REAPPLY" 9 "ESM_DIAGNOSTIC_OPEN" 14 "ESM_DYNAMIC_EXTERNAL" 10 "ESM_DYNAMIC_PARK" 17 "ESM_SERVICE_PENDING" 15 "ESM_DYNAMIC_PENDING" 7 "ESM_SERVICE" 4 "ESM_DYNAMIC" ;
VAL_ 1480 EPBL_a247_csmFaultReason 5 "CSM_FAULT_APPLY_BLOCKED" 19 "CSM_FAULT_EPBM_MIA" 1 "CSM_FAULT_EPBM_DISABLED" 16 "CSM_FAULT_MOTOR_IDLE_FAULT" 8 "CSM_FAULT_TIMEOUT_APPLY_INRUSH" 3 "CSM_FAULT_STATE_MISMATCH" 13 "CSM_FAULT_TIMEOUT_EPBM_CUTOFF" 15 "CSM_FAULT_TIMEOUT_EPBM_START" 2 "CSM_FAULT_EPBM_FAULTED" 4 "CSM_FAULT_TIMEOUT_CALIBRATE" 12 "CSM_FAULT_TIMEOUT_RELEASE_COMPLETE" 17 "CSM_FAULT_MOTOR_ACTIVE_FAULT" 18 "CSM_FAULT_MOTOR_NOT_READY" 11 "CSM_FAULT_TIMEOUT_RELEASE_WAIT_FOR_ENDSTOP" 0 "CSM_FAULT_NONE" 9 "CSM_FAULT_TIMEOUT_WAIT_FOR_CLAMP" 14 "CSM_FAULT_TIMEOUT_NO_RAMP" 10 "CSM_FAULT_TIMEOUT_RELEASE_INRUSH" 21 "CSM_FAULT_REMOTE_MIA" 20 "CSM_FAULT_NVM_MISMATCH" 6 "CSM_FAULT_RELEASE_BLOCKED" 7 "CSM_FAULT_TIMEOUT_APPLY_COMPLETE" ;
VAL_ 1480 EPBL_a175_csmFaultReason 5 "CSM_FAULT_APPLY_BLOCKED" 19 "CSM_FAULT_EPBM_MIA" 1 "CSM_FAULT_EPBM_DISABLED" 16 "CSM_FAULT_MOTOR_IDLE_FAULT" 8 "CSM_FAULT_TIMEOUT_APPLY_INRUSH" 3 "CSM_FAULT_STATE_MISMATCH" 13 "CSM_FAULT_TIMEOUT_EPBM_CUTOFF" 15 "CSM_FAULT_TIMEOUT_EPBM_START" 2 "CSM_FAULT_EPBM_FAULTED" 4 "CSM_FAULT_TIMEOUT_CALIBRATE" 12 "CSM_FAULT_TIMEOUT_RELEASE_COMPLETE" 17 "CSM_FAULT_MOTOR_ACTIVE_FAULT" 18 "CSM_FAULT_MOTOR_NOT_READY" 11 "CSM_FAULT_TIMEOUT_RELEASE_WAIT_FOR_ENDSTOP" 0 "CSM_FAULT_NONE" 9 "CSM_FAULT_TIMEOUT_WAIT_FOR_CLAMP" 14 "CSM_FAULT_TIMEOUT_NO_RAMP" 10 "CSM_FAULT_TIMEOUT_RELEASE_INRUSH" 21 "CSM_FAULT_REMOTE_MIA" 20 "CSM_FAULT_NVM_MISMATCH" 6 "CSM_FAULT_RELEASE_BLOCKED" 7 "CSM_FAULT_TIMEOUT_APPLY_COMPLETE" ;
VAL_ 1480 EPBL_a189_nextState 11 "ESM_PARK_PENDING" 1 "ESM_PARK" 3 "ESM_OPEN" 5 "ESM_SUMMON" 0 "ESM_INIT" 6 "ESM_WINCHMODE" 13 "ESM_SUMMON_PARK" 18 "ESM_DYNAMIC_EXTERNAL_EXIT" 19 "ESM_UNKNOWN" 12 "ESM_WINCHMODE_PENDING" 8 "ESM_DIAGNOSTIC_PARK" 16 "ESM_LATCHED_DYNAMIC_EXTERNAL" 2 "ESM_REAPPLY" 9 "ESM_DIAGNOSTIC_OPEN" 14 "ESM_DYNAMIC_EXTERNAL" 10 "ESM_DYNAMIC_PARK" 17 "ESM_SERVICE_PENDING" 15 "ESM_DYNAMIC_PENDING" 7 "ESM_SERVICE" 4 "ESM_DYNAMIC" ;
VAL_ 1480 EPBL_a184_nextState 11 "ESM_PARK_PENDING" 1 "ESM_PARK" 3 "ESM_OPEN" 5 "ESM_SUMMON" 0 "ESM_INIT" 6 "ESM_WINCHMODE" 13 "ESM_SUMMON_PARK" 18 "ESM_DYNAMIC_EXTERNAL_EXIT" 19 "ESM_UNKNOWN" 12 "ESM_WINCHMODE_PENDING" 8 "ESM_DIAGNOSTIC_PARK" 16 "ESM_LATCHED_DYNAMIC_EXTERNAL" 2 "ESM_REAPPLY" 9 "ESM_DIAGNOSTIC_OPEN" 14 "ESM_DYNAMIC_EXTERNAL" 10 "ESM_DYNAMIC_PARK" 17 "ESM_SERVICE_PENDING" 15 "ESM_DYNAMIC_PENDING" 7 "ESM_SERVICE" 4 "ESM_DYNAMIC" ;
VAL_ 1480 EPBL_a248_csmFaultReason 5 "CSM_FAULT_APPLY_BLOCKED" 19 "CSM_FAULT_EPBM_MIA" 1 "CSM_FAULT_EPBM_DISABLED" 16 "CSM_FAULT_MOTOR_IDLE_FAULT" 8 "CSM_FAULT_TIMEOUT_APPLY_INRUSH" 3 "CSM_FAULT_STATE_MISMATCH" 13 "CSM_FAULT_TIMEOUT_EPBM_CUTOFF" 15 "CSM_FAULT_TIMEOUT_EPBM_START" 2 "CSM_FAULT_EPBM_FAULTED" 4 "CSM_FAULT_TIMEOUT_CALIBRATE" 12 "CSM_FAULT_TIMEOUT_RELEASE_COMPLETE" 17 "CSM_FAULT_MOTOR_ACTIVE_FAULT" 18 "CSM_FAULT_MOTOR_NOT_READY" 11 "CSM_FAULT_TIMEOUT_RELEASE_WAIT_FOR_ENDSTOP" 0 "CSM_FAULT_NONE" 9 "CSM_FAULT_TIMEOUT_WAIT_FOR_CLAMP" 14 "CSM_FAULT_TIMEOUT_NO_RAMP" 10 "CSM_FAULT_TIMEOUT_RELEASE_INRUSH" 21 "CSM_FAULT_REMOTE_MIA" 20 "CSM_FAULT_NVM_MISMATCH" 6 "CSM_FAULT_RELEASE_BLOCKED" 7 "CSM_FAULT_TIMEOUT_APPLY_COMPLETE" ;
VAL_ 1480 EPBL_a249_esmOpTrigger 20 "EPB_TRIGGER_TIMEOUT" 2 "EPB_TRIGGER_PBUTTON_PRESSED_FAST" 19 "EPB_TRIGGER_SPEED_FAST" 3 "EPB_TRIGGER_PBUTTON_PRESSED_UNKNOWN" 27 "EPB_TRIGGER_EPBM_DISQUALIFIED" 10 "EPB_TRIGGER_WINCHMODE_UNAVAILABLE" 28 "EPB_TRIGGER_ACCELERATION" 12 "EPB_TRIGGER_DIAG_CLOSE" 24 "EPB_TRIGGER_FAULT" 25 "EPB_TRIGGER_SUMMON_FAULT" 30 "EPB_TRIGGER_DRIVER_IS_LEAVING" 18 "EPB_TRIGGER_SPEED_OKAYTOPARK" 1 "EPB_TRIGGER_PBUTTON_PRESSED_OKTOPARK" 4 "EPB_TRIGGER_PBUTTON_RELEASED" 14 "EPB_TRIGGER_DIAG_EXIT" 21 "EPB_TRIGGER_SAVESTATE_ON_BOOT" 6 "EPB_TRIGGER_DI_UNPARK" 23 "EPB_TRIGGER_SUMMON_COMPLETE" 22 "EPB_TRIGGER_REAPPLY" 26 "EPB_TRIGGER_DISQUALIFIED" 16 "EPB_TRIGGER_USER_CANCEL" 13 "EPB_TRIGGER_DIAG_OPEN" 11 "EPB_TRIGGER_SERVICE" 5 "EPB_TRIGGER_ACTIVE_PARK_REQUEST" 15 "EPB_TRIGGER_USER_CONFIRMED" 8 "EPB_TRIGGER_WINCHMODE_EXIT" 9 "EPB_TRIGGER_WINCHMODE_ENTER" 17 "EPB_TRIGGER_SPEED_STOPPED" 0 "EPB_TRIGGER_PBUTTON_PRESSED_STOPPED" 7 "EPB_TRIGGER_TOUCHSCREEN" 29 "EPB_TRIGGER_SYSTEM_APPLY" ;
VAL_ 1480 EPBL_a190_csmFaultReason 5 "CSM_FAULT_APPLY_BLOCKED" 19 "CSM_FAULT_EPBM_MIA" 1 "CSM_FAULT_EPBM_DISABLED" 16 "CSM_FAULT_MOTOR_IDLE_FAULT" 8 "CSM_FAULT_TIMEOUT_APPLY_INRUSH" 3 "CSM_FAULT_STATE_MISMATCH" 13 "CSM_FAULT_TIMEOUT_EPBM_CUTOFF" 15 "CSM_FAULT_TIMEOUT_EPBM_START" 2 "CSM_FAULT_EPBM_FAULTED" 4 "CSM_FAULT_TIMEOUT_CALIBRATE" 12 "CSM_FAULT_TIMEOUT_RELEASE_COMPLETE" 17 "CSM_FAULT_MOTOR_ACTIVE_FAULT" 18 "CSM_FAULT_MOTOR_NOT_READY" 11 "CSM_FAULT_TIMEOUT_RELEASE_WAIT_FOR_ENDSTOP" 0 "CSM_FAULT_NONE" 9 "CSM_FAULT_TIMEOUT_WAIT_FOR_CLAMP" 14 "CSM_FAULT_TIMEOUT_NO_RAMP" 10 "CSM_FAULT_TIMEOUT_RELEASE_INRUSH" 21 "CSM_FAULT_REMOTE_MIA" 20 "CSM_FAULT_NVM_MISMATCH" 6 "CSM_FAULT_RELEASE_BLOCKED" 7 "CSM_FAULT_TIMEOUT_APPLY_COMPLETE" ;
VAL_ 1480 EPBL_a179_csmFaultReason 5 "CSM_FAULT_APPLY_BLOCKED" 19 "CSM_FAULT_EPBM_MIA" 1 "CSM_FAULT_EPBM_DISABLED" 16 "CSM_FAULT_MOTOR_IDLE_FAULT" 8 "CSM_FAULT_TIMEOUT_APPLY_INRUSH" 3 "CSM_FAULT_STATE_MISMATCH" 13 "CSM_FAULT_TIMEOUT_EPBM_CUTOFF" 15 "CSM_FAULT_TIMEOUT_EPBM_START" 2 "CSM_FAULT_EPBM_FAULTED" 4 "CSM_FAULT_TIMEOUT_CALIBRATE" 12 "CSM_FAULT_TIMEOUT_RELEASE_COMPLETE" 17 "CSM_FAULT_MOTOR_ACTIVE_FAULT" 18 "CSM_FAULT_MOTOR_NOT_READY" 11 "CSM_FAULT_TIMEOUT_RELEASE_WAIT_FOR_ENDSTOP" 0 "CSM_FAULT_NONE" 9 "CSM_FAULT_TIMEOUT_WAIT_FOR_CLAMP" 14 "CSM_FAULT_TIMEOUT_NO_RAMP" 10 "CSM_FAULT_TIMEOUT_RELEASE_INRUSH" 21 "CSM_FAULT_REMOTE_MIA" 20 "CSM_FAULT_NVM_MISMATCH" 6 "CSM_FAULT_RELEASE_BLOCKED" 7 "CSM_FAULT_TIMEOUT_APPLY_COMPLETE" ;
VAL_ 1480 EPBL_a174_csmFaultReason 5 "CSM_FAULT_APPLY_BLOCKED" 19 "CSM_FAULT_EPBM_MIA" 1 "CSM_FAULT_EPBM_DISABLED" 16 "CSM_FAULT_MOTOR_IDLE_FAULT" 8 "CSM_FAULT_TIMEOUT_APPLY_INRUSH" 3 "CSM_FAULT_STATE_MISMATCH" 13 "CSM_FAULT_TIMEOUT_EPBM_CUTOFF" 15 "CSM_FAULT_TIMEOUT_EPBM_START" 2 "CSM_FAULT_EPBM_FAULTED" 4 "CSM_FAULT_TIMEOUT_CALIBRATE" 12 "CSM_FAULT_TIMEOUT_RELEASE_COMPLETE" 17 "CSM_FAULT_MOTOR_ACTIVE_FAULT" 18 "CSM_FAULT_MOTOR_NOT_READY" 11 "CSM_FAULT_TIMEOUT_RELEASE_WAIT_FOR_ENDSTOP" 0 "CSM_FAULT_NONE" 9 "CSM_FAULT_TIMEOUT_WAIT_FOR_CLAMP" 14 "CSM_FAULT_TIMEOUT_NO_RAMP" 10 "CSM_FAULT_TIMEOUT_RELEASE_INRUSH" 21 "CSM_FAULT_REMOTE_MIA" 20 "CSM_FAULT_NVM_MISMATCH" 6 "CSM_FAULT_RELEASE_BLOCKED" 7 "CSM_FAULT_TIMEOUT_APPLY_COMPLETE" ;
VAL_ 1480 EPBL_a180_nextState 11 "ESM_PARK_PENDING" 1 "ESM_PARK" 3 "ESM_OPEN" 5 "ESM_SUMMON" 0 "ESM_INIT" 6 "ESM_WINCHMODE" 13 "ESM_SUMMON_PARK" 18 "ESM_DYNAMIC_EXTERNAL_EXIT" 19 "ESM_UNKNOWN" 12 "ESM_WINCHMODE_PENDING" 8 "ESM_DIAGNOSTIC_PARK" 16 "ESM_LATCHED_DYNAMIC_EXTERNAL" 2 "ESM_REAPPLY" 9 "ESM_DIAGNOSTIC_OPEN" 14 "ESM_DYNAMIC_EXTERNAL" 10 "ESM_DYNAMIC_PARK" 17 "ESM_SERVICE_PENDING" 15 "ESM_DYNAMIC_PENDING" 7 "ESM_SERVICE" 4 "ESM_DYNAMIC" ;
VAL_ 1480 EPBL_a177_csmFaultReason 5 "CSM_FAULT_APPLY_BLOCKED" 19 "CSM_FAULT_EPBM_MIA" 1 "CSM_FAULT_EPBM_DISABLED" 16 "CSM_FAULT_MOTOR_IDLE_FAULT" 8 "CSM_FAULT_TIMEOUT_APPLY_INRUSH" 3 "CSM_FAULT_STATE_MISMATCH" 13 "CSM_FAULT_TIMEOUT_EPBM_CUTOFF" 15 "CSM_FAULT_TIMEOUT_EPBM_START" 2 "CSM_FAULT_EPBM_FAULTED" 4 "CSM_FAULT_TIMEOUT_CALIBRATE" 12 "CSM_FAULT_TIMEOUT_RELEASE_COMPLETE" 17 "CSM_FAULT_MOTOR_ACTIVE_FAULT" 18 "CSM_FAULT_MOTOR_NOT_READY" 11 "CSM_FAULT_TIMEOUT_RELEASE_WAIT_FOR_ENDSTOP" 0 "CSM_FAULT_NONE" 9 "CSM_FAULT_TIMEOUT_WAIT_FOR_CLAMP" 14 "CSM_FAULT_TIMEOUT_NO_RAMP" 10 "CSM_FAULT_TIMEOUT_RELEASE_INRUSH" 21 "CSM_FAULT_REMOTE_MIA" 20 "CSM_FAULT_NVM_MISMATCH" 6 "CSM_FAULT_RELEASE_BLOCKED" 7 "CSM_FAULT_TIMEOUT_APPLY_COMPLETE" ;
VAL_ 1480 EPBL_a186_nextState 11 "ESM_PARK_PENDING" 1 "ESM_PARK" 3 "ESM_OPEN" 5 "ESM_SUMMON" 0 "ESM_INIT" 6 "ESM_WINCHMODE" 13 "ESM_SUMMON_PARK" 18 "ESM_DYNAMIC_EXTERNAL_EXIT" 19 "ESM_UNKNOWN" 12 "ESM_WINCHMODE_PENDING" 8 "ESM_DIAGNOSTIC_PARK" 16 "ESM_LATCHED_DYNAMIC_EXTERNAL" 2 "ESM_REAPPLY" 9 "ESM_DIAGNOSTIC_OPEN" 14 "ESM_DYNAMIC_EXTERNAL" 10 "ESM_DYNAMIC_PARK" 17 "ESM_SERVICE_PENDING" 15 "ESM_DYNAMIC_PENDING" 7 "ESM_SERVICE" 4 "ESM_DYNAMIC" ;
VAL_ 1480 EPBL_a187_nextState 11 "ESM_PARK_PENDING" 1 "ESM_PARK" 3 "ESM_OPEN" 5 "ESM_SUMMON" 0 "ESM_INIT" 6 "ESM_WINCHMODE" 13 "ESM_SUMMON_PARK" 18 "ESM_DYNAMIC_EXTERNAL_EXIT" 19 "ESM_UNKNOWN" 12 "ESM_WINCHMODE_PENDING" 8 "ESM_DIAGNOSTIC_PARK" 16 "ESM_LATCHED_DYNAMIC_EXTERNAL" 2 "ESM_REAPPLY" 9 "ESM_DIAGNOSTIC_OPEN" 14 "ESM_DYNAMIC_EXTERNAL" 10 "ESM_DYNAMIC_PARK" 17 "ESM_SERVICE_PENDING" 15 "ESM_DYNAMIC_PENDING" 7 "ESM_SERVICE" 4 "ESM_DYNAMIC" ;
VAL_ 1480 EPBL_a247_monitorFaultStatus 1 "EPB_STATUS_RETRY" 3 "EPB_STATUS_FAULT_IDLE" 0 "EPB_STATUS_NOMINAL" 2 "EPB_STATUS_FAULT" ;
VAL_ 1480 EPBL_a191_monitorFaultStatus 1 "EPB_STATUS_RETRY" 3 "EPB_STATUS_FAULT_IDLE" 0 "EPB_STATUS_NOMINAL" 2 "EPB_STATUS_FAULT" ;
VAL_ 1480 EPBL_a175_monitorFaultStatus 1 "EPB_STATUS_RETRY" 3 "EPB_STATUS_FAULT_IDLE" 0 "EPB_STATUS_NOMINAL" 2 "EPB_STATUS_FAULT" ;
VAL_ 1480 EPBL_a176_monitorFaultStatus 1 "EPB_STATUS_RETRY" 3 "EPB_STATUS_FAULT_IDLE" 0 "EPB_STATUS_NOMINAL" 2 "EPB_STATUS_FAULT" ;
VAL_ 1480 EPBL_a179_monitorFaultStatus 1 "EPB_STATUS_RETRY" 3 "EPB_STATUS_FAULT_IDLE" 0 "EPB_STATUS_NOMINAL" 2 "EPB_STATUS_FAULT" ;
VAL_ 1480 EPBL_a246_faultStatus 1 "EPB_STATUS_RETRY" 3 "EPB_STATUS_FAULT_IDLE" 0 "EPB_STATUS_NOMINAL" 2 "EPB_STATUS_FAULT" ;
VAL_ 1480 EPBL_a177_monitorFaultStatus 1 "EPB_STATUS_RETRY" 3 "EPB_STATUS_FAULT_IDLE" 0 "EPB_STATUS_NOMINAL" 2 "EPB_STATUS_FAULT" ;
VAL_ 1480 EPBL_a248_monitorFaultStatus 1 "EPB_STATUS_RETRY" 3 "EPB_STATUS_FAULT_IDLE" 0 "EPB_STATUS_NOMINAL" 2 "EPB_STATUS_FAULT" ;
VAL_ 1480 EPBL_a249_faultStatus 1 "EPB_STATUS_RETRY" 3 "EPB_STATUS_FAULT_IDLE" 0 "EPB_STATUS_NOMINAL" 2 "EPB_STATUS_FAULT" ;
VAL_ 1480 EPBL_a190_monitorFaultStatus 1 "EPB_STATUS_RETRY" 3 "EPB_STATUS_FAULT_IDLE" 0 "EPB_STATUS_NOMINAL" 2 "EPB_STATUS_FAULT" ;
VAL_ 1480 EPBL_a174_monitorFaultStatus 1 "EPB_STATUS_RETRY" 3 "EPB_STATUS_FAULT_IDLE" 0 "EPB_STATUS_NOMINAL" 2 "EPB_STATUS_FAULT" ;
VAL_ 1480 EPBL_a183_previousState 11 "ESM_PARK_PENDING" 1 "ESM_PARK" 3 "ESM_OPEN" 5 "ESM_SUMMON" 0 "ESM_INIT" 6 "ESM_WINCHMODE" 13 "ESM_SUMMON_PARK" 18 "ESM_DYNAMIC_EXTERNAL_EXIT" 19 "ESM_UNKNOWN" 12 "ESM_WINCHMODE_PENDING" 8 "ESM_DIAGNOSTIC_PARK" 16 "ESM_LATCHED_DYNAMIC_EXTERNAL" 2 "ESM_REAPPLY" 9 "ESM_DIAGNOSTIC_OPEN" 14 "ESM_DYNAMIC_EXTERNAL" 10 "ESM_DYNAMIC_PARK" 17 "ESM_SERVICE_PENDING" 15 "ESM_DYNAMIC_PENDING" 7 "ESM_SERVICE" 4 "ESM_DYNAMIC" ;
VAL_ 1480 EPBL_a186_previousState 11 "ESM_PARK_PENDING" 1 "ESM_PARK" 3 "ESM_OPEN" 5 "ESM_SUMMON" 0 "ESM_INIT" 6 "ESM_WINCHMODE" 13 "ESM_SUMMON_PARK" 18 "ESM_DYNAMIC_EXTERNAL_EXIT" 19 "ESM_UNKNOWN" 12 "ESM_WINCHMODE_PENDING" 8 "ESM_DIAGNOSTIC_PARK" 16 "ESM_LATCHED_DYNAMIC_EXTERNAL" 2 "ESM_REAPPLY" 9 "ESM_DIAGNOSTIC_OPEN" 14 "ESM_DYNAMIC_EXTERNAL" 10 "ESM_DYNAMIC_PARK" 17 "ESM_SERVICE_PENDING" 15 "ESM_DYNAMIC_PENDING" 7 "ESM_SERVICE" 4 "ESM_DYNAMIC" ;
VAL_ 1480 EPBL_a179_monitorUnitStatus 14 "EPB_STATUS_SUMMON" 1 "EPB_STATUS_OPEN" 9 "EPB_STATUS_DYNAMIC_APPLYING" 21 "EPB_STATUS_COUNT" 12 "EPB_STATUS_PARK_PENDING" 13 "EPB_STATUS_WINCHMODE_PENDING" 6 "EPB_STATUS_WINCHMODE" 3 "EPB_STATUS_PARK" 0 "EPB_STATUS_UNKNOWN" 4 "EPB_STATUS_START" 18 "EPB_STATUS_RELEASING_FOR_EXTERNAL_PARK" 19 "EPB_STATUS_EXTERNAL_PARKING" 17 "EPB_STATUS_EXTERNAL_DYNAMIC" 10 "EPB_STATUS_RELEASING" 15 "EPB_STATUS_SUMMON_RELEASING" 11 "EPB_STATUS_SERVICE_RELEASING" 7 "EPB_STATUS_WINCHMODE_RELEASING" 16 "EPB_STATUS_SUMMON_PARKING" 8 "EPB_STATUS_PARKING" 2 "EPB_STATUS_DYNAMIC" 5 "EPB_STATUS_SERVICE" 20 "EPB_STATUS_DYNAMIC_PARKING" ;
VAL_ 1480 EPBL_a191_monitorUnitStatus 14 "EPB_STATUS_SUMMON" 1 "EPB_STATUS_OPEN" 9 "EPB_STATUS_DYNAMIC_APPLYING" 21 "EPB_STATUS_COUNT" 12 "EPB_STATUS_PARK_PENDING" 13 "EPB_STATUS_WINCHMODE_PENDING" 6 "EPB_STATUS_WINCHMODE" 3 "EPB_STATUS_PARK" 0 "EPB_STATUS_UNKNOWN" 4 "EPB_STATUS_START" 18 "EPB_STATUS_RELEASING_FOR_EXTERNAL_PARK" 19 "EPB_STATUS_EXTERNAL_PARKING" 17 "EPB_STATUS_EXTERNAL_DYNAMIC" 10 "EPB_STATUS_RELEASING" 15 "EPB_STATUS_SUMMON_RELEASING" 11 "EPB_STATUS_SERVICE_RELEASING" 7 "EPB_STATUS_WINCHMODE_RELEASING" 16 "EPB_STATUS_SUMMON_PARKING" 8 "EPB_STATUS_PARKING" 2 "EPB_STATUS_DYNAMIC" 5 "EPB_STATUS_SERVICE" 20 "EPB_STATUS_DYNAMIC_PARKING" ;
VAL_ 1480 EPBL_a247_monitorUnitStatus 14 "EPB_STATUS_SUMMON" 1 "EPB_STATUS_OPEN" 9 "EPB_STATUS_DYNAMIC_APPLYING" 21 "EPB_STATUS_COUNT" 12 "EPB_STATUS_PARK_PENDING" 13 "EPB_STATUS_WINCHMODE_PENDING" 6 "EPB_STATUS_WINCHMODE" 3 "EPB_STATUS_PARK" 0 "EPB_STATUS_UNKNOWN" 4 "EPB_STATUS_START" 18 "EPB_STATUS_RELEASING_FOR_EXTERNAL_PARK" 19 "EPB_STATUS_EXTERNAL_PARKING" 17 "EPB_STATUS_EXTERNAL_DYNAMIC" 10 "EPB_STATUS_RELEASING" 15 "EPB_STATUS_SUMMON_RELEASING" 11 "EPB_STATUS_SERVICE_RELEASING" 7 "EPB_STATUS_WINCHMODE_RELEASING" 16 "EPB_STATUS_SUMMON_PARKING" 8 "EPB_STATUS_PARKING" 2 "EPB_STATUS_DYNAMIC" 5 "EPB_STATUS_SERVICE" 20 "EPB_STATUS_DYNAMIC_PARKING" ;
VAL_ 1480 EPBL_a180_previousState 11 "ESM_PARK_PENDING" 1 "ESM_PARK" 3 "ESM_OPEN" 5 "ESM_SUMMON" 0 "ESM_INIT" 6 "ESM_WINCHMODE" 13 "ESM_SUMMON_PARK" 18 "ESM_DYNAMIC_EXTERNAL_EXIT" 19 "ESM_UNKNOWN" 12 "ESM_WINCHMODE_PENDING" 8 "ESM_DIAGNOSTIC_PARK" 16 "ESM_LATCHED_DYNAMIC_EXTERNAL" 2 "ESM_REAPPLY" 9 "ESM_DIAGNOSTIC_OPEN" 14 "ESM_DYNAMIC_EXTERNAL" 10 "ESM_DYNAMIC_PARK" 17 "ESM_SERVICE_PENDING" 15 "ESM_DYNAMIC_PENDING" 7 "ESM_SERVICE" 4 "ESM_DYNAMIC" ;
VAL_ 1480 EPBL_a173_csmState 8 "CSM_WAIT_FOR_ENDSTOP" 9 "CSM_RELEASE_COMPLETE" 12 "CSM_FAULT" 5 "CSM_APPLY_COMPLETE" 7 "CSM_RELEASE_NOLOAD" 14 "CSM_HOLD_CLAMP" 4 "CSM_WAIT_FOR_CLAMP" 6 "CSM_RELEASE_INRUSH" 13 "CSM_STATIONARY_FAULT" 2 "CSM_APPLY_INRUSH" 10 "CSM_CALIBRATE" 1 "CSM_STANDBY" 0 "CSM_INIT" 11 "CSM_HALT" 3 "CSM_APPLY_NOLOAD" ;
VAL_ 1480 EPBL_a187_previousState 11 "ESM_PARK_PENDING" 1 "ESM_PARK" 3 "ESM_OPEN" 5 "ESM_SUMMON" 0 "ESM_INIT" 6 "ESM_WINCHMODE" 13 "ESM_SUMMON_PARK" 18 "ESM_DYNAMIC_EXTERNAL_EXIT" 19 "ESM_UNKNOWN" 12 "ESM_WINCHMODE_PENDING" 8 "ESM_DIAGNOSTIC_PARK" 16 "ESM_LATCHED_DYNAMIC_EXTERNAL" 2 "ESM_REAPPLY" 9 "ESM_DIAGNOSTIC_OPEN" 14 "ESM_DYNAMIC_EXTERNAL" 10 "ESM_DYNAMIC_PARK" 17 "ESM_SERVICE_PENDING" 15 "ESM_DYNAMIC_PENDING" 7 "ESM_SERVICE" 4 "ESM_DYNAMIC" ;
VAL_ 1480 EPBL_a246_esmStateRequest 11 "ESM_PARK_PENDING" 1 "ESM_PARK" 3 "ESM_OPEN" 5 "ESM_SUMMON" 0 "ESM_INIT" 6 "ESM_WINCHMODE" 13 "ESM_SUMMON_PARK" 18 "ESM_DYNAMIC_EXTERNAL_EXIT" 19 "ESM_UNKNOWN" 12 "ESM_WINCHMODE_PENDING" 8 "ESM_DIAGNOSTIC_PARK" 16 "ESM_LATCHED_DYNAMIC_EXTERNAL" 2 "ESM_REAPPLY" 9 "ESM_DIAGNOSTIC_OPEN" 14 "ESM_DYNAMIC_EXTERNAL" 10 "ESM_DYNAMIC_PARK" 17 "ESM_SERVICE_PENDING" 15 "ESM_DYNAMIC_PENDING" 7 "ESM_SERVICE" 4 "ESM_DYNAMIC" ;
VAL_ 1480 EPBL_a175_monitorUnitStatus 14 "EPB_STATUS_SUMMON" 1 "EPB_STATUS_OPEN" 9 "EPB_STATUS_DYNAMIC_APPLYING" 21 "EPB_STATUS_COUNT" 12 "EPB_STATUS_PARK_PENDING" 13 "EPB_STATUS_WINCHMODE_PENDING" 6 "EPB_STATUS_WINCHMODE" 3 "EPB_STATUS_PARK" 0 "EPB_STATUS_UNKNOWN" 4 "EPB_STATUS_START" 18 "EPB_STATUS_RELEASING_FOR_EXTERNAL_PARK" 19 "EPB_STATUS_EXTERNAL_PARKING" 17 "EPB_STATUS_EXTERNAL_DYNAMIC" 10 "EPB_STATUS_RELEASING" 15 "EPB_STATUS_SUMMON_RELEASING" 11 "EPB_STATUS_SERVICE_RELEASING" 7 "EPB_STATUS_WINCHMODE_RELEASING" 16 "EPB_STATUS_SUMMON_PARKING" 8 "EPB_STATUS_PARKING" 2 "EPB_STATUS_DYNAMIC" 5 "EPB_STATUS_SERVICE" 20 "EPB_STATUS_DYNAMIC_PARKING" ;
VAL_ 1480 EPBL_a190_monitorUnitStatus 14 "EPB_STATUS_SUMMON" 1 "EPB_STATUS_OPEN" 9 "EPB_STATUS_DYNAMIC_APPLYING" 21 "EPB_STATUS_COUNT" 12 "EPB_STATUS_PARK_PENDING" 13 "EPB_STATUS_WINCHMODE_PENDING" 6 "EPB_STATUS_WINCHMODE" 3 "EPB_STATUS_PARK" 0 "EPB_STATUS_UNKNOWN" 4 "EPB_STATUS_START" 18 "EPB_STATUS_RELEASING_FOR_EXTERNAL_PARK" 19 "EPB_STATUS_EXTERNAL_PARKING" 17 "EPB_STATUS_EXTERNAL_DYNAMIC" 10 "EPB_STATUS_RELEASING" 15 "EPB_STATUS_SUMMON_RELEASING" 11 "EPB_STATUS_SERVICE_RELEASING" 7 "EPB_STATUS_WINCHMODE_RELEASING" 16 "EPB_STATUS_SUMMON_PARKING" 8 "EPB_STATUS_PARKING" 2 "EPB_STATUS_DYNAMIC" 5 "EPB_STATUS_SERVICE" 20 "EPB_STATUS_DYNAMIC_PARKING" ;
VAL_ 1480 EPBL_a184_previousState 11 "ESM_PARK_PENDING" 1 "ESM_PARK" 3 "ESM_OPEN" 5 "ESM_SUMMON" 0 "ESM_INIT" 6 "ESM_WINCHMODE" 13 "ESM_SUMMON_PARK" 18 "ESM_DYNAMIC_EXTERNAL_EXIT" 19 "ESM_UNKNOWN" 12 "ESM_WINCHMODE_PENDING" 8 "ESM_DIAGNOSTIC_PARK" 16 "ESM_LATCHED_DYNAMIC_EXTERNAL" 2 "ESM_REAPPLY" 9 "ESM_DIAGNOSTIC_OPEN" 14 "ESM_DYNAMIC_EXTERNAL" 10 "ESM_DYNAMIC_PARK" 17 "ESM_SERVICE_PENDING" 15 "ESM_DYNAMIC_PENDING" 7 "ESM_SERVICE" 4 "ESM_DYNAMIC" ;
VAL_ 1480 EPBL_a174_monitorUnitStatus 14 "EPB_STATUS_SUMMON" 1 "EPB_STATUS_OPEN" 9 "EPB_STATUS_DYNAMIC_APPLYING" 21 "EPB_STATUS_COUNT" 12 "EPB_STATUS_PARK_PENDING" 13 "EPB_STATUS_WINCHMODE_PENDING" 6 "EPB_STATUS_WINCHMODE" 3 "EPB_STATUS_PARK" 0 "EPB_STATUS_UNKNOWN" 4 "EPB_STATUS_START" 18 "EPB_STATUS_RELEASING_FOR_EXTERNAL_PARK" 19 "EPB_STATUS_EXTERNAL_PARKING" 17 "EPB_STATUS_EXTERNAL_DYNAMIC" 10 "EPB_STATUS_RELEASING" 15 "EPB_STATUS_SUMMON_RELEASING" 11 "EPB_STATUS_SERVICE_RELEASING" 7 "EPB_STATUS_WINCHMODE_RELEASING" 16 "EPB_STATUS_SUMMON_PARKING" 8 "EPB_STATUS_PARKING" 2 "EPB_STATUS_DYNAMIC" 5 "EPB_STATUS_SERVICE" 20 "EPB_STATUS_DYNAMIC_PARKING" ;
VAL_ 1480 EPBL_a249_esmStateRequest 11 "ESM_PARK_PENDING" 1 "ESM_PARK" 3 "ESM_OPEN" 5 "ESM_SUMMON" 0 "ESM_INIT" 6 "ESM_WINCHMODE" 13 "ESM_SUMMON_PARK" 18 "ESM_DYNAMIC_EXTERNAL_EXIT" 19 "ESM_UNKNOWN" 12 "ESM_WINCHMODE_PENDING" 8 "ESM_DIAGNOSTIC_PARK" 16 "ESM_LATCHED_DYNAMIC_EXTERNAL" 2 "ESM_REAPPLY" 9 "ESM_DIAGNOSTIC_OPEN" 14 "ESM_DYNAMIC_EXTERNAL" 10 "ESM_DYNAMIC_PARK" 17 "ESM_SERVICE_PENDING" 15 "ESM_DYNAMIC_PENDING" 7 "ESM_SERVICE" 4 "ESM_DYNAMIC" ;
VAL_ 1480 EPBL_a188_previousState 11 "ESM_PARK_PENDING" 1 "ESM_PARK" 3 "ESM_OPEN" 5 "ESM_SUMMON" 0 "ESM_INIT" 6 "ESM_WINCHMODE" 13 "ESM_SUMMON_PARK" 18 "ESM_DYNAMIC_EXTERNAL_EXIT" 19 "ESM_UNKNOWN" 12 "ESM_WINCHMODE_PENDING" 8 "ESM_DIAGNOSTIC_PARK" 16 "ESM_LATCHED_DYNAMIC_EXTERNAL" 2 "ESM_REAPPLY" 9 "ESM_DIAGNOSTIC_OPEN" 14 "ESM_DYNAMIC_EXTERNAL" 10 "ESM_DYNAMIC_PARK" 17 "ESM_SERVICE_PENDING" 15 "ESM_DYNAMIC_PENDING" 7 "ESM_SERVICE" 4 "ESM_DYNAMIC" ;
VAL_ 1480 EPBL_a177_monitorUnitStatus 14 "EPB_STATUS_SUMMON" 1 "EPB_STATUS_OPEN" 9 "EPB_STATUS_DYNAMIC_APPLYING" 21 "EPB_STATUS_COUNT" 12 "EPB_STATUS_PARK_PENDING" 13 "EPB_STATUS_WINCHMODE_PENDING" 6 "EPB_STATUS_WINCHMODE" 3 "EPB_STATUS_PARK" 0 "EPB_STATUS_UNKNOWN" 4 "EPB_STATUS_START" 18 "EPB_STATUS_RELEASING_FOR_EXTERNAL_PARK" 19 "EPB_STATUS_EXTERNAL_PARKING" 17 "EPB_STATUS_EXTERNAL_DYNAMIC" 10 "EPB_STATUS_RELEASING" 15 "EPB_STATUS_SUMMON_RELEASING" 11 "EPB_STATUS_SERVICE_RELEASING" 7 "EPB_STATUS_WINCHMODE_RELEASING" 16 "EPB_STATUS_SUMMON_PARKING" 8 "EPB_STATUS_PARKING" 2 "EPB_STATUS_DYNAMIC" 5 "EPB_STATUS_SERVICE" 20 "EPB_STATUS_DYNAMIC_PARKING" ;
VAL_ 1480 EPBL_a248_monitorUnitStatus 14 "EPB_STATUS_SUMMON" 1 "EPB_STATUS_OPEN" 9 "EPB_STATUS_DYNAMIC_APPLYING" 21 "EPB_STATUS_COUNT" 12 "EPB_STATUS_PARK_PENDING" 13 "EPB_STATUS_WINCHMODE_PENDING" 6 "EPB_STATUS_WINCHMODE" 3 "EPB_STATUS_PARK" 0 "EPB_STATUS_UNKNOWN" 4 "EPB_STATUS_START" 18 "EPB_STATUS_RELEASING_FOR_EXTERNAL_PARK" 19 "EPB_STATUS_EXTERNAL_PARKING" 17 "EPB_STATUS_EXTERNAL_DYNAMIC" 10 "EPB_STATUS_RELEASING" 15 "EPB_STATUS_SUMMON_RELEASING" 11 "EPB_STATUS_SERVICE_RELEASING" 7 "EPB_STATUS_WINCHMODE_RELEASING" 16 "EPB_STATUS_SUMMON_PARKING" 8 "EPB_STATUS_PARKING" 2 "EPB_STATUS_DYNAMIC" 5 "EPB_STATUS_SERVICE" 20 "EPB_STATUS_DYNAMIC_PARKING" ;
VAL_ 1480 EPBL_a176_monitorUnitStatus 14 "EPB_STATUS_SUMMON" 1 "EPB_STATUS_OPEN" 9 "EPB_STATUS_DYNAMIC_APPLYING" 21 "EPB_STATUS_COUNT" 12 "EPB_STATUS_PARK_PENDING" 13 "EPB_STATUS_WINCHMODE_PENDING" 6 "EPB_STATUS_WINCHMODE" 3 "EPB_STATUS_PARK" 0 "EPB_STATUS_UNKNOWN" 4 "EPB_STATUS_START" 18 "EPB_STATUS_RELEASING_FOR_EXTERNAL_PARK" 19 "EPB_STATUS_EXTERNAL_PARKING" 17 "EPB_STATUS_EXTERNAL_DYNAMIC" 10 "EPB_STATUS_RELEASING" 15 "EPB_STATUS_SUMMON_RELEASING" 11 "EPB_STATUS_SERVICE_RELEASING" 7 "EPB_STATUS_WINCHMODE_RELEASING" 16 "EPB_STATUS_SUMMON_PARKING" 8 "EPB_STATUS_PARKING" 2 "EPB_STATUS_DYNAMIC" 5 "EPB_STATUS_SERVICE" 20 "EPB_STATUS_DYNAMIC_PARKING" ;
VAL_ 1480 EPBL_a189_previousState 11 "ESM_PARK_PENDING" 1 "ESM_PARK" 3 "ESM_OPEN" 5 "ESM_SUMMON" 0 "ESM_INIT" 6 "ESM_WINCHMODE" 13 "ESM_SUMMON_PARK" 18 "ESM_DYNAMIC_EXTERNAL_EXIT" 19 "ESM_UNKNOWN" 12 "ESM_WINCHMODE_PENDING" 8 "ESM_DIAGNOSTIC_PARK" 16 "ESM_LATCHED_DYNAMIC_EXTERNAL" 2 "ESM_REAPPLY" 9 "ESM_DIAGNOSTIC_OPEN" 14 "ESM_DYNAMIC_EXTERNAL" 10 "ESM_DYNAMIC_PARK" 17 "ESM_SERVICE_PENDING" 15 "ESM_DYNAMIC_PENDING" 7 "ESM_SERVICE" 4 "ESM_DYNAMIC" ;
VAL_ 1480 EPBL_a179_faultStatus 1 "EPB_STATUS_RETRY" 3 "EPB_STATUS_FAULT_IDLE" 0 "EPB_STATUS_NOMINAL" 2 "EPB_STATUS_FAULT" ;
VAL_ 1480 EPBL_a191_faultStatus 1 "EPB_STATUS_RETRY" 3 "EPB_STATUS_FAULT_IDLE" 0 "EPB_STATUS_NOMINAL" 2 "EPB_STATUS_FAULT" ;
VAL_ 1480 EPBL_a247_faultStatus 1 "EPB_STATUS_RETRY" 3 "EPB_STATUS_FAULT_IDLE" 0 "EPB_STATUS_NOMINAL" 2 "EPB_STATUS_FAULT" ;
VAL_ 1480 EPBL_a175_faultStatus 1 "EPB_STATUS_RETRY" 3 "EPB_STATUS_FAULT_IDLE" 0 "EPB_STATUS_NOMINAL" 2 "EPB_STATUS_FAULT" ;
VAL_ 1480 EPBL_a190_faultStatus 1 "EPB_STATUS_RETRY" 3 "EPB_STATUS_FAULT_IDLE" 0 "EPB_STATUS_NOMINAL" 2 "EPB_STATUS_FAULT" ;
VAL_ 1480 EPBL_a174_faultStatus 1 "EPB_STATUS_RETRY" 3 "EPB_STATUS_FAULT_IDLE" 0 "EPB_STATUS_NOMINAL" 2 "EPB_STATUS_FAULT" ;
VAL_ 1480 EPBL_a177_faultStatus 1 "EPB_STATUS_RETRY" 3 "EPB_STATUS_FAULT_IDLE" 0 "EPB_STATUS_NOMINAL" 2 "EPB_STATUS_FAULT" ;
VAL_ 1480 EPBL_a248_faultStatus 1 "EPB_STATUS_RETRY" 3 "EPB_STATUS_FAULT_IDLE" 0 "EPB_STATUS_NOMINAL" 2 "EPB_STATUS_FAULT" ;
VAL_ 1480 EPBL_a176_faultStatus 1 "EPB_STATUS_RETRY" 3 "EPB_STATUS_FAULT_IDLE" 0 "EPB_STATUS_NOMINAL" 2 "EPB_STATUS_FAULT" ;
VAL_ 1480 EPBL_a242_highCurrent 1 "LV_ON" 2 "LV_GOING_DOWN" 3 "LV_FAULT" 0 "LV_OFF" ;
VAL_ 1480 EPBL_a241_highCurrent 1 "LV_ON" 2 "LV_GOING_DOWN" 3 "LV_FAULT" 0 "LV_OFF" ;
VAL_ 1480 EPBL_a189_esmOpTrigger 20 "EPB_TRIGGER_TIMEOUT" 2 "EPB_TRIGGER_PBUTTON_PRESSED_FAST" 19 "EPB_TRIGGER_SPEED_FAST" 3 "EPB_TRIGGER_PBUTTON_PRESSED_UNKNOWN" 27 "EPB_TRIGGER_EPBM_DISQUALIFIED" 10 "EPB_TRIGGER_WINCHMODE_UNAVAILABLE" 28 "EPB_TRIGGER_ACCELERATION" 12 "EPB_TRIGGER_DIAG_CLOSE" 24 "EPB_TRIGGER_FAULT" 25 "EPB_TRIGGER_SUMMON_FAULT" 30 "EPB_TRIGGER_DRIVER_IS_LEAVING" 18 "EPB_TRIGGER_SPEED_OKAYTOPARK" 1 "EPB_TRIGGER_PBUTTON_PRESSED_OKTOPARK" 4 "EPB_TRIGGER_PBUTTON_RELEASED" 14 "EPB_TRIGGER_DIAG_EXIT" 21 "EPB_TRIGGER_SAVESTATE_ON_BOOT" 6 "EPB_TRIGGER_DI_UNPARK" 23 "EPB_TRIGGER_SUMMON_COMPLETE" 22 "EPB_TRIGGER_REAPPLY" 26 "EPB_TRIGGER_DISQUALIFIED" 16 "EPB_TRIGGER_USER_CANCEL" 13 "EPB_TRIGGER_DIAG_OPEN" 11 "EPB_TRIGGER_SERVICE" 5 "EPB_TRIGGER_ACTIVE_PARK_REQUEST" 15 "EPB_TRIGGER_USER_CONFIRMED" 8 "EPB_TRIGGER_WINCHMODE_EXIT" 9 "EPB_TRIGGER_WINCHMODE_ENTER" 17 "EPB_TRIGGER_SPEED_STOPPED" 0 "EPB_TRIGGER_PBUTTON_PRESSED_STOPPED" 7 "EPB_TRIGGER_TOUCHSCREEN" 29 "EPB_TRIGGER_SYSTEM_APPLY" ;
VAL_ 1480 EPBL_a177_esmStateRequest 11 "ESM_PARK_PENDING" 1 "ESM_PARK" 3 "ESM_OPEN" 5 "ESM_SUMMON" 0 "ESM_INIT" 6 "ESM_WINCHMODE" 13 "ESM_SUMMON_PARK" 18 "ESM_DYNAMIC_EXTERNAL_EXIT" 19 "ESM_UNKNOWN" 12 "ESM_WINCHMODE_PENDING" 8 "ESM_DIAGNOSTIC_PARK" 16 "ESM_LATCHED_DYNAMIC_EXTERNAL" 2 "ESM_REAPPLY" 9 "ESM_DIAGNOSTIC_OPEN" 14 "ESM_DYNAMIC_EXTERNAL" 10 "ESM_DYNAMIC_PARK" 17 "ESM_SERVICE_PENDING" 15 "ESM_DYNAMIC_PENDING" 7 "ESM_SERVICE" 4 "ESM_DYNAMIC" ;
VAL_ 1480 EPBL_a242_vehiclePowerState 3 "VEHICLE_POWER_STATE_DRIVE" 1 "VEHICLE_POWER_STATE_CONDITIONING" 2 "VEHICLE_POWER_STATE_ACCESSORY" 0 "VEHICLE_POWER_STATE_OFF" ;
VAL_ 1480 EPBL_a184_esmOpTrigger 20 "EPB_TRIGGER_TIMEOUT" 2 "EPB_TRIGGER_PBUTTON_PRESSED_FAST" 19 "EPB_TRIGGER_SPEED_FAST" 3 "EPB_TRIGGER_PBUTTON_PRESSED_UNKNOWN" 27 "EPB_TRIGGER_EPBM_DISQUALIFIED" 10 "EPB_TRIGGER_WINCHMODE_UNAVAILABLE" 28 "EPB_TRIGGER_ACCELERATION" 12 "EPB_TRIGGER_DIAG_CLOSE" 24 "EPB_TRIGGER_FAULT" 25 "EPB_TRIGGER_SUMMON_FAULT" 30 "EPB_TRIGGER_DRIVER_IS_LEAVING" 18 "EPB_TRIGGER_SPEED_OKAYTOPARK" 1 "EPB_TRIGGER_PBUTTON_PRESSED_OKTOPARK" 4 "EPB_TRIGGER_PBUTTON_RELEASED" 14 "EPB_TRIGGER_DIAG_EXIT" 21 "EPB_TRIGGER_SAVESTATE_ON_BOOT" 6 "EPB_TRIGGER_DI_UNPARK" 23 "EPB_TRIGGER_SUMMON_COMPLETE" 22 "EPB_TRIGGER_REAPPLY" 26 "EPB_TRIGGER_DISQUALIFIED" 16 "EPB_TRIGGER_USER_CANCEL" 13 "EPB_TRIGGER_DIAG_OPEN" 11 "EPB_TRIGGER_SERVICE" 5 "EPB_TRIGGER_ACTIVE_PARK_REQUEST" 15 "EPB_TRIGGER_USER_CONFIRMED" 8 "EPB_TRIGGER_WINCHMODE_EXIT" 9 "EPB_TRIGGER_WINCHMODE_ENTER" 17 "EPB_TRIGGER_SPEED_STOPPED" 0 "EPB_TRIGGER_PBUTTON_PRESSED_STOPPED" 7 "EPB_TRIGGER_TOUCHSCREEN" 29 "EPB_TRIGGER_SYSTEM_APPLY" ;
VAL_ 1480 EPBL_a179_esmStateRequest 11 "ESM_PARK_PENDING" 1 "ESM_PARK" 3 "ESM_OPEN" 5 "ESM_SUMMON" 0 "ESM_INIT" 6 "ESM_WINCHMODE" 13 "ESM_SUMMON_PARK" 18 "ESM_DYNAMIC_EXTERNAL_EXIT" 19 "ESM_UNKNOWN" 12 "ESM_WINCHMODE_PENDING" 8 "ESM_DIAGNOSTIC_PARK" 16 "ESM_LATCHED_DYNAMIC_EXTERNAL" 2 "ESM_REAPPLY" 9 "ESM_DIAGNOSTIC_OPEN" 14 "ESM_DYNAMIC_EXTERNAL" 10 "ESM_DYNAMIC_PARK" 17 "ESM_SERVICE_PENDING" 15 "ESM_DYNAMIC_PENDING" 7 "ESM_SERVICE" 4 "ESM_DYNAMIC" ;
VAL_ 1480 EPBL_a187_esmOpTrigger 20 "EPB_TRIGGER_TIMEOUT" 2 "EPB_TRIGGER_PBUTTON_PRESSED_FAST" 19 "EPB_TRIGGER_SPEED_FAST" 3 "EPB_TRIGGER_PBUTTON_PRESSED_UNKNOWN" 27 "EPB_TRIGGER_EPBM_DISQUALIFIED" 10 "EPB_TRIGGER_WINCHMODE_UNAVAILABLE" 28 "EPB_TRIGGER_ACCELERATION" 12 "EPB_TRIGGER_DIAG_CLOSE" 24 "EPB_TRIGGER_FAULT" 25 "EPB_TRIGGER_SUMMON_FAULT" 30 "EPB_TRIGGER_DRIVER_IS_LEAVING" 18 "EPB_TRIGGER_SPEED_OKAYTOPARK" 1 "EPB_TRIGGER_PBUTTON_PRESSED_OKTOPARK" 4 "EPB_TRIGGER_PBUTTON_RELEASED" 14 "EPB_TRIGGER_DIAG_EXIT" 21 "EPB_TRIGGER_SAVESTATE_ON_BOOT" 6 "EPB_TRIGGER_DI_UNPARK" 23 "EPB_TRIGGER_SUMMON_COMPLETE" 22 "EPB_TRIGGER_REAPPLY" 26 "EPB_TRIGGER_DISQUALIFIED" 16 "EPB_TRIGGER_USER_CANCEL" 13 "EPB_TRIGGER_DIAG_OPEN" 11 "EPB_TRIGGER_SERVICE" 5 "EPB_TRIGGER_ACTIVE_PARK_REQUEST" 15 "EPB_TRIGGER_USER_CONFIRMED" 8 "EPB_TRIGGER_WINCHMODE_EXIT" 9 "EPB_TRIGGER_WINCHMODE_ENTER" 17 "EPB_TRIGGER_SPEED_STOPPED" 0 "EPB_TRIGGER_PBUTTON_PRESSED_STOPPED" 7 "EPB_TRIGGER_TOUCHSCREEN" 29 "EPB_TRIGGER_SYSTEM_APPLY" ;
VAL_ 1480 EPBL_a174_esmStateRequest 11 "ESM_PARK_PENDING" 1 "ESM_PARK" 3 "ESM_OPEN" 5 "ESM_SUMMON" 0 "ESM_INIT" 6 "ESM_WINCHMODE" 13 "ESM_SUMMON_PARK" 18 "ESM_DYNAMIC_EXTERNAL_EXIT" 19 "ESM_UNKNOWN" 12 "ESM_WINCHMODE_PENDING" 8 "ESM_DIAGNOSTIC_PARK" 16 "ESM_LATCHED_DYNAMIC_EXTERNAL" 2 "ESM_REAPPLY" 9 "ESM_DIAGNOSTIC_OPEN" 14 "ESM_DYNAMIC_EXTERNAL" 10 "ESM_DYNAMIC_PARK" 17 "ESM_SERVICE_PENDING" 15 "ESM_DYNAMIC_PENDING" 7 "ESM_SERVICE" 4 "ESM_DYNAMIC" ;
VAL_ 1480 EPBL_a241_vehiclePowerState 3 "VEHICLE_POWER_STATE_DRIVE" 1 "VEHICLE_POWER_STATE_CONDITIONING" 2 "VEHICLE_POWER_STATE_ACCESSORY" 0 "VEHICLE_POWER_STATE_OFF" ;
VAL_ 1480 EPBL_a246_nextState 11 "ESM_PARK_PENDING" 1 "ESM_PARK" 3 "ESM_OPEN" 5 "ESM_SUMMON" 0 "ESM_INIT" 6 "ESM_WINCHMODE" 13 "ESM_SUMMON_PARK" 18 "ESM_DYNAMIC_EXTERNAL_EXIT" 19 "ESM_UNKNOWN" 12 "ESM_WINCHMODE_PENDING" 8 "ESM_DIAGNOSTIC_PARK" 16 "ESM_LATCHED_DYNAMIC_EXTERNAL" 2 "ESM_REAPPLY" 9 "ESM_DIAGNOSTIC_OPEN" 14 "ESM_DYNAMIC_EXTERNAL" 10 "ESM_DYNAMIC_PARK" 17 "ESM_SERVICE_PENDING" 15 "ESM_DYNAMIC_PENDING" 7 "ESM_SERVICE" 4 "ESM_DYNAMIC" ;
VAL_ 1480 EPBL_a173_esmStateRequest 11 "ESM_PARK_PENDING" 1 "ESM_PARK" 3 "ESM_OPEN" 5 "ESM_SUMMON" 0 "ESM_INIT" 6 "ESM_WINCHMODE" 13 "ESM_SUMMON_PARK" 18 "ESM_DYNAMIC_EXTERNAL_EXIT" 19 "ESM_UNKNOWN" 12 "ESM_WINCHMODE_PENDING" 8 "ESM_DIAGNOSTIC_PARK" 16 "ESM_LATCHED_DYNAMIC_EXTERNAL" 2 "ESM_REAPPLY" 9 "ESM_DIAGNOSTIC_OPEN" 14 "ESM_DYNAMIC_EXTERNAL" 10 "ESM_DYNAMIC_PARK" 17 "ESM_SERVICE_PENDING" 15 "ESM_DYNAMIC_PENDING" 7 "ESM_SERVICE" 4 "ESM_DYNAMIC" ;
VAL_ 1480 EPBL_a190_esmStateRequest 11 "ESM_PARK_PENDING" 1 "ESM_PARK" 3 "ESM_OPEN" 5 "ESM_SUMMON" 0 "ESM_INIT" 6 "ESM_WINCHMODE" 13 "ESM_SUMMON_PARK" 18 "ESM_DYNAMIC_EXTERNAL_EXIT" 19 "ESM_UNKNOWN" 12 "ESM_WINCHMODE_PENDING" 8 "ESM_DIAGNOSTIC_PARK" 16 "ESM_LATCHED_DYNAMIC_EXTERNAL" 2 "ESM_REAPPLY" 9 "ESM_DIAGNOSTIC_OPEN" 14 "ESM_DYNAMIC_EXTERNAL" 10 "ESM_DYNAMIC_PARK" 17 "ESM_SERVICE_PENDING" 15 "ESM_DYNAMIC_PENDING" 7 "ESM_SERVICE" 4 "ESM_DYNAMIC" ;
VAL_ 1480 EPBL_a188_esmOpTrigger 20 "EPB_TRIGGER_TIMEOUT" 2 "EPB_TRIGGER_PBUTTON_PRESSED_FAST" 19 "EPB_TRIGGER_SPEED_FAST" 3 "EPB_TRIGGER_PBUTTON_PRESSED_UNKNOWN" 27 "EPB_TRIGGER_EPBM_DISQUALIFIED" 10 "EPB_TRIGGER_WINCHMODE_UNAVAILABLE" 28 "EPB_TRIGGER_ACCELERATION" 12 "EPB_TRIGGER_DIAG_CLOSE" 24 "EPB_TRIGGER_FAULT" 25 "EPB_TRIGGER_SUMMON_FAULT" 30 "EPB_TRIGGER_DRIVER_IS_LEAVING" 18 "EPB_TRIGGER_SPEED_OKAYTOPARK" 1 "EPB_TRIGGER_PBUTTON_PRESSED_OKTOPARK" 4 "EPB_TRIGGER_PBUTTON_RELEASED" 14 "EPB_TRIGGER_DIAG_EXIT" 21 "EPB_TRIGGER_SAVESTATE_ON_BOOT" 6 "EPB_TRIGGER_DI_UNPARK" 23 "EPB_TRIGGER_SUMMON_COMPLETE" 22 "EPB_TRIGGER_REAPPLY" 26 "EPB_TRIGGER_DISQUALIFIED" 16 "EPB_TRIGGER_USER_CANCEL" 13 "EPB_TRIGGER_DIAG_OPEN" 11 "EPB_TRIGGER_SERVICE" 5 "EPB_TRIGGER_ACTIVE_PARK_REQUEST" 15 "EPB_TRIGGER_USER_CONFIRMED" 8 "EPB_TRIGGER_WINCHMODE_EXIT" 9 "EPB_TRIGGER_WINCHMODE_ENTER" 17 "EPB_TRIGGER_SPEED_STOPPED" 0 "EPB_TRIGGER_PBUTTON_PRESSED_STOPPED" 7 "EPB_TRIGGER_TOUCHSCREEN" 29 "EPB_TRIGGER_SYSTEM_APPLY" ;
VAL_ 1480 EPBL_a175_esmStateRequest 11 "ESM_PARK_PENDING" 1 "ESM_PARK" 3 "ESM_OPEN" 5 "ESM_SUMMON" 0 "ESM_INIT" 6 "ESM_WINCHMODE" 13 "ESM_SUMMON_PARK" 18 "ESM_DYNAMIC_EXTERNAL_EXIT" 19 "ESM_UNKNOWN" 12 "ESM_WINCHMODE_PENDING" 8 "ESM_DIAGNOSTIC_PARK" 16 "ESM_LATCHED_DYNAMIC_EXTERNAL" 2 "ESM_REAPPLY" 9 "ESM_DIAGNOSTIC_OPEN" 14 "ESM_DYNAMIC_EXTERNAL" 10 "ESM_DYNAMIC_PARK" 17 "ESM_SERVICE_PENDING" 15 "ESM_DYNAMIC_PENDING" 7 "ESM_SERVICE" 4 "ESM_DYNAMIC" ;
VAL_ 1480 EPBL_a186_esmOpTrigger 20 "EPB_TRIGGER_TIMEOUT" 2 "EPB_TRIGGER_PBUTTON_PRESSED_FAST" 19 "EPB_TRIGGER_SPEED_FAST" 3 "EPB_TRIGGER_PBUTTON_PRESSED_UNKNOWN" 27 "EPB_TRIGGER_EPBM_DISQUALIFIED" 10 "EPB_TRIGGER_WINCHMODE_UNAVAILABLE" 28 "EPB_TRIGGER_ACCELERATION" 12 "EPB_TRIGGER_DIAG_CLOSE" 24 "EPB_TRIGGER_FAULT" 25 "EPB_TRIGGER_SUMMON_FAULT" 30 "EPB_TRIGGER_DRIVER_IS_LEAVING" 18 "EPB_TRIGGER_SPEED_OKAYTOPARK" 1 "EPB_TRIGGER_PBUTTON_PRESSED_OKTOPARK" 4 "EPB_TRIGGER_PBUTTON_RELEASED" 14 "EPB_TRIGGER_DIAG_EXIT" 21 "EPB_TRIGGER_SAVESTATE_ON_BOOT" 6 "EPB_TRIGGER_DI_UNPARK" 23 "EPB_TRIGGER_SUMMON_COMPLETE" 22 "EPB_TRIGGER_REAPPLY" 26 "EPB_TRIGGER_DISQUALIFIED" 16 "EPB_TRIGGER_USER_CANCEL" 13 "EPB_TRIGGER_DIAG_OPEN" 11 "EPB_TRIGGER_SERVICE" 5 "EPB_TRIGGER_ACTIVE_PARK_REQUEST" 15 "EPB_TRIGGER_USER_CONFIRMED" 8 "EPB_TRIGGER_WINCHMODE_EXIT" 9 "EPB_TRIGGER_WINCHMODE_ENTER" 17 "EPB_TRIGGER_SPEED_STOPPED" 0 "EPB_TRIGGER_PBUTTON_PRESSED_STOPPED" 7 "EPB_TRIGGER_TOUCHSCREEN" 29 "EPB_TRIGGER_SYSTEM_APPLY" ;
VAL_ 1480 EPBL_a248_esmStateRequest 11 "ESM_PARK_PENDING" 1 "ESM_PARK" 3 "ESM_OPEN" 5 "ESM_SUMMON" 0 "ESM_INIT" 6 "ESM_WINCHMODE" 13 "ESM_SUMMON_PARK" 18 "ESM_DYNAMIC_EXTERNAL_EXIT" 19 "ESM_UNKNOWN" 12 "ESM_WINCHMODE_PENDING" 8 "ESM_DIAGNOSTIC_PARK" 16 "ESM_LATCHED_DYNAMIC_EXTERNAL" 2 "ESM_REAPPLY" 9 "ESM_DIAGNOSTIC_OPEN" 14 "ESM_DYNAMIC_EXTERNAL" 10 "ESM_DYNAMIC_PARK" 17 "ESM_SERVICE_PENDING" 15 "ESM_DYNAMIC_PENDING" 7 "ESM_SERVICE" 4 "ESM_DYNAMIC" ;
VAL_ 1480 EPBL_a247_esmStateRequest 11 "ESM_PARK_PENDING" 1 "ESM_PARK" 3 "ESM_OPEN" 5 "ESM_SUMMON" 0 "ESM_INIT" 6 "ESM_WINCHMODE" 13 "ESM_SUMMON_PARK" 18 "ESM_DYNAMIC_EXTERNAL_EXIT" 19 "ESM_UNKNOWN" 12 "ESM_WINCHMODE_PENDING" 8 "ESM_DIAGNOSTIC_PARK" 16 "ESM_LATCHED_DYNAMIC_EXTERNAL" 2 "ESM_REAPPLY" 9 "ESM_DIAGNOSTIC_OPEN" 14 "ESM_DYNAMIC_EXTERNAL" 10 "ESM_DYNAMIC_PARK" 17 "ESM_SERVICE_PENDING" 15 "ESM_DYNAMIC_PENDING" 7 "ESM_SERVICE" 4 "ESM_DYNAMIC" ;
VAL_ 1480 EPBL_a191_esmStateRequest 11 "ESM_PARK_PENDING" 1 "ESM_PARK" 3 "ESM_OPEN" 5 "ESM_SUMMON" 0 "ESM_INIT" 6 "ESM_WINCHMODE" 13 "ESM_SUMMON_PARK" 18 "ESM_DYNAMIC_EXTERNAL_EXIT" 19 "ESM_UNKNOWN" 12 "ESM_WINCHMODE_PENDING" 8 "ESM_DIAGNOSTIC_PARK" 16 "ESM_LATCHED_DYNAMIC_EXTERNAL" 2 "ESM_REAPPLY" 9 "ESM_DIAGNOSTIC_OPEN" 14 "ESM_DYNAMIC_EXTERNAL" 10 "ESM_DYNAMIC_PARK" 17 "ESM_SERVICE_PENDING" 15 "ESM_DYNAMIC_PENDING" 7 "ESM_SERVICE" 4 "ESM_DYNAMIC" ;
VAL_ 1480 EPBL_a249_nextState 11 "ESM_PARK_PENDING" 1 "ESM_PARK" 3 "ESM_OPEN" 5 "ESM_SUMMON" 0 "ESM_INIT" 6 "ESM_WINCHMODE" 13 "ESM_SUMMON_PARK" 18 "ESM_DYNAMIC_EXTERNAL_EXIT" 19 "ESM_UNKNOWN" 12 "ESM_WINCHMODE_PENDING" 8 "ESM_DIAGNOSTIC_PARK" 16 "ESM_LATCHED_DYNAMIC_EXTERNAL" 2 "ESM_REAPPLY" 9 "ESM_DIAGNOSTIC_OPEN" 14 "ESM_DYNAMIC_EXTERNAL" 10 "ESM_DYNAMIC_PARK" 17 "ESM_SERVICE_PENDING" 15 "ESM_DYNAMIC_PENDING" 7 "ESM_SERVICE" 4 "ESM_DYNAMIC" ;
VAL_ 1480 EPBL_a300_subUsageId 11 "ESM_PARK_PENDING" 1 "ESM_PARK" 3 "ESM_OPEN" 5 "ESM_SUMMON" 0 "ESM_INIT" 6 "ESM_WINCHMODE" 13 "ESM_SUMMON_PARK" 18 "ESM_DYNAMIC_EXTERNAL_EXIT" 19 "ESM_UNKNOWN" 12 "ESM_WINCHMODE_PENDING" 8 "ESM_DIAGNOSTIC_PARK" 16 "ESM_LATCHED_DYNAMIC_EXTERNAL" 2 "ESM_REAPPLY" 9 "ESM_DIAGNOSTIC_OPEN" 14 "ESM_DYNAMIC_EXTERNAL" 10 "ESM_DYNAMIC_PARK" 17 "ESM_SERVICE_PENDING" 15 "ESM_DYNAMIC_PENDING" 7 "ESM_SERVICE" 4 "ESM_DYNAMIC" ;
VAL_ 1480 EPBL_a141_toState 11 "ESM_PARK_PENDING" 1 "ESM_PARK" 3 "ESM_OPEN" 5 "ESM_SUMMON" 0 "ESM_INIT" 6 "ESM_WINCHMODE" 13 "ESM_SUMMON_PARK" 18 "ESM_DYNAMIC_EXTERNAL_EXIT" 19 "ESM_UNKNOWN" 12 "ESM_WINCHMODE_PENDING" 8 "ESM_DIAGNOSTIC_PARK" 16 "ESM_LATCHED_DYNAMIC_EXTERNAL" 2 "ESM_REAPPLY" 9 "ESM_DIAGNOSTIC_OPEN" 14 "ESM_DYNAMIC_EXTERNAL" 10 "ESM_DYNAMIC_PARK" 17 "ESM_SERVICE_PENDING" 15 "ESM_DYNAMIC_PENDING" 7 "ESM_SERVICE" 4 "ESM_DYNAMIC" ;
VAL_ 1480 EPBL_a176_esmStateRequest 11 "ESM_PARK_PENDING" 1 "ESM_PARK" 3 "ESM_OPEN" 5 "ESM_SUMMON" 0 "ESM_INIT" 6 "ESM_WINCHMODE" 13 "ESM_SUMMON_PARK" 18 "ESM_DYNAMIC_EXTERNAL_EXIT" 19 "ESM_UNKNOWN" 12 "ESM_WINCHMODE_PENDING" 8 "ESM_DIAGNOSTIC_PARK" 16 "ESM_LATCHED_DYNAMIC_EXTERNAL" 2 "ESM_REAPPLY" 9 "ESM_DIAGNOSTIC_OPEN" 14 "ESM_DYNAMIC_EXTERNAL" 10 "ESM_DYNAMIC_PARK" 17 "ESM_SERVICE_PENDING" 15 "ESM_DYNAMIC_PENDING" 7 "ESM_SERVICE" 4 "ESM_DYNAMIC" ;
VAL_ 1480 EPBL_a180_esmOpTrigger 20 "EPB_TRIGGER_TIMEOUT" 2 "EPB_TRIGGER_PBUTTON_PRESSED_FAST" 19 "EPB_TRIGGER_SPEED_FAST" 3 "EPB_TRIGGER_PBUTTON_PRESSED_UNKNOWN" 27 "EPB_TRIGGER_EPBM_DISQUALIFIED" 10 "EPB_TRIGGER_WINCHMODE_UNAVAILABLE" 28 "EPB_TRIGGER_ACCELERATION" 12 "EPB_TRIGGER_DIAG_CLOSE" 24 "EPB_TRIGGER_FAULT" 25 "EPB_TRIGGER_SUMMON_FAULT" 30 "EPB_TRIGGER_DRIVER_IS_LEAVING" 18 "EPB_TRIGGER_SPEED_OKAYTOPARK" 1 "EPB_TRIGGER_PBUTTON_PRESSED_OKTOPARK" 4 "EPB_TRIGGER_PBUTTON_RELEASED" 14 "EPB_TRIGGER_DIAG_EXIT" 21 "EPB_TRIGGER_SAVESTATE_ON_BOOT" 6 "EPB_TRIGGER_DI_UNPARK" 23 "EPB_TRIGGER_SUMMON_COMPLETE" 22 "EPB_TRIGGER_REAPPLY" 26 "EPB_TRIGGER_DISQUALIFIED" 16 "EPB_TRIGGER_USER_CANCEL" 13 "EPB_TRIGGER_DIAG_OPEN" 11 "EPB_TRIGGER_SERVICE" 5 "EPB_TRIGGER_ACTIVE_PARK_REQUEST" 15 "EPB_TRIGGER_USER_CONFIRMED" 8 "EPB_TRIGGER_WINCHMODE_EXIT" 9 "EPB_TRIGGER_WINCHMODE_ENTER" 17 "EPB_TRIGGER_SPEED_STOPPED" 0 "EPB_TRIGGER_PBUTTON_PRESSED_STOPPED" 7 "EPB_TRIGGER_TOUCHSCREEN" 29 "EPB_TRIGGER_SYSTEM_APPLY" ;
VAL_ 1480 EPBL_a183_esmOpTrigger 20 "EPB_TRIGGER_TIMEOUT" 2 "EPB_TRIGGER_PBUTTON_PRESSED_FAST" 19 "EPB_TRIGGER_SPEED_FAST" 3 "EPB_TRIGGER_PBUTTON_PRESSED_UNKNOWN" 27 "EPB_TRIGGER_EPBM_DISQUALIFIED" 10 "EPB_TRIGGER_WINCHMODE_UNAVAILABLE" 28 "EPB_TRIGGER_ACCELERATION" 12 "EPB_TRIGGER_DIAG_CLOSE" 24 "EPB_TRIGGER_FAULT" 25 "EPB_TRIGGER_SUMMON_FAULT" 30 "EPB_TRIGGER_DRIVER_IS_LEAVING" 18 "EPB_TRIGGER_SPEED_OKAYTOPARK" 1 "EPB_TRIGGER_PBUTTON_PRESSED_OKTOPARK" 4 "EPB_TRIGGER_PBUTTON_RELEASED" 14 "EPB_TRIGGER_DIAG_EXIT" 21 "EPB_TRIGGER_SAVESTATE_ON_BOOT" 6 "EPB_TRIGGER_DI_UNPARK" 23 "EPB_TRIGGER_SUMMON_COMPLETE" 22 "EPB_TRIGGER_REAPPLY" 26 "EPB_TRIGGER_DISQUALIFIED" 16 "EPB_TRIGGER_USER_CANCEL" 13 "EPB_TRIGGER_DIAG_OPEN" 11 "EPB_TRIGGER_SERVICE" 5 "EPB_TRIGGER_ACTIVE_PARK_REQUEST" 15 "EPB_TRIGGER_USER_CONFIRMED" 8 "EPB_TRIGGER_WINCHMODE_EXIT" 9 "EPB_TRIGGER_WINCHMODE_ENTER" 17 "EPB_TRIGGER_SPEED_STOPPED" 0 "EPB_TRIGGER_PBUTTON_PRESSED_STOPPED" 7 "EPB_TRIGGER_TOUCHSCREEN" 29 "EPB_TRIGGER_SYSTEM_APPLY" ;
VAL_ 1480 EPBL_a242_hvState 6 "HV_UP" 5 "HV_UP_FOR_DC_CHARGE" 0 "HV_DOWN" 2 "HV_GOING_DOWN" 1 "HV_COMING_UP" 4 "HV_UP_FOR_CHARGE" 3 "HV_UP_FOR_DRIVE" ;
VAL_ 1480 EPBL_a178_monitorCaliperState 5 "EPB_SAVED_CALIPERSTATE_SERVICE" 1 "EPB_SAVED_CALIPERSTATE_UNKNOWN" 4 "EPB_SAVED_CALIPERSTATE_OPEN" 2 "EPB_SAVED_CALIPERSTATE_REAPPLY" 0 "EPB_SAVED_CALIPERSTATE_UNSAVED" 3 "EPB_SAVED_CALIPERSTATE_PARK" ;
VAL_ 1480 EPBL_a241_epbSysStatus 0 "EPB_VEHICLE_STATUS_UNKNOWN" 2 "EPB_VEHICLE_STATUS_PARKED" 6 "EPB_VEHICLE_STATUS_FAULT" 3 "EPB_VEHICLE_STATUS_DYNAMIC" 1 "EPB_VEHICLE_STATUS_RELEASED" 4 "EPB_VEHICLE_STATUS_PARKING" 5 "EPB_VEHICLE_STATUS_RELEASING" 8 "EPB_VEHICLE_STATUS_MISMATCH" 7 "EPB_VEHICLE_STATUS_FAULT_SECURE" ;
VAL_ 1480 EPBL_a189_monitorCDPStatus 0 "EPB_EXTERNAL_APPLY_IDLE" 1 "EPB_EXTERNAL_APPLY_VALID" 2 "EPB_EXTERNAL_APPLY_INVALID" ;
VAL_ 1480 EPBL_a186_monitorCDPStatus 0 "EPB_EXTERNAL_APPLY_IDLE" 1 "EPB_EXTERNAL_APPLY_VALID" 2 "EPB_EXTERNAL_APPLY_INVALID" ;
VAL_ 1480 EPBL_a183_monitorCDPStatus 0 "EPB_EXTERNAL_APPLY_IDLE" 1 "EPB_EXTERNAL_APPLY_VALID" 2 "EPB_EXTERNAL_APPLY_INVALID" ;
VAL_ 1480 EPBL_a180_monitorCDPStatus 0 "EPB_EXTERNAL_APPLY_IDLE" 1 "EPB_EXTERNAL_APPLY_VALID" 2 "EPB_EXTERNAL_APPLY_INVALID" ;
VAL_ 1480 EPBL_a187_monitorCDPStatus 0 "EPB_EXTERNAL_APPLY_IDLE" 1 "EPB_EXTERNAL_APPLY_VALID" 2 "EPB_EXTERNAL_APPLY_INVALID" ;
VAL_ 1480 EPBL_a184_monitorCDPStatus 0 "EPB_EXTERNAL_APPLY_IDLE" 1 "EPB_EXTERNAL_APPLY_VALID" 2 "EPB_EXTERNAL_APPLY_INVALID" ;
VAL_ 1480 EPBL_a188_monitorCDPStatus 0 "EPB_EXTERNAL_APPLY_IDLE" 1 "EPB_EXTERNAL_APPLY_VALID" 2 "EPB_EXTERNAL_APPLY_INVALID" ;
VAL_ 1480 EPBL_a201_epbHWBrakeType 1 "EPB_BRAKE_HARDWARE_MANDO" 0 "EPB_BRAKE_HARDWARE_UNKNOWN" 2 "EPB_BRAKE_HARDWARE_BREMBO" ;
VAL_ 1480 EPBL_a179_esmState 11 "ESM_PARK_PENDING" 1 "ESM_PARK" 3 "ESM_OPEN" 5 "ESM_SUMMON" 0 "ESM_INIT" 6 "ESM_WINCHMODE" 13 "ESM_SUMMON_PARK" 18 "ESM_DYNAMIC_EXTERNAL_EXIT" 19 "ESM_UNKNOWN" 12 "ESM_WINCHMODE_PENDING" 8 "ESM_DIAGNOSTIC_PARK" 16 "ESM_LATCHED_DYNAMIC_EXTERNAL" 2 "ESM_REAPPLY" 9 "ESM_DIAGNOSTIC_OPEN" 14 "ESM_DYNAMIC_EXTERNAL" 10 "ESM_DYNAMIC_PARK" 17 "ESM_SERVICE_PENDING" 15 "ESM_DYNAMIC_PENDING" 7 "ESM_SERVICE" 4 "ESM_DYNAMIC" ;
VAL_ 1480 EPBL_a188_espCDPStatus 0 "EPB_EXTERNAL_APPLY_IDLE" 1 "EPB_EXTERNAL_APPLY_VALID" 2 "EPB_EXTERNAL_APPLY_INVALID" ;
VAL_ 1480 EPBL_a190_esmState 11 "ESM_PARK_PENDING" 1 "ESM_PARK" 3 "ESM_OPEN" 5 "ESM_SUMMON" 0 "ESM_INIT" 6 "ESM_WINCHMODE" 13 "ESM_SUMMON_PARK" 18 "ESM_DYNAMIC_EXTERNAL_EXIT" 19 "ESM_UNKNOWN" 12 "ESM_WINCHMODE_PENDING" 8 "ESM_DIAGNOSTIC_PARK" 16 "ESM_LATCHED_DYNAMIC_EXTERNAL" 2 "ESM_REAPPLY" 9 "ESM_DIAGNOSTIC_OPEN" 14 "ESM_DYNAMIC_EXTERNAL" 10 "ESM_DYNAMIC_PARK" 17 "ESM_SERVICE_PENDING" 15 "ESM_DYNAMIC_PENDING" 7 "ESM_SERVICE" 4 "ESM_DYNAMIC" ;
VAL_ 1480 EPBL_a173_esmState 11 "ESM_PARK_PENDING" 1 "ESM_PARK" 3 "ESM_OPEN" 5 "ESM_SUMMON" 0 "ESM_INIT" 6 "ESM_WINCHMODE" 13 "ESM_SUMMON_PARK" 18 "ESM_DYNAMIC_EXTERNAL_EXIT" 19 "ESM_UNKNOWN" 12 "ESM_WINCHMODE_PENDING" 8 "ESM_DIAGNOSTIC_PARK" 16 "ESM_LATCHED_DYNAMIC_EXTERNAL" 2 "ESM_REAPPLY" 9 "ESM_DIAGNOSTIC_OPEN" 14 "ESM_DYNAMIC_EXTERNAL" 10 "ESM_DYNAMIC_PARK" 17 "ESM_SERVICE_PENDING" 15 "ESM_DYNAMIC_PENDING" 7 "ESM_SERVICE" 4 "ESM_DYNAMIC" ;
VAL_ 1480 EPBL_a249_previousState 11 "ESM_PARK_PENDING" 1 "ESM_PARK" 3 "ESM_OPEN" 5 "ESM_SUMMON" 0 "ESM_INIT" 6 "ESM_WINCHMODE" 13 "ESM_SUMMON_PARK" 18 "ESM_DYNAMIC_EXTERNAL_EXIT" 19 "ESM_UNKNOWN" 12 "ESM_WINCHMODE_PENDING" 8 "ESM_DIAGNOSTIC_PARK" 16 "ESM_LATCHED_DYNAMIC_EXTERNAL" 2 "ESM_REAPPLY" 9 "ESM_DIAGNOSTIC_OPEN" 14 "ESM_DYNAMIC_EXTERNAL" 10 "ESM_DYNAMIC_PARK" 17 "ESM_SERVICE_PENDING" 15 "ESM_DYNAMIC_PENDING" 7 "ESM_SERVICE" 4 "ESM_DYNAMIC" ;
VAL_ 1480 EPBL_a186_espCDPStatus 0 "EPB_EXTERNAL_APPLY_IDLE" 1 "EPB_EXTERNAL_APPLY_VALID" 2 "EPB_EXTERNAL_APPLY_INVALID" ;
VAL_ 1480 EPBL_a248_esmState 11 "ESM_PARK_PENDING" 1 "ESM_PARK" 3 "ESM_OPEN" 5 "ESM_SUMMON" 0 "ESM_INIT" 6 "ESM_WINCHMODE" 13 "ESM_SUMMON_PARK" 18 "ESM_DYNAMIC_EXTERNAL_EXIT" 19 "ESM_UNKNOWN" 12 "ESM_WINCHMODE_PENDING" 8 "ESM_DIAGNOSTIC_PARK" 16 "ESM_LATCHED_DYNAMIC_EXTERNAL" 2 "ESM_REAPPLY" 9 "ESM_DIAGNOSTIC_OPEN" 14 "ESM_DYNAMIC_EXTERNAL" 10 "ESM_DYNAMIC_PARK" 17 "ESM_SERVICE_PENDING" 15 "ESM_DYNAMIC_PENDING" 7 "ESM_SERVICE" 4 "ESM_DYNAMIC" ;
VAL_ 1480 EPBL_a183_espCDPStatus 0 "EPB_EXTERNAL_APPLY_IDLE" 1 "EPB_EXTERNAL_APPLY_VALID" 2 "EPB_EXTERNAL_APPLY_INVALID" ;
VAL_ 1480 EPBL_a175_esmState 11 "ESM_PARK_PENDING" 1 "ESM_PARK" 3 "ESM_OPEN" 5 "ESM_SUMMON" 0 "ESM_INIT" 6 "ESM_WINCHMODE" 13 "ESM_SUMMON_PARK" 18 "ESM_DYNAMIC_EXTERNAL_EXIT" 19 "ESM_UNKNOWN" 12 "ESM_WINCHMODE_PENDING" 8 "ESM_DIAGNOSTIC_PARK" 16 "ESM_LATCHED_DYNAMIC_EXTERNAL" 2 "ESM_REAPPLY" 9 "ESM_DIAGNOSTIC_OPEN" 14 "ESM_DYNAMIC_EXTERNAL" 10 "ESM_DYNAMIC_PARK" 17 "ESM_SERVICE_PENDING" 15 "ESM_DYNAMIC_PENDING" 7 "ESM_SERVICE" 4 "ESM_DYNAMIC" ;
VAL_ 1480 EPBL_a247_esmState 11 "ESM_PARK_PENDING" 1 "ESM_PARK" 3 "ESM_OPEN" 5 "ESM_SUMMON" 0 "ESM_INIT" 6 "ESM_WINCHMODE" 13 "ESM_SUMMON_PARK" 18 "ESM_DYNAMIC_EXTERNAL_EXIT" 19 "ESM_UNKNOWN" 12 "ESM_WINCHMODE_PENDING" 8 "ESM_DIAGNOSTIC_PARK" 16 "ESM_LATCHED_DYNAMIC_EXTERNAL" 2 "ESM_REAPPLY" 9 "ESM_DIAGNOSTIC_OPEN" 14 "ESM_DYNAMIC_EXTERNAL" 10 "ESM_DYNAMIC_PARK" 17 "ESM_SERVICE_PENDING" 15 "ESM_DYNAMIC_PENDING" 7 "ESM_SERVICE" 4 "ESM_DYNAMIC" ;
VAL_ 1480 EPBL_a191_esmState 11 "ESM_PARK_PENDING" 1 "ESM_PARK" 3 "ESM_OPEN" 5 "ESM_SUMMON" 0 "ESM_INIT" 6 "ESM_WINCHMODE" 13 "ESM_SUMMON_PARK" 18 "ESM_DYNAMIC_EXTERNAL_EXIT" 19 "ESM_UNKNOWN" 12 "ESM_WINCHMODE_PENDING" 8 "ESM_DIAGNOSTIC_PARK" 16 "ESM_LATCHED_DYNAMIC_EXTERNAL" 2 "ESM_REAPPLY" 9 "ESM_DIAGNOSTIC_OPEN" 14 "ESM_DYNAMIC_EXTERNAL" 10 "ESM_DYNAMIC_PARK" 17 "ESM_SERVICE_PENDING" 15 "ESM_DYNAMIC_PENDING" 7 "ESM_SERVICE" 4 "ESM_DYNAMIC" ;
VAL_ 1480 EPBL_a189_espCDPStatus 0 "EPB_EXTERNAL_APPLY_IDLE" 1 "EPB_EXTERNAL_APPLY_VALID" 2 "EPB_EXTERNAL_APPLY_INVALID" ;
VAL_ 1480 EPBL_a187_espCDPStatus 0 "EPB_EXTERNAL_APPLY_IDLE" 1 "EPB_EXTERNAL_APPLY_VALID" 2 "EPB_EXTERNAL_APPLY_INVALID" ;
VAL_ 1480 EPBL_a180_espCDPStatus 0 "EPB_EXTERNAL_APPLY_IDLE" 1 "EPB_EXTERNAL_APPLY_VALID" 2 "EPB_EXTERNAL_APPLY_INVALID" ;
VAL_ 1480 EPBL_a176_esmState 11 "ESM_PARK_PENDING" 1 "ESM_PARK" 3 "ESM_OPEN" 5 "ESM_SUMMON" 0 "ESM_INIT" 6 "ESM_WINCHMODE" 13 "ESM_SUMMON_PARK" 18 "ESM_DYNAMIC_EXTERNAL_EXIT" 19 "ESM_UNKNOWN" 12 "ESM_WINCHMODE_PENDING" 8 "ESM_DIAGNOSTIC_PARK" 16 "ESM_LATCHED_DYNAMIC_EXTERNAL" 2 "ESM_REAPPLY" 9 "ESM_DIAGNOSTIC_OPEN" 14 "ESM_DYNAMIC_EXTERNAL" 10 "ESM_DYNAMIC_PARK" 17 "ESM_SERVICE_PENDING" 15 "ESM_DYNAMIC_PENDING" 7 "ESM_SERVICE" 4 "ESM_DYNAMIC" ;
VAL_ 1480 EPBL_a178_localCaliperState 5 "EPB_SAVED_CALIPERSTATE_SERVICE" 1 "EPB_SAVED_CALIPERSTATE_UNKNOWN" 4 "EPB_SAVED_CALIPERSTATE_OPEN" 2 "EPB_SAVED_CALIPERSTATE_REAPPLY" 0 "EPB_SAVED_CALIPERSTATE_UNSAVED" 3 "EPB_SAVED_CALIPERSTATE_PARK" ;
VAL_ 1480 EPBL_a182_epbSysStatus 0 "EPB_VEHICLE_STATUS_UNKNOWN" 2 "EPB_VEHICLE_STATUS_PARKED" 6 "EPB_VEHICLE_STATUS_FAULT" 3 "EPB_VEHICLE_STATUS_DYNAMIC" 1 "EPB_VEHICLE_STATUS_RELEASED" 4 "EPB_VEHICLE_STATUS_PARKING" 5 "EPB_VEHICLE_STATUS_RELEASING" 8 "EPB_VEHICLE_STATUS_MISMATCH" 7 "EPB_VEHICLE_STATUS_FAULT_SECURE" ;
VAL_ 1480 EPBL_a184_espCDPStatus 0 "EPB_EXTERNAL_APPLY_IDLE" 1 "EPB_EXTERNAL_APPLY_VALID" 2 "EPB_EXTERNAL_APPLY_INVALID" ;
VAL_ 1480 EPBL_a121_caliperState 8 "CSM_WAIT_FOR_ENDSTOP" 9 "CSM_RELEASE_COMPLETE" 12 "CSM_FAULT" 5 "CSM_APPLY_COMPLETE" 7 "CSM_RELEASE_NOLOAD" 14 "CSM_HOLD_CLAMP" 4 "CSM_WAIT_FOR_CLAMP" 6 "CSM_RELEASE_INRUSH" 13 "CSM_STATIONARY_FAULT" 2 "CSM_APPLY_INRUSH" 10 "CSM_CALIBRATE" 1 "CSM_STANDBY" 0 "CSM_INIT" 11 "CSM_HALT" 3 "CSM_APPLY_NOLOAD" ;
VAL_ 1480 EPBL_a177_esmState 11 "ESM_PARK_PENDING" 1 "ESM_PARK" 3 "ESM_OPEN" 5 "ESM_SUMMON" 0 "ESM_INIT" 6 "ESM_WINCHMODE" 13 "ESM_SUMMON_PARK" 18 "ESM_DYNAMIC_EXTERNAL_EXIT" 19 "ESM_UNKNOWN" 12 "ESM_WINCHMODE_PENDING" 8 "ESM_DIAGNOSTIC_PARK" 16 "ESM_LATCHED_DYNAMIC_EXTERNAL" 2 "ESM_REAPPLY" 9 "ESM_DIAGNOSTIC_OPEN" 14 "ESM_DYNAMIC_EXTERNAL" 10 "ESM_DYNAMIC_PARK" 17 "ESM_SERVICE_PENDING" 15 "ESM_DYNAMIC_PENDING" 7 "ESM_SERVICE" 4 "ESM_DYNAMIC" ;
VAL_ 1480 EPBL_a141_fromState 11 "ESM_PARK_PENDING" 1 "ESM_PARK" 3 "ESM_OPEN" 5 "ESM_SUMMON" 0 "ESM_INIT" 6 "ESM_WINCHMODE" 13 "ESM_SUMMON_PARK" 18 "ESM_DYNAMIC_EXTERNAL_EXIT" 19 "ESM_UNKNOWN" 12 "ESM_WINCHMODE_PENDING" 8 "ESM_DIAGNOSTIC_PARK" 16 "ESM_LATCHED_DYNAMIC_EXTERNAL" 2 "ESM_REAPPLY" 9 "ESM_DIAGNOSTIC_OPEN" 14 "ESM_DYNAMIC_EXTERNAL" 10 "ESM_DYNAMIC_PARK" 17 "ESM_SERVICE_PENDING" 15 "ESM_DYNAMIC_PENDING" 7 "ESM_SERVICE" 4 "ESM_DYNAMIC" ;
VAL_ 1480 EPBL_a185_summonFaultReason 9 "EPB_SUMMONFAULT_VEH_CAN_FAULT" 21 "EPB_SUMMONFAULT_PASSIVE_REQUEST" 26 "EPB_SUMMONFAULT_START_IN_UNAVAILABLE" 5 "EPB_SUMMONFAULT_DI_FAULT" 4 "EPB_SUMMONFAULT_EPBM_MIA" 12 "EPB_SUMMONFAULT_SPEED" 14 "EPB_SUMMONFAULT_PARK_MIA" 19 "EPB_SUMMONFAULT_EPB_FAULT" 25 "EPB_SUMMONFAULT_REMOTE_UNIT_FAULTED" 11 "EPB_SUMMONFAULT_EPBM_REQUEST" 16 "EPB_SUMMONFAULT_PM_REQUEST" 6 "EPB_SUMMONFAULT_DI_APC_FAULT" 13 "EPB_SUMMONFAULT_EXTERNAL" 23 "EPB_SUMMONFAULT_REMOTE_SUMMON_FAULTED" 24 "EPB_SUMMONFAULT_LOCAL_UNIT_FAULTED" 28 "EPB_SUMMONFAULT_REMOTE_DID_NOT_START" 1 "EPB_SUMMONFAULT_DI_MIA" 15 "EPB_SUMMONFAULT_PM_MIA" 27 "EPB_SUMMONFAULT_INVALID_REMOTE_STATE" 0 "EPB_SUMMONFAULT_NONE" 10 "EPB_SUMMONFAULT_EAC_NOT_ALLOWED" 22 "EPB_SUMMONFAULT_EPBREMOTE_MIA" 18 "EPB_SUMMONFAULT_MISMATCH" 3 "EPB_SUMMONFAULT_ESP_MIA" 2 "EPB_SUMMONFAULT_DAS_MIA" 20 "EPB_SUMMONFAULT_DI_STATE_INVALID" 8 "EPB_SUMMONFAULT_ESP_FAULT" 17 "EPB_SUMMONFAULT_OOC" 7 "EPB_SUMMONFAULT_DAS_FAULT" ;
VAL_ 1480 EPBL_a174_esmState 11 "ESM_PARK_PENDING" 1 "ESM_PARK" 3 "ESM_OPEN" 5 "ESM_SUMMON" 0 "ESM_INIT" 6 "ESM_WINCHMODE" 13 "ESM_SUMMON_PARK" 18 "ESM_DYNAMIC_EXTERNAL_EXIT" 19 "ESM_UNKNOWN" 12 "ESM_WINCHMODE_PENDING" 8 "ESM_DIAGNOSTIC_PARK" 16 "ESM_LATCHED_DYNAMIC_EXTERNAL" 2 "ESM_REAPPLY" 9 "ESM_DIAGNOSTIC_OPEN" 14 "ESM_DYNAMIC_EXTERNAL" 10 "ESM_DYNAMIC_PARK" 17 "ESM_SERVICE_PENDING" 15 "ESM_DYNAMIC_PENDING" 7 "ESM_SERVICE" 4 "ESM_DYNAMIC" ;
VAL_ 1480 EPBL_a300_harnessId 11 "ESM_PARK_PENDING" 1 "ESM_PARK" 3 "ESM_OPEN" 5 "ESM_SUMMON" 0 "ESM_INIT" 6 "ESM_WINCHMODE" 13 "ESM_SUMMON_PARK" 18 "ESM_DYNAMIC_EXTERNAL_EXIT" 19 "ESM_UNKNOWN" 12 "ESM_WINCHMODE_PENDING" 8 "ESM_DIAGNOSTIC_PARK" 16 "ESM_LATCHED_DYNAMIC_EXTERNAL" 2 "ESM_REAPPLY" 9 "ESM_DIAGNOSTIC_OPEN" 14 "ESM_DYNAMIC_EXTERNAL" 10 "ESM_DYNAMIC_PARK" 17 "ESM_SERVICE_PENDING" 15 "ESM_DYNAMIC_PENDING" 7 "ESM_SERVICE" 4 "ESM_DYNAMIC" ;
VAL_ 1480 EPBL_a246_previousState 11 "ESM_PARK_PENDING" 1 "ESM_PARK" 3 "ESM_OPEN" 5 "ESM_SUMMON" 0 "ESM_INIT" 6 "ESM_WINCHMODE" 13 "ESM_SUMMON_PARK" 18 "ESM_DYNAMIC_EXTERNAL_EXIT" 19 "ESM_UNKNOWN" 12 "ESM_WINCHMODE_PENDING" 8 "ESM_DIAGNOSTIC_PARK" 16 "ESM_LATCHED_DYNAMIC_EXTERNAL" 2 "ESM_REAPPLY" 9 "ESM_DIAGNOSTIC_OPEN" 14 "ESM_DYNAMIC_EXTERNAL" 10 "ESM_DYNAMIC_PARK" 17 "ESM_SERVICE_PENDING" 15 "ESM_DYNAMIC_PENDING" 7 "ESM_SERVICE" 4 "ESM_DYNAMIC" ;
VAL_ 1480 EPBL_alertType 0 "ALERT_CLEARED" 1 "ALERT_SET" ;
VAL_ 1480 EPBL_alertID 244 "EPBL_a244_WinchModeActive" 109 "EPBL_a109_RCM_MIA" 182 "EPBL_a182_OneEPBAppliedUnsecEnv" 111 "EPBL_a111_EPBR_MIA" 110 "EPBL_a110_GTW_MIA" 243 "EPBL_a243_bdwUnavailable" 118 "EPBL_a118_VCFRONT_MIA" 113 "EPBL_a113_UI_MIA" 122 "EPBL_a122_Oc" 119 "EPBL_a119_SCCM_MIA" 247 "EPBL_a247_csmDynamicApplyRetry" 191 "EPBL_a191_csmReleaseDegraded" 63 "EPBL_a063_SwitchFault" 3 "EPBL_a003_SWAssertion" 105 "EPBL_a105_TAS_MIA" 12 "EPBL_a012_CPUReset" 250 "EPBL_a250_WinchModeCanceled" 180 "EPBL_a180_dynamicActive" 241 "EPBL_a241_diOutputLocked" 101 "EPBL_a101_PM_MIA" 128 "EPBL_a128_MotorPVoltHigh" 115 "EPBL_a115_VCSEC_MIA" 175 "EPBL_a175_csmReleaseRetry" 22 "EPBL_a022_TaskInitError" 124 "EPBL_a124_calOutOfBounds" 120 "EPBL_a120_DI_DRIVE_MIA" 134 "EPBL_a134_NvOv" 97 "EPBL_a097_CMP_MIA" 141 "EPBL_a141_invalidState" 99 "EPBL_a099_PARK_MIA" 170 "EPBL_a170_12vOv" 246 "EPBL_a246_idleFaultApply" 44 "EPBL_a044_Task10msError" 10 "EPBL_a010_ExtSupplyVoltError" 300 "EPBL_a300_leftRightConfusion" 190 "EPBL_a190_csmApplyDegraded" 183 "EPBL_a183_cdpNotAvailable" 21 "EPBL_a021_TaskSchedulerError" 116 "EPBL_a116_VCRIGHT_MIA" 171 "EPBL_a171_12vUv" 178 "EPBL_a178_caliperStateUnknown" 104 "EPBL_a104_DAS_MIA" 245 "EPBL_a245_serviceModeActive" 135 "EPBL_a135_NvUv" 195 "EPBL_a195_parkForDriverIsLeaving" 64 "EPBL_a064_busSleepReqTimeout" 100 "EPBL_a100_CANbus_MIA" 41 "EPBL_a041_HighCPULoad" 136 "EPBL_a136_PvOv" 188 "EPBL_a188_epbDynamic" 127 "EPBL_a127_MotorNVoltHigh" 123 "EPBL_a123_Uc" 30 "EPBL_a030_ECULogUploadRequest" 102 "EPBL_a102_PTC_MIA" 126 "EPBL_a126_MotorNVoltLow" 106 "EPBL_a106_PCS_MIA" 108 "EPBL_a108_DIS_MIA" 181 "EPBL_a181_TooSteepGradeToPark" 62 "EPBL_a062_XCPWasConnected" 189 "EPBL_a189_epbDynamicParkCanceled" 43 "EPBL_a043_Task1msError" 174 "EPBL_a174_csmReleaseFailed" 13 "EPBL_a013_AlertManagerFault" 217 "EPBL_a217_SPI_MIA_debugData2" 249 "EPBL_a249_idleFaultRelease" 137 "EPBL_a137_PvUv" 177 "EPBL_a177_csmApplyRetry" 114 "EPBL_a114_ESP_MIA" 185 "EPBL_a185_summonAborted" 125 "EPBL_a125_IdleVMismatch" 107 "EPBL_a107_BMS_MIA" 186 "EPBL_a186_externalParkAbort" 46 "EPBL_a046_Task1000msError" 0 "EPBL_ALERT_DO_NOT_USE_ZERO" 201 "EPBL_a201_hwBrakeTypeMismatch" 59 "EPBL_a059_inputResistanceHigh" 138 "EPBL_a138_NVMWriteTime" 242 "EPBL_a242_hvOutputLocked" 15 "EPBL_a015_NVMMAlert" 121 "EPBL_a121_nDriveFault" 216 "EPBL_a216_SPI_MIA_debugData1" 184 "EPBL_a184_dynamicParkAbort" 176 "EPBL_a176_csmApplyFailed" 98 "EPBL_a098_DI_THERMAL_MIA" 60 "EPBL_a060_engineeringBuild" 1 "EPBL_a001_WatchdogReset" 173 "EPBL_a173_hiCurrentMissing" 248 "EPBL_a248_csmDynamicApplyFailed" 200 "EPBL_a200_PmUnparkNotAllowed" 31 "EPBL_a031_UDSActive" 187 "EPBL_a187_cdpDynamic" 172 "EPBL_a172_SPI_MIA" 251 "EPBL_a251_currentVarianceHigh" 117 "EPBL_a117_VCLEFT_MIA" 2 "EPBL_a002_PowerLossReset" 61 "EPBL_a061_XCPConnected" 112 "EPBL_a112_EPBL_MIA" 103 "EPBL_a103_CP_MIA" 42 "EPBL_a042_HighStackUsage" 45 "EPBL_a045_Task100msError" 179 "EPBL_a179_epbProblem" ;
VAL_ 882 BMS_posCtrDropCorrectedFilt -32768 "SNA" ;
VAL_ 882 BMS_negCtrDropCorrectedFilt -32768 "SNA" ;
VAL_ 882 BMS_negCtrDropCorrected -32768 "SNA" ;
VAL_ 882 BMS_posCtrDropCorrected -32768 "SNA" ;
VAL_ 882 BMS_posCtrDeviationConfidence 65535 "SNA" ;
VAL_ 882 BMS_negCtrDeviationConfidence 65535 "SNA" ;
VAL_ 882 BMS_posCtrDeviationFiltConf 65535 "SNA" ;
VAL_ 882 BMS_negCtrDeviationFiltConf 65535 "SNA" ;
VAL_ 882 BMS_posCtrDeviationFilt -32768 "SNA" ;
VAL_ 882 BMS_negCtrDeviationFilt -32768 "SNA" ;
VAL_ 882 BMS_posCtrDeviation -32768 "SNA" ;
VAL_ 882 BMS_negCtrDeviation -32768 "SNA" ;
VAL_ 882 BMS_balanceState 3 "BALANCE_STATE_VSH_EVEN_WAIT" 5 "BALANCE_STATE_VSH_ODD_WAIT" 0 "BALANCE_STATE_STANDBY" 1 "BALANCE_STATE_BALANCE_ACTIVE" 4 "BALANCE_STATE_VSH_ODD_ON" 2 "BALANCE_STATE_VSH_EVEN_ON" 6 "BALANCE_STATE_VSH_TEST_COMPLETE" ;
VAL_ 882 BMS_log1MuxId 0 "BMS_LOG1_CPU_USAGE1" 3 "BMS_LOG1_STATES_AND_BOOLS" 2 "BMS_LOG1_CPU_USAGE3" 5 "BMS_LOG1_POS_CTR_HEALTH_2" 7 "BMS_LOG1_NEG_CTR_HEALTH_2" 1 "BMS_LOG1_CPU_USAGE2" 4 "BMS_LOG1_POS_CTR_HEALTH_1" 6 "BMS_LOG1_NEG_CTR_HEALTH_1" ;
VAL_ 1880 DI_stateDyno 1 "DI_STATE_STANDBY" 3 "DI_STATE_ABORT" 4 "DI_STATE_ENABLE" 0 "DI_STATE_UNAVAILABLE" 2 "DI_STATE_FAULT" ;
VAL_ 1880 DI_dynoSelector 2 "Mux2" 64 "Mux64" 33 "Mux33" 32 "Mux32" 0 "Mux0" 1 "Mux1" ;
VAL_ 1533 UMC_a006_faultType 1 "UMC_W006_OPENED" 0 "UMC_W006_WELDED" ;
VAL_ 1533 UMC_a003_faultType 1 "UMC_W003_SELFTEST" 0 "UMC_W003_POWERON" ;
VAL_ 1533 UMC_a018_vehConnTemp 214 "UMC_SENSOR_OPENED" 215 "UMC_SENSOR_SHORTED" ;
VAL_ 1533 UMC_a019_inputTerminalsTemp 214 "UMC_SENSOR_OPENED" 215 "UMC_SENSOR_SHORTED" ;
VAL_ 1533 UMC_alertType 0 "ALERT_CLEARED" 1 "ALERT_SET" ;
VAL_ 1533 UMC_alertID 16 "UMC_a016_pcbaOTFoldback" 4 "UMC_a004_inputOverVoltage" 23 "UMC_a023_adcSelfTest" 9 "UMC_a009_vehConnOT" 17 "UMC_a017_wallPlugOTFoldback" 18 "UMC_a018_vehConnOTFoldback" 2 "UMC_a002_GFCITripped" 15 "UMC_a015_SA_Connection" 20 "UMC_a020_applicationCRC" 11 "UMC_a011_proxDisconnected" 10 "UMC_a010_inputOT" 14 "UMC_a014_SA_Genealogy" 22 "UMC_a022_criticalRAM" 1 "UMC_a001_gndMonIntrptLineSide" 3 "UMC_a003_GFCISelfTestFault" 6 "UMC_a006_contactorWelded" 12 "UMC_a012_pilotFault" 21 "UMC_a021_dataBus" 19 "UMC_a019_inputOTFoldback" 0 "UMC_ALERT_DO_NOT_USE_ZERO" 5 "UMC_a005_inputUnderVoltage" 7 "UMC_a007_pcbaOT" 8 "UMC_a008_wallPlugOT" 13 "UMC_a013_SA_Temperature" ;
VAL_ 753 VCFRONT_headlampRightTemperature -128 "SNA" ;
VAL_ 753 VCFRONT_headlampLeftTemperature -128 "SNA" ;
VAL_ 753 VCFRONT_headlampRightVoltage 255 "SNA" ;
VAL_ 753 VCFRONT_headlampLeftVoltage 255 "SNA" ;
VAL_ 753 VCFRONT_vcleftSelfTestResult 9 "EFUSE_SELF_TEST_EFUSE_RESULT_FAILED_TURN_OFF_PATH_TOO_SLOW" 4 "EFUSE_SELF_TEST_EFUSE_RESULT_FAILED_EFUSE_OUTPUT_SHORT" 1 "EFUSE_SELF_TEST_EFUSE_RESULT_RUNNING" 10 "EFUSE_SELF_TEST_EFUSE_RESULT_FAILED_NOT_LATCHED" 2 "EFUSE_SELF_TEST_EFUSE_RESULT_PASSED" 5 "EFUSE_SELF_TEST_EFUSE_RESULT_FAILED_POWER_FET_STUCK_ON" 11 "EFUSE_SELF_TEST_EFUSE_RESULT_SKIPPED" 3 "EFUSE_SELF_TEST_EFUSE_RESULT_FAILED_RAILS_UNSTABLE" 6 "EFUSE_SELF_TEST_EFUSE_RESULT_FAILED_ENABLE_LOW_MALFUNCTION" 0 "EFUSE_SELF_TEST_EFUSE_RESULT_NOT_RUN" 8 "EFUSE_SELF_TEST_EFUSE_RESULT_FAILED_ENABLE_HIGH_MALFUNCTION" 7 "EFUSE_SELF_TEST_EFUSE_RESULT_FAILED_POWER_FET_CHANNEL_OPEN" ;
VAL_ 753 VCFRONT_iBoosterSelfTestResult 9 "EFUSE_SELF_TEST_EFUSE_RESULT_FAILED_TURN_OFF_PATH_TOO_SLOW" 4 "EFUSE_SELF_TEST_EFUSE_RESULT_FAILED_EFUSE_OUTPUT_SHORT" 1 "EFUSE_SELF_TEST_EFUSE_RESULT_RUNNING" 10 "EFUSE_SELF_TEST_EFUSE_RESULT_FAILED_NOT_LATCHED" 2 "EFUSE_SELF_TEST_EFUSE_RESULT_PASSED" 5 "EFUSE_SELF_TEST_EFUSE_RESULT_FAILED_POWER_FET_STUCK_ON" 11 "EFUSE_SELF_TEST_EFUSE_RESULT_SKIPPED" 3 "EFUSE_SELF_TEST_EFUSE_RESULT_FAILED_RAILS_UNSTABLE" 6 "EFUSE_SELF_TEST_EFUSE_RESULT_FAILED_ENABLE_LOW_MALFUNCTION" 0 "EFUSE_SELF_TEST_EFUSE_RESULT_NOT_RUN" 8 "EFUSE_SELF_TEST_EFUSE_RESULT_FAILED_ENABLE_HIGH_MALFUNCTION" 7 "EFUSE_SELF_TEST_EFUSE_RESULT_FAILED_POWER_FET_CHANNEL_OPEN" ;
VAL_ 753 VCFRONT_pcsSelfTestResult 9 "EFUSE_SELF_TEST_EFUSE_RESULT_FAILED_TURN_OFF_PATH_TOO_SLOW" 4 "EFUSE_SELF_TEST_EFUSE_RESULT_FAILED_EFUSE_OUTPUT_SHORT" 1 "EFUSE_SELF_TEST_EFUSE_RESULT_RUNNING" 10 "EFUSE_SELF_TEST_EFUSE_RESULT_FAILED_NOT_LATCHED" 2 "EFUSE_SELF_TEST_EFUSE_RESULT_PASSED" 5 "EFUSE_SELF_TEST_EFUSE_RESULT_FAILED_POWER_FET_STUCK_ON" 11 "EFUSE_SELF_TEST_EFUSE_RESULT_SKIPPED" 3 "EFUSE_SELF_TEST_EFUSE_RESULT_FAILED_RAILS_UNSTABLE" 6 "EFUSE_SELF_TEST_EFUSE_RESULT_FAILED_ENABLE_LOW_MALFUNCTION" 0 "EFUSE_SELF_TEST_EFUSE_RESULT_NOT_RUN" 8 "EFUSE_SELF_TEST_EFUSE_RESULT_FAILED_ENABLE_HIGH_MALFUNCTION" 7 "EFUSE_SELF_TEST_EFUSE_RESULT_FAILED_POWER_FET_CHANNEL_OPEN" ;
VAL_ 753 VCFRONT_vcrightSelfTestResult 9 "EFUSE_SELF_TEST_EFUSE_RESULT_FAILED_TURN_OFF_PATH_TOO_SLOW" 4 "EFUSE_SELF_TEST_EFUSE_RESULT_FAILED_EFUSE_OUTPUT_SHORT" 1 "EFUSE_SELF_TEST_EFUSE_RESULT_RUNNING" 10 "EFUSE_SELF_TEST_EFUSE_RESULT_FAILED_NOT_LATCHED" 2 "EFUSE_SELF_TEST_EFUSE_RESULT_PASSED" 5 "EFUSE_SELF_TEST_EFUSE_RESULT_FAILED_POWER_FET_STUCK_ON" 11 "EFUSE_SELF_TEST_EFUSE_RESULT_SKIPPED" 3 "EFUSE_SELF_TEST_EFUSE_RESULT_FAILED_RAILS_UNSTABLE" 6 "EFUSE_SELF_TEST_EFUSE_RESULT_FAILED_ENABLE_LOW_MALFUNCTION" 0 "EFUSE_SELF_TEST_EFUSE_RESULT_NOT_RUN" 8 "EFUSE_SELF_TEST_EFUSE_RESULT_FAILED_ENABLE_HIGH_MALFUNCTION" 7 "EFUSE_SELF_TEST_EFUSE_RESULT_FAILED_POWER_FET_CHANNEL_OPEN" ;
VAL_ 753 VCFRONT_EPAS3PSelfTestResult 9 "EFUSE_SELF_TEST_EFUSE_RESULT_FAILED_TURN_OFF_PATH_TOO_SLOW" 4 "EFUSE_SELF_TEST_EFUSE_RESULT_FAILED_EFUSE_OUTPUT_SHORT" 1 "EFUSE_SELF_TEST_EFUSE_RESULT_RUNNING" 10 "EFUSE_SELF_TEST_EFUSE_RESULT_FAILED_NOT_LATCHED" 2 "EFUSE_SELF_TEST_EFUSE_RESULT_PASSED" 5 "EFUSE_SELF_TEST_EFUSE_RESULT_FAILED_POWER_FET_STUCK_ON" 11 "EFUSE_SELF_TEST_EFUSE_RESULT_SKIPPED" 3 "EFUSE_SELF_TEST_EFUSE_RESULT_FAILED_RAILS_UNSTABLE" 6 "EFUSE_SELF_TEST_EFUSE_RESULT_FAILED_ENABLE_LOW_MALFUNCTION" 0 "EFUSE_SELF_TEST_EFUSE_RESULT_NOT_RUN" 8 "EFUSE_SELF_TEST_EFUSE_RESULT_FAILED_ENABLE_HIGH_MALFUNCTION" 7 "EFUSE_SELF_TEST_EFUSE_RESULT_FAILED_POWER_FET_CHANNEL_OPEN" ;
VAL_ 753 VCFRONT_ESPMotorSelfTestResult 9 "EFUSE_SELF_TEST_EFUSE_RESULT_FAILED_TURN_OFF_PATH_TOO_SLOW" 4 "EFUSE_SELF_TEST_EFUSE_RESULT_FAILED_EFUSE_OUTPUT_SHORT" 1 "EFUSE_SELF_TEST_EFUSE_RESULT_RUNNING" 10 "EFUSE_SELF_TEST_EFUSE_RESULT_FAILED_NOT_LATCHED" 2 "EFUSE_SELF_TEST_EFUSE_RESULT_PASSED" 5 "EFUSE_SELF_TEST_EFUSE_RESULT_FAILED_POWER_FET_STUCK_ON" 11 "EFUSE_SELF_TEST_EFUSE_RESULT_SKIPPED" 3 "EFUSE_SELF_TEST_EFUSE_RESULT_FAILED_RAILS_UNSTABLE" 6 "EFUSE_SELF_TEST_EFUSE_RESULT_FAILED_ENABLE_LOW_MALFUNCTION" 0 "EFUSE_SELF_TEST_EFUSE_RESULT_NOT_RUN" 8 "EFUSE_SELF_TEST_EFUSE_RESULT_FAILED_ENABLE_HIGH_MALFUNCTION" 7 "EFUSE_SELF_TEST_EFUSE_RESULT_FAILED_POWER_FET_CHANNEL_OPEN" ;
VAL_ 753 VCFRONT_EPAS3SSelfTestResult 9 "EFUSE_SELF_TEST_EFUSE_RESULT_FAILED_TURN_OFF_PATH_TOO_SLOW" 4 "EFUSE_SELF_TEST_EFUSE_RESULT_FAILED_EFUSE_OUTPUT_SHORT" 1 "EFUSE_SELF_TEST_EFUSE_RESULT_RUNNING" 10 "EFUSE_SELF_TEST_EFUSE_RESULT_FAILED_NOT_LATCHED" 2 "EFUSE_SELF_TEST_EFUSE_RESULT_PASSED" 5 "EFUSE_SELF_TEST_EFUSE_RESULT_FAILED_POWER_FET_STUCK_ON" 11 "EFUSE_SELF_TEST_EFUSE_RESULT_SKIPPED" 3 "EFUSE_SELF_TEST_EFUSE_RESULT_FAILED_RAILS_UNSTABLE" 6 "EFUSE_SELF_TEST_EFUSE_RESULT_FAILED_ENABLE_LOW_MALFUNCTION" 0 "EFUSE_SELF_TEST_EFUSE_RESULT_NOT_RUN" 8 "EFUSE_SELF_TEST_EFUSE_RESULT_FAILED_ENABLE_HIGH_MALFUNCTION" 7 "EFUSE_SELF_TEST_EFUSE_RESULT_FAILED_POWER_FET_CHANNEL_OPEN" ;
VAL_ 753 VCFRONT_vbatFusedSelfTestResult 9 "EFUSE_SELF_TEST_EFUSE_RESULT_FAILED_TURN_OFF_PATH_TOO_SLOW" 4 "EFUSE_SELF_TEST_EFUSE_RESULT_FAILED_EFUSE_OUTPUT_SHORT" 1 "EFUSE_SELF_TEST_EFUSE_RESULT_RUNNING" 10 "EFUSE_SELF_TEST_EFUSE_RESULT_FAILED_NOT_LATCHED" 2 "EFUSE_SELF_TEST_EFUSE_RESULT_PASSED" 5 "EFUSE_SELF_TEST_EFUSE_RESULT_FAILED_POWER_FET_STUCK_ON" 11 "EFUSE_SELF_TEST_EFUSE_RESULT_SKIPPED" 3 "EFUSE_SELF_TEST_EFUSE_RESULT_FAILED_RAILS_UNSTABLE" 6 "EFUSE_SELF_TEST_EFUSE_RESULT_FAILED_ENABLE_LOW_MALFUNCTION" 0 "EFUSE_SELF_TEST_EFUSE_RESULT_NOT_RUN" 8 "EFUSE_SELF_TEST_EFUSE_RESULT_FAILED_ENABLE_HIGH_MALFUNCTION" 7 "EFUSE_SELF_TEST_EFUSE_RESULT_FAILED_POWER_FET_CHANNEL_OPEN" ;
VAL_ 753 VCFRONT_leftControllerState 2 "EFUSE_STATE_LOCKED_OUT" 0 "EFUSE_STATE_OFF" 1 "EFUSE_STATE_ON" ;
VAL_ 753 VCFRONT_ESPValveState 2 "EFUSE_STATE_LOCKED_OUT" 0 "EFUSE_STATE_OFF" 1 "EFUSE_STATE_ON" ;
VAL_ 753 VCFRONT_autopilot2State 2 "EFUSE_STATE_LOCKED_OUT" 0 "EFUSE_STATE_OFF" 1 "EFUSE_STATE_ON" ;
VAL_ 753 VCFRONT_iBoosterState 2 "EFUSE_STATE_LOCKED_OUT" 0 "EFUSE_STATE_OFF" 1 "EFUSE_STATE_ON" ;
VAL_ 753 VCFRONT_autopilot1State 2 "EFUSE_STATE_LOCKED_OUT" 0 "EFUSE_STATE_OFF" 1 "EFUSE_STATE_ON" ;
VAL_ 753 VCFRONT_ESPMotorState 2 "EFUSE_STATE_LOCKED_OUT" 0 "EFUSE_STATE_OFF" 1 "EFUSE_STATE_ON" ;
VAL_ 753 VCFRONT_EPAS3SState 2 "EFUSE_STATE_LOCKED_OUT" 0 "EFUSE_STATE_OFF" 1 "EFUSE_STATE_ON" ;
VAL_ 753 VCFRONT_EPAS3PState 2 "EFUSE_STATE_LOCKED_OUT" 0 "EFUSE_STATE_OFF" 1 "EFUSE_STATE_ON" ;
VAL_ 753 VCFRONT_rightControllerState 2 "EFUSE_STATE_LOCKED_OUT" 0 "EFUSE_STATE_OFF" 1 "EFUSE_STATE_ON" ;
VAL_ 753 VCFRONT_PCSState 2 "EFUSE_STATE_LOCKED_OUT" 0 "EFUSE_STATE_OFF" 1 "EFUSE_STATE_ON" ;
VAL_ 753 VCFRONT_eFuseDebugStatusIndex 0 "VCF_DBG_STS_VCRIGHT" 15 "VCF_DBG_STS_RAILS_A_B" 3 "VCF_DBG_STS_IBOOSTER" 14 "VCF_DBG_STS_PUMPS" 4 "VCF_DBG_STS_EPAS3P" 9 "VCF_DBG_STS_AUTOPILOT_2" 7 "VCF_DBG_STS_ESP_VALVE" 6 "VCF_DBG_STS_ESP_MOTOR" 8 "VCF_DBG_STS_AUTOPILOT_1" 5 "VCF_DBG_STS_EPAS3S" 13 "VCF_DBG_STS_VBAT_FUSED_HIGH_CURRENT" 2 "VCF_DBG_STS_PCS" 16 "VCF_DBG_STS_MISC_RAILS" 1 "VCF_DBG_STS_VCLEFT" 17 "VCF_DBG_STS_LV_BATTERY_DEBUG" 12 "VCF_DBG_STS_HEADLAMPS" 11 "VCF_DBG_STS_UI" 18 "VCF_DBG_STS_INVALID" 10 "VCF_DBG_STS_SLEEP_BYPASS" ;
VAL_ 866 VCLEFT_crashState 2 "CRASH_STATE_SEVERE" 0 "CRASH_STATE_IDLE" 1 "CRASH_STATE_MINOR" ;
VAL_ 866 VCLEFT_crashDetectedType 1 "CRASH_DETECTED_TYPE_MINOR" 0 "CRASH_DETECTED_TYPE_NONE" 2 "CRASH_DETECTED_TYPE_SEVERE" ;
VAL_ 800 BMS_matrixIndex 1 "BMS_AlertMatrix1" 2 "BMS_AlertMatrix2" 0 "BMS_AlertMatrix0" ;
VAL_ 744 EPBR_brakeDiscWipeRequest 1 "EPB_BRAKEDISCWIPE_REQUEST_LIGHT" 3 "EPB_BRAKEDISCWIPE_REQUEST_SNA" 0 "EPB_BRAKEDISCWIPE_REQUEST_NONE" 2 "EPB_BRAKEDISCWIPE_REQUEST_STRONG" ;
VAL_ 744 EPBR_cdpRequest 0 "EPB_CDP_NOT_REQUESTED" 1 "EPB_CDP_REQUESTED" ;
VAL_ 744 EPBR_telltale 0 "EPB_TELLTALE_LAMP_OFF" 2 "EPB_TELLTALE_LAMP_AMBER_ON" 3 "EPB_TELLTALE_LAMP_RED_FLASH" 1 "EPB_TELLTALE_LAMP_RED_ON" 7 "EPB_TELLTALE_SNA" ;
VAL_ 744 EPBR_systemStatus 0 "EPB_VEHICLE_STATUS_UNKNOWN" 2 "EPB_VEHICLE_STATUS_PARKED" 6 "EPB_VEHICLE_STATUS_FAULT" 3 "EPB_VEHICLE_STATUS_DYNAMIC" 1 "EPB_VEHICLE_STATUS_RELEASED" 4 "EPB_VEHICLE_STATUS_PARKING" 5 "EPB_VEHICLE_STATUS_RELEASING" 8 "EPB_VEHICLE_STATUS_MISMATCH" 7 "EPB_VEHICLE_STATUS_FAULT_SECURE" ;
VAL_ 837 PTC_infoAssemblyId 1 "ASSEMBLY1" 255 "ASSEMBLY_SNA" ;
VAL_ 837 PTC_infoBuildType 1 "INFO_PLATFORM_BUILD" 3 "INFO_TRACEABLE_CI_BUILD" 4 "INFO_MFG_BUILD" 2 "INFO_LOCAL_BUILD" 0 "INFO_UNKNOWN_BUILD" ;
VAL_ 837 PTC_infoIndex 25 "INFO_PACKAGE_PN_1_7" 30 "INFO_PACKAGE_SN_8_14" 27 "INFO_PACKAGE_PN_15_20" 0 "INFO_DEPRECATED_0" 29 "INFO_PACKAGE_SN_1_7" 10 "INFO_BUILD_HWID_COMPONENTID" 14 "INFO_BOOTLOADER_SVN" 31 "INFO_SUBCOMPONENT_GITHASH" 19 "INFO_VERSION_DEPRECATED" 7 "INFO_DEPRECATED_7" 255 "INFO_END" 9 "INFO_DEPRECATED_9" 6 "INFO_DEPRECATED_6" 20 "INFO_UDS_PROTOCOL_BOOTCRC" 3 "INFO_DEPRECATED_3" 22 "INFO_VARIANTCRC" 17 "INFO_APP_GITHASH" 8 "INFO_DEPRECATED_8" 26 "INFO_PACKAGE_PN_8_14" 5 "INFO_DEPRECATED_5" 16 "INFO_SUBCOMPONENT" 13 "INFO_APP_CRC" 2 "INFO_DEPRECATED_2" 4 "INFO_DEPRECATED_4" 15 "INFO_BOOTLOADER_CRC" 1 "INFO_DEPRECATED_1" 11 "INFO_PCBAID_ASSYID_USAGEID" 18 "INFO_BOOTLOADER_GITHASH" ;
VAL_ 551 CMP_state 15 "CMP_STATE_SNA" 2 "CMP_STATE_WAIT" 1 "CMP_STATE_NORMAL" 5 "CMP_STATE_SOFT_SHUTDOWN" 4 "CMP_STATE_SOFT_START" 0 "CMP_STATE_NONE" 3 "CMP_STATE_FAULT" ;
VAL_ 947 UI_lightSwitch 2 "LIGHT_SWITCH_PARKING" 1 "LIGHT_SWITCH_ON" 3 "LIGHT_SWITCH_OFF" 4 "LIGHT_SWITCH_SNA" 0 "LIGHT_SWITCH_AUTO" ;
VAL_ 468 PMS_checkState 1 "TRQ_CHECK_POLICING" 4 "TRQ_CHECK_CANNOT_POLICE_AT_ALL" 2 "TRQ_CHECK_CANNOT_POLICE_COMMAND" 3 "TRQ_CHECK_CANNOT_POLICE_MEASUREMENT" 0 "TRQ_CHECK_START" ;
VAL_ 468 PMS_limpRequest 2 "PM_LIMP_SYSTEM" 1 "PM_LIMP_UNIT" 0 "PM_LIMP_OK" ;
VAL_ 468 PMS_soptState 3 "SOPT_CURRENT_TEST" 1 "SOPT_PSTG_BRING_UP" 7 "SOPT_SNA" 2 "SOPT_ASC_TEST" 0 "SOPT_INIT" 6 "SOPT_TEST_FAILED" 5 "SOPT_TEST_SKIPPED" 4 "SOPT_TEST_PASSED" ;
VAL_ 468 PMS_aebRequest 0 "PM_NO_AEB_REQUEST" 1 "PM_AEB_OFF_REQUEST" ;
VAL_ 906 VCSEC_NFCReaderIndexUID 0 "BLEENDPOINT_LEFT_B_PILLAR" 3 "BLEENDPOINT_CENTER_CONSOLE" 2 "BLEENDPOINT_REAR_BUMPER" 1 "BLEENDPOINT_RIGHT_B_PILLAR" ;
VAL_ 1805 DBG_DCDC_fastCANDebugEn 0 "DBG_PCS_DCDC_FAST_CAN_NONE" 3 "DBG_PCS_DCDC_FAST_CAN_SENSE_AND_STATUS" 1 "DBG_PCS_DCDC_FAST_CAN_SENSE" 2 "DBG_PCS_DCDC_FAST_CAN_STATUS" ;
VAL_ 1805 DBG_pcs_chgDebugAuthentication 60 "DBG_PCS_SYS_OVR_ENABLE" 0 "DBG_PCS_SYS_OVR_NONE" ;
VAL_ 1805 DBG_pcs_PH_daccSelect 8 "DBG_PCS_PH_DAC_SELECT_LLC_CONTROL_VAL" 0 "DBG_PCS_PH_DAC_SELECT_NONE" 2 "DBG_PCS_PH_DAC_SELECT_INDUCTOR_I" 6 "DBG_PCS_PH_DAC_SELECT_PFC_BUS_COMMAND" 4 "DBG_PCS_PH_DAC_SELECT_PFC_DUTY" 10 "DBG_PCS_PH_DAC_SELECT_LINE_V" 9 "DBG_PCS_PH_DAC_SELECT_PFC_PLL" 7 "DBG_PCS_PH_DAC_SELECT_LLC_ENABLE" 1 "DBG_PCS_PH_DAC_SELECT_TOTAL_IREF" 3 "DBG_PCS_PH_DAC_SELECT_CAP_V_EST" 5 "DBG_PCS_PH_DAC_SELECT_PFC_BUS_ERROR" ;
VAL_ 1805 DBG_pcs_dcdcLvGtDrvEnable 1 "DBG_PCS_IO_LEVEL_HI" 0 "DBG_PCS_IO_LEVEL_LO" ;
VAL_ 1805 DBG_DCDC_subStateFaultType 0 "DCDC_CLA_SUBSTATE_FAULT" 1 "DCDC_UNSAFE_DI_VOLTAGE_SUBSTATE_FAULT" 2 "DCDC_LV_OVERVOLTAGE_SUBSTATE_FAULT" 3 "DCDC_SUBSTATE_FAULT_TYPE_MAX" ;
VAL_ 1805 DBG_pcs_PH_dacaSelect 8 "DBG_PCS_PH_DAC_SELECT_LLC_CONTROL_VAL" 0 "DBG_PCS_PH_DAC_SELECT_NONE" 2 "DBG_PCS_PH_DAC_SELECT_INDUCTOR_I" 6 "DBG_PCS_PH_DAC_SELECT_PFC_BUS_COMMAND" 4 "DBG_PCS_PH_DAC_SELECT_PFC_DUTY" 10 "DBG_PCS_PH_DAC_SELECT_LINE_V" 9 "DBG_PCS_PH_DAC_SELECT_PFC_PLL" 7 "DBG_PCS_PH_DAC_SELECT_LLC_ENABLE" 1 "DBG_PCS_PH_DAC_SELECT_TOTAL_IREF" 3 "DBG_PCS_PH_DAC_SELECT_CAP_V_EST" 5 "DBG_PCS_PH_DAC_SELECT_PFC_BUS_ERROR" ;
VAL_ 1805 DBG_pcs_5VL1Enable 1 "DBG_PCS_IO_LEVEL_HI" 0 "DBG_PCS_IO_LEVEL_LO" ;
VAL_ 1805 DBG_pcs_analogMuxInhibitInv 1 "DBG_PCS_IO_LEVEL_HI" 0 "DBG_PCS_IO_LEVEL_LO" ;
VAL_ 1805 DBG_pcs_chgGridConfigToOvr 3 "PHASE_CONFIG_THREE_PHASE_DELTA" 1 "PHASE_CONFIG_SINGLE_PHASE" 4 "PHASE_CONFIG_SINGLE_PHASE_IEC_GB" 5 "PHASE_CONFIG_MFG_TEST_CONFIG_1" 2 "PHASE_CONFIG_THREE_PHASE" 0 "PHASE_CONFIG_SNA" 7 "PHASE_CONFIG_RELIABILITY_SINGLE_PHASE" 6 "PHASE_CONFIG_MFG_TEST_CONFIG_2" 8 "PHASE_CONFIG_TOTAL_NUM" ;
VAL_ 1805 DBG_pcs_analogMuxSelC 1 "DBG_PCS_IO_LEVEL_HI" 0 "DBG_PCS_IO_LEVEL_LO" ;
VAL_ 1805 DBG_pcs_phCLogicPwrEnable 1 "DBG_PCS_IO_LEVEL_HI" 0 "DBG_PCS_IO_LEVEL_LO" ;
VAL_ 1805 DBG_pcs_analogMuxSelB 1 "DBG_PCS_IO_LEVEL_HI" 0 "DBG_PCS_IO_LEVEL_LO" ;
VAL_ 1805 DBG_pcs_PH_daccPhaseSelect 1 "PHB" 2 "PHC" 3 "PH_NUM" 0 "PHA" ;
VAL_ 1805 DBG_pcs_phBLogicPwrEnable 1 "DBG_PCS_IO_LEVEL_HI" 0 "DBG_PCS_IO_LEVEL_LO" ;
VAL_ 1805 DBG_pcs_phALogicPwrEnable 1 "DBG_PCS_IO_LEVEL_HI" 0 "DBG_PCS_IO_LEVEL_LO" ;
VAL_ 1805 DBG_pcs_envOverrideValue 5 "PCS_NUM_ENVIRONMENTS" 3 "ENV_DC_CIRCULATION_ALLOW" 1 "ENV_MFG_EOL" 0 "ENV_VEHICLE" 4 "ENV_HIL_TESTER" 2 "ENV_MFG_BOARD_BRINGUP" ;
VAL_ 1805 DBG_pcs_analogMuxSelA 1 "DBG_PCS_IO_LEVEL_HI" 0 "DBG_PCS_IO_LEVEL_LO" ;
VAL_ 1805 DBG_pcs_DCDC_dcdcMode 1 "SUPPORT" 0 "SHUTDOWN" 3 "DISCHARGE" 2 "PRECHARGE" ;
VAL_ 1805 DBG_DCDC_subStateFaultTarget 13 "DCDC_SUBSTATE_DIS_HVBUS_FAULTED" 4 "DCDC_SUBSTATE_PCHG_FAST_DIS_HVBUS" 15 "DCDC_SUBSTATE_CLEAR_FAULTS" 7 "DCDC_SUBSTATE_PCHG_DWELL_WAIT" 12 "DCDC_SUBSTATE_12V_SUPPORT_FAULTED" 8 "DCDC_SUBSTATE_PCHG_DI_RECOVERY_WAIT" 17 "DCDC_SUBSTATE_NUM" 10 "DCDC_SUBSTATE_PCHG_FLT_FAST_DIS_HVBUS" 2 "DCDC_SUBSTATE_12V_SUPPORT_ACTIVE" 3 "DCDC_SUBSTATE_DIS_HVBUS" 14 "DCDC_SUBSTATE_PCHG_FAULTED" 11 "DCDC_SUBSTATE_SHUTDOWN" 1 "DCDC_SUBSTATE_STANDBY" 9 "DCDC_SUBSTATE_PCHG_ACTIVE" 16 "DCDC_SUBSTATE_FAULTED" 6 "DCDC_SUBSTATE_PCHG_DWELL_CHARGE" 5 "DCDC_SUBSTATE_PCHG_SLOW_DIS_HVBUS" 0 "DCDC_SUBSTATE_PWR_UP_INIT" ;
VAL_ 1805 DBG_pcs_PH_dacaPhaseSelect 1 "PHB" 2 "PHC" 3 "PH_NUM" 0 "PHA" ;
VAL_ 1805 DBG_pcsControlSel 35 "DBG_PCS_CHG_SYSTEM_OVERRIDE" 150 "DBG_PCS_ANALOG_MUX_CONTROL" 114 "DBG_PCS_DCDC_SLOW_DISCHARGE_CTRL" 103 "DCDC_RECTIFY_PARAMETERS" 106 "DCDC_DEBUG_FLOAT_PARAMETERS" 24 "DBG_PCS_PHB_LLC_CONTROL" 6 "DBG_PCS_PH_CONTROL_PARAMS" 37 "DBG_PCS_PHB_SYSTEM_OVERRIDE" 101 "DCDC_COMPARATOR" 104 "DCDC_SNUBBER_PARAMETERS" 33 "DBG_PCS_PHC_PFC_CONTROL" 38 "DBG_PCS_PHC_SYSTEM_OVERRIDE" 102 "DCDC_DRIVE_PARAMETERS" 23 "DBG_PCS_PHB_PFC_CONTROL" 100 "DBG_PCS_DCDC_CONTROL" 113 "DBG_PCS_DCDC_HIL_TEST_OVERRIDE" 14 "DBG_PCS_PHA_LLC_CONTROL" 108 "DCDC_VTANK_CONTROL_PARAMETERS" 32 "DBG_PCS_PHC_CLOSED_LOOP_CONTROL" 5 "DBG_PCS_PH_ALL" 39 "DBG_PCS_ENVIRONMENT_OVERRIDE" 107 "DCDC_DEBUG_INT_PARAMETERS" 13 "DBG_PCS_PHA_PFC_CONTROL" 22 "DBG_PCS_PHB_CLOSED_LOOP_CONTROL" 111 "DBG_PCS_DCDC_SYSTEM_CMD_OVERRIDE" 110 "DBG_PCS_DCDC_SYS_TEST_OVERRIDE" 109 "DCDC_CPU_VREG_CONTROL" 112 "DBG_PCS_DCDC_SUBSTATE_FAULT" 7 "DBG_PCS_PH_CONTROL_PARAMS2" 9 "DBG_PCS_PH_INT_BUS_CONTROL" 105 "DCDC_VLOOP_CONTROL_PARAMETERS_1" 34 "DBG_PCS_PHC_LLC_CONTROL" 12 "DBG_PCS_PHA_CLOSED_LOOP_CONTROL" 8 "DBG_PCS_PH_DC_CIRCULATION_CONTROL" 36 "DBG_PCS_PHA_SYSTEM_OVERRIDE" ;
VAL_ 290 VCLEFT_rearHandleDebounceStatus 4 "EXTERIOR_HANDLE_STATUS_DISCONNECTED" 5 "EXTERIOR_HANDLE_STATUS_FAULT" 1 "EXTERIOR_HANDLE_STATUS_INDETERMINATE" 3 "EXTERIOR_HANDLE_STATUS_ACTIVE" 0 "EXTERIOR_HANDLE_STATUS_SNA" 2 "EXTERIOR_HANDLE_STATUS_NOT_ACTIVE" ;
VAL_ 290 VCLEFT_frontHandleDebounceStatus 4 "EXTERIOR_HANDLE_STATUS_DISCONNECTED" 5 "EXTERIOR_HANDLE_STATUS_FAULT" 1 "EXTERIOR_HANDLE_STATUS_INDETERMINATE" 3 "EXTERIOR_HANDLE_STATUS_ACTIVE" 0 "EXTERIOR_HANDLE_STATUS_SNA" 2 "EXTERIOR_HANDLE_STATUS_NOT_ACTIVE" ;
VAL_ 290 VCLEFT_rearHandleRawStatus 4 "EXTERIOR_HANDLE_STATUS_DISCONNECTED" 5 "EXTERIOR_HANDLE_STATUS_FAULT" 1 "EXTERIOR_HANDLE_STATUS_INDETERMINATE" 3 "EXTERIOR_HANDLE_STATUS_ACTIVE" 0 "EXTERIOR_HANDLE_STATUS_SNA" 2 "EXTERIOR_HANDLE_STATUS_NOT_ACTIVE" ;
VAL_ 290 VCLEFT_frontHandleRawStatus 4 "EXTERIOR_HANDLE_STATUS_DISCONNECTED" 5 "EXTERIOR_HANDLE_STATUS_FAULT" 1 "EXTERIOR_HANDLE_STATUS_INDETERMINATE" 3 "EXTERIOR_HANDLE_STATUS_ACTIVE" 0 "EXTERIOR_HANDLE_STATUS_SNA" 2 "EXTERIOR_HANDLE_STATUS_NOT_ACTIVE" ;
VAL_ 290 VCLEFT_rearDoorState 2 "DOOR_STATE_WAIT_FOR_SHORT_DROP" 1 "DOOR_STATE_CLOSED" 4 "DOOR_STATE_OPEN_OR_AJAR" 3 "DOOR_STATE_RELEASING_LATCH" 0 "DOOR_STATE_UNKNOWN" ;
VAL_ 290 VCLEFT_frontDoorState 2 "DOOR_STATE_WAIT_FOR_SHORT_DROP" 1 "DOOR_STATE_CLOSED" 4 "DOOR_STATE_OPEN_OR_AJAR" 3 "DOOR_STATE_RELEASING_LATCH" 0 "DOOR_STATE_UNKNOWN" ;
